VERSION ""

NS_ :

BS_:

BU_: IFV_VFP External_Tool IFV_Host MRR

BO_ 3221225472 VECTOR__INDEPENDENT_SIG_MSG: 0 Vector__XXX
 SG_ CAN_SERV_ALIGN_UPDATES_DONE : 0|8@0+ (1,0) [0|255] "" Vector__XXX
 SG_ CAN_SENSOR_VANGLE_OFFSET : 0|8@0+ (0.0625,-8) [-8|7.9375] "deg" Vector__XXX
 SG_ CAN_SENSOR_FOV_VER : 0|8@0+ (1,0) [0|255] "deg" Vector__XXX
 SG_ CAN_AUTO_ALIGN_VANGLE_QF : 0|1@0+ (1,0) [0|1] "" Vector__XXX
 SG_ CAN_AUTO_ALIGN_VANGLE_REF : 0|10@0+ (0.03125,-10) [-10|21.96875] "deg" Vector__XXX
 SG_ CAN_AUTO_ALIGN_VANGLE : 0|10@0+ (0.03125,-10) [-10|21.96875] "deg" Vector__XXX
 SG_ CAN_MMIC_Temp4 : 0|8@0+ (1,-50) [-50|205] "C" Vector__XXX
 SG_ CAN_MMIC_Temp3 : 0|8@0+ (1,-50) [-50|205] "C" Vector__XXX
 SG_ CAN_MMIC_Temp2 : 0|8@0+ (1,-50) [-50|205] "C" Vector__XXX
 SG_ CAN_Processor_Temp2 : 0|8@0+ (1,-50) [-50|205] "C" Vector__XXX
 SG_ CAN_CHECKSUM : 0|8@0+ (1,0) [0|255] "" Vector__XXX
 SG_ CAN_COUNTER : 0|4@0+ (1,0) [0|15] "" Vector__XXX
 SG_ CAN_VEHICLE_MODE : 0|4@0+ (1,0) [0|15] "" Vector__XXX
 SG_ CAN_USC_CAL_VER_MAJOR : 0|16@0+ (1,0) [0|65535] "" Vector__XXX
 SG_ CAN_USC_CAL_VER_MINOR : 0|16@0+ (1,0) [0|65535] "" Vector__XXX
 SG_ CAN_SMC_CAL_VER_MAJOR : 0|16@0+ (1,0) [0|65535] "" Vector__XXX
 SG_ CAN_HW_VERSION : 0|32@0+ (1,0) [0|4294967295] "" Vector__XXX
 SG_ CAN_FAC_TGT_MTG_SPACE_VER : 0|8@0+ (1,-128) [-128|127] "cm" Vector__XXX
 SG_ CAN_ANGLE_MISALIGNMENT_VER : 0|10@0+ (0.03125,-10) [-10|21.96875] "deg" Vector__XXX
 SG_ CAN_ANGLE_MOUNTING_VOFFSET : 0|8@0+ (0.0625,-8) [-8|7.9375] "deg" Vector__XXX
 SG_ CAN_LATCH_FAULTS : 0|64@0+ (1,0) [0|100] "" Vector__XXX
 SG_ CAN_ACTIVE_FAULTS : 0|64@0+ (1,0) [0|1.8446744074E+019] "" Vector__XXX
 SG_ CAN_HISTORY_FAULTS : 0|64@0+ (1,0) [0|1.8446744074E+019] "" Vector__XXX
 SG_ CAN_SERV_ALIGN_ENABLE : 0|1@0+ (1,0) [0|1] "" Vector__XXX
 SG_ CAN_LONG_MOUNTING_OFFSET : 0|8@0+ (0.015625,-2) [-2|1.984375] "" Vector__XXX
 SG_ CAN_BEAMWIDTH_VERT : 0|7@0+ (0.125,0) [0|15.875] "deg" Vector__XXX
 SG_ CAN_VEHICLE_SPEED_CALC_QF : 0|2@0+ (1,0) [0|3] "" Vector__XXX
 SG_ CAN_SMC_CAL_VER_MAJOR : 0|16@0+ (1,0) [0|65535] "" Vector__XXX
 SG_ v1_8_SupplyOutofRange_A_b3_4 : 0|1@0+ (1,0) [0|1] "" Vector__XXX
 SG_ v1_8_SupplyOutofRange_H_b3_4 : 0|1@0+ (1,0) [0|1] "" Vector__XXX
 SG_ Radar_Internal_Error_A_b7_7 : 0|1@0+ (1,0) [0|1] "" Vector__XXX
 SG_ DSP_to_Host_ChksumFault_A_b7_5 : 0|1@0+ (1,0) [0|1] "" Vector__XXX
 SG_ Host_to_DSP_ChksumFault_A_b7_4 : 0|1@0+ (1,0) [0|1] "" Vector__XXX
 SG_ ARM_to_DSP_ChksumFault_A_b7_3 : 0|1@0+ (1,0) [0|1] "" Vector__XXX
 SG_ DSP_to_ARM_ChksumFault_A_b7_2 : 0|1@0+ (1,0) [0|1] "" Vector__XXX
 SG_ Host_to_ARM_ChksumFault_A_b7_1 : 0|1@0+ (1,0) [0|1] "" Vector__XXX
 SG_ ARM_to_Host_ChksumFault_A_b7_0 : 0|1@0+ (1,0) [0|1] "" Vector__XXX
 SG_ LoopBwOutofRange_A_b6_7 : 0|1@0+ (1,0) [0|1] "" Vector__XXX
 SG_ DSPLoopOverrunFault_A_b6_6 : 0|1@0+ (1,0) [0|1] "" Vector__XXX
 SG_ TuningSensitivityFault_A_b6_4 : 0|1@0+ (1,0) [0|1] "" Vector__XXX
 SG_ SatTuningFreqFault_A_b6_3 : 0|1@0+ (1,0) [0|1] "" Vector__XXX
 SG_ LocalOscPwrFault_A_b6_2 : 0|1@0+ (1,0) [0|1] "" Vector__XXX
 SG_ TransmitterPwrFault_A_b6_1 : 0|1@0+ (1,0) [0|1] "" Vector__XXX
 SG_ XCVRDevSpiFault_A_b5_5 : 0|1@0+ (1,0) [0|1] "" Vector__XXX
 SG_ FreqSynthDevSpiFault_A_b5_4 : 0|1@0+ (1,0) [0|1] "" Vector__XXX
 SG_ AmpDevSpiFault_A_b5_3 : 0|1@0+ (1,0) [0|1] "" Vector__XXX
 SG_ Sidelobe_Blockage_A_b5_2 : 0|1@0+ (1,0) [0|1] "" Vector__XXX
 SG_ TD_Blockage_A_b5_1 : 0|1@0+ (1,0) [0|1] "" Vector__XXX
 SG_ CW_MNR_Blockage_A_b5_0 : 0|1@0+ (1,0) [0|1] "" Vector__XXX
 SG_ ECUTempHighFault_A_b4_7 : 0|1@0+ (1,0) [0|1] "" Vector__XXX
 SG_ TransmitterTempHigh_A_b4_6 : 0|1@0+ (1,0) [0|1] "" Vector__XXX
 SG_ AlignRoutineFailed_A_b4_5 : 0|1@0+ (1,0) [0|1] "" Vector__XXX
 SG_ UnreasonableRadarData_A_b4_4 : 0|1@0+ (1,0) [0|1] "" Vector__XXX
 SG_ MicroPTempHighFault_A_b4_3 : 0|1@0+ (1,0) [0|1] "" Vector__XXX
 SG_ VertAlignOutofRange_A_b4_2 : 0|1@0+ (1,0) [0|1] "" Vector__XXX
 SG_ HorzAlignOutofRange_A_b4_1 : 0|1@0+ (1,0) [0|1] "" Vector__XXX
 SG_ FactAlignMode_A_b4_0 : 0|1@0+ (1,0) [0|1] "" Vector__XXX
 SG_ BatteryLowFault_A_b3_7 : 0|1@0+ (1,0) [0|1] "" Vector__XXX
 SG_ BatteryHighFault_A_b3_6 : 0|1@0+ (1,0) [0|1] "" Vector__XXX
 SG_ v1_25_SupplyOutofRange_A_b3_5 : 0|1@0+ (1,0) [0|1] "" Vector__XXX
 SG_ ThermistorOutofRange_A_b3_3 : 0|1@0+ (1,0) [0|1] "" Vector__XXX
 SG_ v3_3_DacSpOutofRange_A_b3_2 : 0|1@0+ (1,0) [0|1] "" Vector__XXX
 SG_ v3_3_RawSpOutofRange_A_b3_1 : 0|1@0+ (1,0) [0|1] "" Vector__XXX
 SG_ v5_0_SupplyOutofRange_A_b3_0 : 0|1@0+ (1,0) [0|1] "" Vector__XXX
 SG_ TransmitterIDFault_A_b2_7 : 0|1@0+ (1,0) [0|1] "" Vector__XXX
 SG_ VFPPCANDataRangeChkFault_A_b2_3 : 0|1@0+ (1,0) [0|1] "" Vector__XXX
 SG_ VFPPCANMissingMsgFault_A_b2_2 : 0|1@0+ (1,0) [0|1] "" Vector__XXX
 SG_ HostPCANMissingMsgFault_A_b2_1 : 0|1@0+ (1,0) [0|1] "" Vector__XXX
 SG_ PCANBusOffFault_A_b2_0 : 0|1@0+ (1,0) [0|1] "" Vector__XXX
 SG_ InstructSetChkFault_A_b1_5 : 0|1@0+ (1,0) [0|1] "" Vector__XXX
 SG_ StackOvflowFault_A_b1_4 : 0|1@0+ (1,0) [0|1] "" Vector__XXX
 SG_ WatchdogFault_A_b1_3 : 0|1@0+ (1,0) [0|1] "" Vector__XXX
 SG_ PLLLockFault_A_b1_2 : 0|1@0+ (1,0) [0|1] "" Vector__XXX
 SG_ RAMMemTestFault_A_b1_0 : 0|1@0+ (1,0) [0|1] "" Vector__XXX
 SG_ USCValFault_A_b0_7 : 0|1@0+ (1,0) [0|1] "" Vector__XXX
 SG_ ClkMonFailFault_A_b0_6 : 0|1@0+ (1,0) [0|1] "" Vector__XXX
 SG_ PgmFlowFault_A_b0_5 : 0|1@0+ (1,0) [0|1] "" Vector__XXX
 SG_ SMCChksumFault_A_b0_4 : 0|1@0+ (1,0) [0|1] "" Vector__XXX
 SG_ KAMChksumFault_A_b0_2 : 0|1@0+ (1,0) [0|1] "" Vector__XXX
 SG_ ProgCalFlashChksumFault_A_b0_1 : 0|1@0+ (1,0) [0|1] "" Vector__XXX
 SG_ AppFlashChksumFault_A_b0_0 : 0|1@0+ (1,0) [0|1] "" Vector__XXX
 SG_ CB_140_IMUXAxisClbrtdNL_A_bB_7 : 0|1@0+ (1,0) [0|1] "" Vector__XXX
 SG_ CB_130_IMULonAccSecV_A_bB_6 : 0|1@0+ (1,0) [0|1] "" Vector__XXX
 SG_ CB_140_IMULatACCSecV_A_bB_5 : 0|1@0+ (1,0) [0|1] "" Vector__XXX
 SG_ CB_140_IMUDataMsk_A_bB_4 : 0|1@0+ (1,0) [0|1] "" Vector__XXX
 SG_ Host_CB_CAN_BusOff_A_bB_3 : 0|1@0+ (1,0) [0|1] "" Vector__XXX
 SG_ HighDeltaMisalign_A_bB_2 : 0|1@0+ (1,0) [0|1] "" Vector__XXX
 SG_ CB_170_ABS_Missing_A_bB_1 : 0|1@0+ (1,0) [0|1] "" Vector__XXX
 SG_ Unexpected_Reset_Fault_A_bB_0 : 0|1@0+ (1,0) [0|1] "" Vector__XXX
 SG_ CB_140_IMULatAccSecAval_A_bA_7 : 0|1@0+ (1,0) [0|1] "" Vector__XXX
 SG_ CB_130_IMUYawRtSecAval_A_bA_6 : 0|1@0+ (1,0) [0|1] "" Vector__XXX
 SG_ CB_130_IMULonAccSecAval_A_bA_5 : 0|1@0+ (1,0) [0|1] "" Vector__XXX
 SG_ CB_140_IMUChksumSecProt_A_bA_1 : 0|1@0+ (1,0) [0|1] "" Vector__XXX
 SG_ CB_130_IMUChksumPriProt_A_bA_0 : 0|1@0+ (1,0) [0|1] "" Vector__XXX
 SG_ VINNotProg_A_b9_7 : 0|1@0+ (1,0) [0|1] "" Vector__XXX
 SG_ VehConfigNotProg_A_b9_6 : 0|1@0+ (1,0) [0|1] "" Vector__XXX
 SG_ VIN_Mismatch_A_b9_5 : 0|1@0+ (1,0) [0|1] "" Vector__XXX
 SG_ CB_140_IMUYawRtSecV_A_b9_4 : 0|1@0+ (1,0) [0|1] "" Vector__XXX
 SG_ CB_140_IMULonAccPriV_A_b9_3 : 0|1@0+ (1,0) [0|1] "" Vector__XXX
 SG_ CB_130_IMULonAccPriAval_A_b9_2 : 0|1@0+ (1,0) [0|1] "" Vector__XXX
 SG_ CB_130_IMULatAccPrimV_A_b9_0 : 0|1@0+ (1,0) [0|1] "" Vector__XXX
 SG_ CB_130_IMUYawRtPriV_A_b9_1 : 0|1@0+ (1,0) [0|1] "" Vector__XXX
 SG_ Cam_202_SysYawRtV_A_b8_7 : 0|1@0+ (1,0) [0|1] "" Vector__XXX
 SG_ Cam_020_SysYawRtV_A_b8_6 : 0|1@0+ (1,0) [0|1] "" Vector__XXX
 SG_ Host_020_SysVehSpdV_A_b8_5 : 0|1@0+ (1,0) [0|1] "" Vector__XXX
 SG_ CB_140_IMURollCntSecARC_A_b8_4 : 0|1@0+ (1,0) [0|1] "" Vector__XXX
 SG_ CB_130_IMURollCntPriARC_A_b8_3 : 0|1@0+ (1,0) [0|1] "" Vector__XXX
 SG_ CB_140_IMUYawLonAccMiss_A_b8_2 : 0|1@0+ (1,0) [0|1] "" Vector__XXX
 SG_ CB_130_IMUYawLatAccMiss_A_b8_1 : 0|1@0+ (1,0) [0|1] "" Vector__XXX
 SG_ CB_140_IMUXAxisClbrtdNL_H_bB_7 : 0|1@0+ (1,0) [0|1] "" Vector__XXX
 SG_ CB_130_IMULonAccSecV_H_bB_6 : 0|1@0+ (1,0) [0|1] "" Vector__XXX
 SG_ CB_140_IMULatACCSecV_H_bB_5 : 0|1@0+ (1,0) [0|1] "" Vector__XXX
 SG_ CB_140_IMUDataMsk_H_bB_4 : 0|1@0+ (1,0) [0|1] "" Vector__XXX
 SG_ Host_CB_CAN_BusOff_H_bB_3 : 0|1@0+ (1,0) [0|1] "" Vector__XXX
 SG_ HighDeltaMisalign_H_bB_2 : 0|1@0+ (1,0) [0|1] "" Vector__XXX
 SG_ CB_170_ABS_Missing_H_bB_1 : 0|1@0+ (1,0) [0|1] "" Vector__XXX
 SG_ Unexpected_Reset_Fault_H_bB_0 : 0|1@0+ (1,0) [0|1] "" Vector__XXX
 SG_ CB_140_IMULatAccSecAval_H_bA_7 : 0|1@0+ (1,0) [0|1] "" Vector__XXX
 SG_ CB_130_IMUYawRtSecAval_H_bA_6 : 0|1@0+ (1,0) [0|1] "" Vector__XXX
 SG_ CB_130_IMULonAccSecAval_H_bA_5 : 0|1@0+ (1,0) [0|1] "" Vector__XXX
 SG_ CB_140_IMUChksumSecProt_H_bA_1 : 0|1@0+ (1,0) [0|1] "" Vector__XXX
 SG_ CB_130_IMUChksumPriProt_H_bA_0 : 0|1@0+ (1,0) [0|1] "" Vector__XXX
 SG_ VINNotProg_H_b9_7 : 0|1@0+ (1,0) [0|1] "" Vector__XXX
 SG_ VehConfigNotProg_H_b9_6 : 0|1@0+ (1,0) [0|1] "" Vector__XXX
 SG_ VIN_Mismatch_H_b9_5 : 0|1@0+ (1,0) [0|1] "" Vector__XXX
 SG_ CB_140_IMUYawRtSecV_H_b9_4 : 0|1@0+ (1,0) [0|1] "" Vector__XXX
 SG_ CB_140_IMULonAccPriV_H_b9_3 : 0|1@0+ (1,0) [0|1] "" Vector__XXX
 SG_ CB_130_IMULonAccPriAval_H_b9_2 : 0|1@0+ (1,0) [0|1] "" Vector__XXX
 SG_ CB_130_IMULatAccPrimV_H_b9_0 : 0|1@0+ (1,0) [0|1] "" Vector__XXX
 SG_ CB_130_IMUYawRtPriV_H_b9_1 : 0|1@0+ (1,0) [0|1] "" Vector__XXX
 SG_ Cam_202_SysYawRtV_H_b8_7 : 0|1@0+ (1,0) [0|1] "" Vector__XXX
 SG_ Cam_020_SysYawRtV_H_b8_6 : 0|1@0+ (1,0) [0|1] "" Vector__XXX
 SG_ Host_020_SysVehSpdV_H_b8_5 : 0|1@0+ (1,0) [0|1] "" Vector__XXX
 SG_ CB_140_IMURollCntSecARC_H_b8_4 : 0|1@0+ (1,0) [0|1] "" Vector__XXX
 SG_ CB_130_IMURollCntPriARC_H_b8_3 : 0|1@0+ (1,0) [0|1] "" Vector__XXX
 SG_ CB_140_IMUYawLonAccMiss_H_b8_2 : 0|1@0+ (1,0) [0|1] "" Vector__XXX
 SG_ CB_130_IMUYawLatAccMiss_H_b8_1 : 0|1@0+ (1,0) [0|1] "" Vector__XXX
 SG_ Radar_Internal_Error_H_b7_7 : 0|1@0+ (1,0) [0|1] "" Vector__XXX
 SG_ DSP_to_Host_ChksumFault_H_b7_5 : 0|1@0+ (1,0) [0|1] "" Vector__XXX
 SG_ Host_to_DSP_ChksumFault_H_b7_4 : 0|1@0+ (1,0) [0|1] "" Vector__XXX
 SG_ ARM_to_DSP_ChksumFault_H_b7_3 : 0|1@0+ (1,0) [0|1] "" Vector__XXX
 SG_ DSP_to_ARM_ChksumFault_H_b7_2 : 0|1@0+ (1,0) [0|1] "" Vector__XXX
 SG_ Host_to_ARM_ChksumFault_H_b7_1 : 0|1@0+ (1,0) [0|1] "" Vector__XXX
 SG_ ARM_to_Host_ChksumFault_H_b7_0 : 0|1@0+ (1,0) [0|1] "" Vector__XXX
 SG_ LoopBwOutofRange_H_b6_7 : 0|1@0+ (1,0) [0|1] "" Vector__XXX
 SG_ DSPLoopOverrunFault_H_b6_6 : 0|1@0+ (1,0) [0|1] "" Vector__XXX
 SG_ TuningSensitivityFault_H_b6_4 : 0|1@0+ (1,0) [0|1] "" Vector__XXX
 SG_ SatTuningFreqFault_H_b6_3 : 0|1@0+ (1,0) [0|1] "" Vector__XXX
 SG_ LocalOscPwrFault_H_b6_2 : 0|1@0+ (1,0) [0|1] "" Vector__XXX
 SG_ TransmitterPwrFault_H_b6_1 : 0|1@0+ (1,0) [0|1] "" Vector__XXX
 SG_ XCVRDevSpiFault_H_b5_5 : 0|1@0+ (1,0) [0|1] "" Vector__XXX
 SG_ FreqSynthDevSpiFault_H_b5_4 : 0|1@0+ (1,0) [0|1] "" Vector__XXX
 SG_ AmpDevSpiFault_H_b5_3 : 0|1@0+ (1,0) [0|1] "" Vector__XXX
 SG_ Sidelobe_Blockage_H_b5_2 : 0|1@0+ (1,0) [0|1] "" Vector__XXX
 SG_ TD_Blockage_H_b5_1 : 0|1@0+ (1,0) [0|1] "" Vector__XXX
 SG_ CW_MNR_Blockage_H_b5_0 : 0|1@0+ (1,0) [0|1] "" Vector__XXX
 SG_ ECUTempHighFault_H_b4_7 : 0|1@0+ (1,0) [0|1] "" Vector__XXX
 SG_ TransmitterTempHigh_H_b4_6 : 0|1@0+ (1,0) [0|1] "" Vector__XXX
 SG_ AlignRoutineFailed_H_b4_5 : 0|1@0+ (1,0) [0|1] "" Vector__XXX
 SG_ UnreasonableRadarData_H_b4_4 : 0|1@0+ (1,0) [0|1] "" Vector__XXX
 SG_ MicroPTempHighFault_H_b4_3 : 0|1@0+ (1,0) [0|1] "" Vector__XXX
 SG_ VertAlignOutofRange_H_b4_2 : 0|1@0+ (1,0) [0|1] "" Vector__XXX
 SG_ HorzAlignOutofRange_H_b4_1 : 0|1@0+ (1,0) [0|1] "" Vector__XXX
 SG_ FactAlignMode_H_b4_0 : 0|1@0+ (1,0) [0|1] "" Vector__XXX
 SG_ BatteryLowFault_H_b3_7 : 0|1@0+ (1,0) [0|1] "" Vector__XXX
 SG_ BatteryHighFault_H_b3_6 : 0|1@0+ (1,0) [0|1] "" Vector__XXX
 SG_ v1_25_SupplyOutofRange_H_b3_5 : 0|1@0+ (1,0) [0|1] "" Vector__XXX
 SG_ ThermistorOutofRange_H_b3_3 : 0|1@0+ (1,0) [0|1] "" Vector__XXX
 SG_ v3_3_DacSpOutofRange_H_b3_2 : 0|1@0+ (1,0) [0|1] "" Vector__XXX
 SG_ v3_3_RawSpOutofRange_H_b3_1 : 0|1@0+ (1,0) [0|1] "" Vector__XXX
 SG_ v5_0_SupplyOutofRange_H_b3_0 : 0|1@0+ (1,0) [0|1] "" Vector__XXX
 SG_ TransmitterIDFault_H_b2_7 : 0|1@0+ (1,0) [0|1] "" Vector__XXX
 SG_ VFPPCANDataRangeChkFault_H_b2_3 : 0|1@0+ (1,0) [0|1] "" Vector__XXX
 SG_ VFPPCANMissingMsgFault_H_b2_2 : 0|1@0+ (1,0) [0|1] "" Vector__XXX
 SG_ HostPCANMissingMsgFault_H_b2_1 : 0|1@0+ (1,0) [0|1] "" Vector__XXX
 SG_ PCANBusOffFault_H_b2_0 : 0|1@0+ (1,0) [0|1] "" Vector__XXX
 SG_ InstructSetChkFault_H_b1_5 : 0|1@0+ (1,0) [0|1] "" Vector__XXX
 SG_ StackOvflowFault_H_b1_4 : 0|1@0+ (1,0) [0|1] "" Vector__XXX
 SG_ WatchdogFault_H_b1_3 : 0|1@0+ (1,0) [0|1] "" Vector__XXX
 SG_ PLLLockFault_H_b1_2 : 0|1@0+ (1,0) [0|1] "" Vector__XXX
 SG_ RAMMemTestFault_H_b1_0 : 0|1@0+ (1,0) [0|1] "" Vector__XXX
 SG_ USCValFault_H_b0_7 : 0|1@0+ (1,0) [0|1] "" Vector__XXX
 SG_ ClkMonFailFault_H_b0_6 : 0|1@0+ (1,0) [0|1] "" Vector__XXX
 SG_ PgmFlowFault_H_b0_5 : 0|1@0+ (1,0) [0|1] "" Vector__XXX
 SG_ SMCChksumFault_H_b0_4 : 0|1@0+ (1,0) [0|1] "" Vector__XXX
 SG_ KAMChksumFault_H_b0_2 : 0|1@0+ (1,0) [0|1] "" Vector__XXX
 SG_ ProgCalFlashChksumFault_H_b0_1 : 0|1@0+ (1,0) [0|1] "" Vector__XXX
 SG_ AppFlashChksumFault_H_b0_0 : 0|1@0+ (1,0) [0|1] "" Vector__XXX
 SG_ FSRACCBrkngReqDenied : 0|1@0+ (1,0) [0|1] "" Vector__XXX
 SG_ BrkSysExtHldCpbltyFld : 0|1@0+ (1,0) [0|1] "" Vector__XXX
 SG_ BrkSysAutBrkTrgtDclV : 0|1@0+ (1,0) [0|1] "" Vector__XXX
 SG_ BrkSysAutBrkActDclV : 0|1@0+ (1,0) [0|1] "" Vector__XXX
 SG_ BrkSysPlsStat : 0|2@0+ (1,0) [0|3] "" Vector__XXX
 SG_ VehMvngStat : 0|1@0+ (1,0) [0|1] "" Vector__XXX
 SG_ BrkSysAutBrkStat : 0|2@0+ (1,0) [0|3] "" Vector__XXX
 SG_ AvgWhlBrkPrstEst : 0|17@0+ (0.1,0) [0|13107.1] "kPa" Vector__XXX
 SG_ BrkSysAutBrkActDcl : 0|12@0- (0.01,0) [-20.48|20.47] "m/s^2" Vector__XXX
 SG_ BrkSysAutBrkTrgtDcl : 0|12@0- (0.01,0) [-20.48|20.47] "m/s^2" Vector__XXX
 SG_ MRR_IMUChkSumSecFault : 0|1@0+ (1,0) [0|1] "" Vector__XXX
 SG_ MRR_IMUSecPlausFault : 0|1@0+ (1,0) [0|1] "" Vector__XXX
 SG_ MRR_IMUPriPlausFault : 0|1@0+ (1,0) [0|1] "" Vector__XXX
 SG_ MRR_IMUChkSumPriFault : 0|1@0+ (1,0) [0|1] "" Vector__XXX
 SG_ MRR_IMURollCntSecFault : 0|1@0+ (1,0) [0|1] "" Vector__XXX
 SG_ MRR_IMURollCntPriFault : 0|1@0+ (1,0) [0|1] "" Vector__XXX
 SG_ ACC_Fail_Radar : 0|1@0+ (1,0) [0|1] "" Vector__XXX
 SG_ MRR_PCANBusOffFault : 0|1@0+ (1,0) [0|1] "" Vector__XXX
 SG_ MRR_HOST_PCAN_Missing_MsgFault : 0|1@0+ (1,0) [0|1] "" Vector__XXX
 SG_ MRR_VFP_PCAN_Missing_MsgFault : 0|1@0+ (1,0) [0|1] "" Vector__XXX
 SG_ MRR_BatteryHighFault : 0|1@0+ (1,0) [0|1] "" Vector__XXX
 SG_ MRR_BatteryLowFault : 0|1@0+ (1,0) [0|1] "" Vector__XXX
 SG_ MRR_SysVehSpd_ValidityFault : 0|1@0+ (1,0) [0|1] "" Vector__XXX
 SG_ MRR_CameraMod_SysYawRt_ValidityF : 0|1@0+ (1,0) [0|1] "" Vector__XXX
 SG_ MRR_CameraMod_CompYawRt_Validity : 0|1@0+ (1,0) [0|1] "" Vector__XXX
 SG_ MRR_IMULonAccPriV_ValidityFault : 0|1@0+ (1,0) [0|1] "" Vector__XXX
 SG_ MRR_IMULonAccSecAvalFault : 0|1@0+ (1,0) [0|1] "" Vector__XXX
 SG_ MRR_IMUYawRtSecAvalFault : 0|1@0+ (1,0) [0|1] "" Vector__XXX
 SG_ MRR_IMULatAccSecAvalFault : 0|1@0+ (1,0) [0|1] "" Vector__XXX
 SG_ MRR_Automatic_Braking_Status_CB_ : 0|1@0+ (1,0) [0|1] "" Vector__XXX
 SG_ MRR_Host_CB_CAN_Bus_Off : 0|1@0+ (1,0) [0|1] "" Vector__XXX
 SG_ MRR_IMUDataMskFault : 0|1@0+ (1,0) [0|1] "" Vector__XXX
 SG_ MRR_IMULonAccSecVFault : 0|1@0+ (1,0) [0|1] "" Vector__XXX
 SG_ MRR_IMUXAxisClbrtd_Not_Learn : 0|1@0+ (1,0) [0|1] "" Vector__XXX
 SG_ CAN_VFP_TIMESTAMP : 0|64@0+ (1,0) [0|1.84467440737096E+019] "us" Vector__XXX
 SG_ MRR_xcp_daq_resp_byte7 : 0|8@0+ (1,0) [0|255] "" Vector__XXX
 SG_ MRR_xcp_daq_resp_byte6 : 0|8@0+ (1,0) [0|255] "" Vector__XXX
 SG_ MRR_xcp_daq_resp_byte5 : 0|8@0+ (1,0) [0|255] "" Vector__XXX
 SG_ MRR_xcp_daq_resp_byte4 : 0|8@0+ (1,0) [0|255] "" Vector__XXX
 SG_ MRR_xcp_daq_resp_byte3 : 0|8@0+ (1,0) [0|255] "" Vector__XXX
 SG_ MRR_xcp_daq_resp_byte2 : 0|8@0+ (1,0) [0|255] "" Vector__XXX
 SG_ MRR_xcp_daq_resp_byte1 : 0|8@0+ (1,0) [0|255] "" Vector__XXX
 SG_ MRR_xcp_daq_resp_byte0 : 0|8@0+ (1,0) [0|255] "" Vector__XXX
 SG_ MRR_xcp_dto_resp_byte7 : 0|8@0+ (1,0) [0|255] "" Vector__XXX
 SG_ MRR_xcp_dto_resp_byte6 : 0|8@0+ (1,0) [0|255] "" Vector__XXX
 SG_ MRR_xcp_dto_resp_byte5 : 0|8@0+ (1,0) [0|255] "" Vector__XXX
 SG_ MRR_xcp_dto_resp_byte4 : 0|8@0+ (1,0) [0|255] "" Vector__XXX
 SG_ MRR_xcp_dto_resp_byte3 : 0|8@0+ (1,0) [0|255] "" Vector__XXX
 SG_ MRR_xcp_dto_resp_byte2 : 0|8@0+ (1,0) [0|255] "" Vector__XXX
 SG_ MRR_xcp_dto_resp_byte1 : 0|8@0+ (1,0) [0|255] "" Vector__XXX
 SG_ MRR_xcp_dto_resp_byte0 : 0|8@0+ (1,0) [0|255] "" Vector__XXX
 SG_ MRR_xcp_dto_cmd_byte7 : 0|8@0+ (1,0) [0|255] "" Vector__XXX
 SG_ MRR_xcp_dto_cmd_byte6 : 0|8@0+ (1,0) [0|255] "" Vector__XXX
 SG_ MRR_xcp_dto_cmd_byte5 : 0|8@0+ (1,0) [0|255] "" Vector__XXX
 SG_ MRR_xcp_dto_cmd_byte4 : 0|8@0+ (1,0) [0|255] "" Vector__XXX
 SG_ MRR_xcp_dto_cmd_byte3 : 0|8@0+ (1,0) [0|255] "" Vector__XXX
 SG_ MRR_xcp_dto_cmd_byte2 : 0|8@0+ (1,0) [0|255] "" Vector__XXX
 SG_ MRR_xcp_dto_cmd_byte1 : 0|8@0+ (1,0) [0|255] "" Vector__XXX
 SG_ MRR_xcp_dto_cmd_byte0 : 0|8@0+ (1,0) [0|255] "" Vector__XXX
 SG_ MRR_xcp_cto_resp_byte7 : 0|8@0+ (1,0) [0|255] "" Vector__XXX
 SG_ MRR_xcp_cto_resp_byte6 : 0|8@0+ (1,0) [0|255] "" Vector__XXX
 SG_ MRR_xcp_cto_resp_byte5 : 0|8@0+ (1,0) [0|255] "" Vector__XXX
 SG_ MRR_xcp_cto_resp_byte4 : 0|8@0+ (1,0) [0|255] "" Vector__XXX
 SG_ MRR_xcp_cto_resp_byte3 : 0|8@0+ (1,0) [0|255] "" Vector__XXX
 SG_ MRR_xcp_cto_resp_byte2 : 0|8@0+ (1,0) [0|255] "" Vector__XXX
 SG_ MRR_xcp_cto_resp_byte1 : 0|8@0+ (1,0) [0|255] "" Vector__XXX
 SG_ MRR_xcp_cto_resp_byte0 : 0|8@0+ (1,0) [0|255] "" Vector__XXX
 SG_ MRR_xcp_cto_cmd_byte7 : 0|8@0+ (1,0) [0|255] "" Vector__XXX
 SG_ MRR_xcp_cto_cmd_byte6 : 0|8@0+ (1,0) [0|255] "" Vector__XXX
 SG_ MRR_xcp_cto_cmd_byte5 : 0|8@0+ (1,0) [0|255] "" Vector__XXX
 SG_ MRR_xcp_cto_cmd_byte4 : 0|8@0+ (1,0) [0|255] "" Vector__XXX
 SG_ MRR_xcp_cto_cmd_byte3 : 0|8@0+ (1,0) [0|255] "" Vector__XXX
 SG_ MRR_xcp_cto_cmd_byte2 : 0|8@0+ (1,0) [0|255] "" Vector__XXX
 SG_ MRR_xcp_cto_cmd_byte1 : 0|8@0+ (1,0) [0|255] "" Vector__XXX
 SG_ MRR_xcp_cto_cmd_byte0 : 0|8@0+ (1,0) [0|255] "" Vector__XXX
 SG_ TesterFunctionalReq : 0|64@0+ (1,0) [0|1.84467E+019] "" Vector__XXX
 SG_ TesterPhysicalResCCM : 0|64@0+ (1,0) [0|1.84467E+019] "" Vector__XXX
 SG_ TesterPhysicalReqCCM : 0|64@0+ (1,0) [0|1.84467E+019] "" Vector__XXX
 SG_ CAN_SPEED_FRONT_LEFT_WHEEL : 0|15@0+ (0.01,0) [0|327.67] "rad/s" Vector__XXX
 SG_ CAN_SPEED_FRONT_RIGHT_WHEEL : 0|15@0+ (0.01,0) [0|327.67] "rad/s" Vector__XXX
 SG_ CAN_SPEED_REAR_LEFT_WHEEL : 0|15@0+ (0.01,0) [0|327.67] "rad/s" Vector__XXX
 SG_ CAN_SPEED_REAR_RIGHT_WHEEL : 0|15@0+ (0.01,0) [0|327.67] "rad/s" Vector__XXX
 SG_ Yaw_Rate_Reference_Valid : 0|1@0+ (1,0) [0|1] "boolean" Vector__XXX
 SG_ Yaw_Rate_Reference : 0|12@0- (0.03663,0) [-75|75] "deg/s" Vector__XXX
 SG_ CAN_VEH_LONG_ACCEL_QF : 0|2@0+ (1,0) [0|3] "" Vector__XXX
 SG_ CAN_VEH_LONG_ACCEL : 0|13@0+ (0.01,-40) [-40|41.89] "m/s^2" Vector__XXX
 SG_ FSM_Yaw_Rate_Valid : 0|1@0+ (1,0) [0|1] "" Vector__XXX
 SG_ FSM_Yaw_Rate : 0|16@0- (0.0078125,0) [-75|75] "deg/s" Vector__XXX
 SG_ CAN_VEHICLE_INDEX_4FA : 0|14@0+ (1,0) [0|16383] "" Vector__XXX
 SG_ FSM_Vehicle_Velocity : 0|16@0- (0.0078125,0) [-256|255.9921875] "m/s" Vector__XXX
 SG_ CAN_STEERING_WHL_ANGLE_QF : 0|1@0+ (1,0) [0|1] "" Vector__XXX
 SG_ FSM_Vehicle_Velocity_Valid : 0|1@0+ (1,0) [0|1] "" Vector__XXX
 SG_ CAN_STEERING_WHL_ANGLE : 0|15@0+ (0.1,-1600) [-1600|1676.7] "deg" Vector__XXX
 SG_ CAN_FCW_SENSITIVITY_LEVEL : 0|2@0+ (1,0) [0|3] "" Vector__XXX
 SG_ CAN_VEHICLE_STATIONARY : 0|1@0+ (1,0) [0|1] "" Vector__XXX
 SG_ CAN_INTF_MINOR_VERSION : 0|3@0+ (1,0) [0|7] "" Vector__XXX
 SG_ CAN_INTF_MAJOR_VERSION : 0|5@0+ (1,0) [0|31] "" Vector__XXX
 SG_ CAN_BRAKE_PEDAL : 0|2@0+ (1,0) [0|2] "" Vector__XXX
 SG_ CAN_HIGH_WHEEL_SLIP : 0|1@0+ (1,0) [0|1] "" Vector__XXX
 SG_ CAN_TURN_SIGNAL_STATUS : 0|2@0+ (1,0) [0|3] "" Vector__XXX
 SG_ CAN_WASHER_FRONT_CMD : 0|1@0+ (1,0) [0|1] "" Vector__XXX
 SG_ CAN_WIPER_FRONT_CMD : 0|1@0+ (1,0) [0|1] "" Vector__XXX
 SG_ CAN_WIPER_SPEED_INFO : 0|3@0+ (1,0) [0|7] "" Vector__XXX
 SG_ CAN_REVERSE_GEAR : 0|1@0+ (1,0) [0|1] "" Vector__XXX
 SG_ CAN_BEAM_SHAPE_ACTUAL_RIGHT : 0|2@0+ (1,0) [0|3] "" Vector__XXX
 SG_ CAN_BEAM_SHAPE_ACTUAL_LEFT : 0|2@0+ (1,0) [0|3] "" Vector__XXX
 SG_ CAN_MAIN_BEAM_INDICATION : 0|1@0+ (1,0) [0|1] "" Vector__XXX
 SG_ CAN_VEHICLE_INDEX : 0|16@0+ (1,0) [0|65535] "" Vector__XXX
 SG_ CAN_SEQUENCE_NUMBER : 0|16@0+ (1,0) [0|65535] "" Vector__XXX
 SG_ CAN_SERIAL_NUMBER : 0|40@0+ (1,0) [0|1099511627800] "" Vector__XXX
 SG_ CAN_INST_MODE : 0|16@0+ (1,0) [0|65535] "" Vector__XXX
 SG_ CAN_SW_Version : 0|24@0+ (1,0) [0|16777215] "" Vector__XXX
 SG_ CAN_PBL_Version : 0|24@0+ (1,0) [0|16777215] "" Vector__XXX
 SG_ CAN_YAW_RATE_CALC_QF : 0|2@0+ (1,0) [0|3] "" Vector__XXX
 SG_ CAN_YAW_RATE_CALC : 0|13@0+ (0.03125,-100) [-100|100] "deg/s" Vector__XXX
 SG_ CAN_YAW_RATE_BIAS : 0|10@0+ (0.03125,-16) [-16|15.96875] "deg/s" Vector__XXX
 SG_ CAN_VEHICLE_SPEED_CALC : 0|14@0+ (0.01,0) [0|100] "m/s" Vector__XXX
 SG_ CAN_VEH_SPD_COMP_FACTOR : 0|16@0+ (3.0517578125E-006,0.9) [0.9|1.09999694824219] "" Vector__XXX
 SG_ CAN_LROS_CARCFGVEHTYPE_FORD : 0|8@0+ (1,0) [0|255] "" Vector__XXX
 SG_ CAN_LROS_CARCFGENGINE_FORD : 0|8@0+ (1,0) [0|255] "" Vector__XXX
 SG_ CAN_NUMBER_OF_TRACKS_STAT : 0|8@0+ (1,0) [0|255] "" Vector__XXX
 SG_ CAN_NUMBER_OF_TRACKS_MOV : 0|8@0+ (1,0) [0|255] "" Vector__XXX
 SG_ CAN_TD_SCAN_COUNTER : 0|4@0+ (1,0) [0|15] "" Vector__XXX
 SG_ CAN_FOUND_TARGET : 0|1@0+ (1,0) [0|1] "" Vector__XXX
 SG_ CAN_BLOCKAGE_TD : 0|1@0+ (1,0) [0|1] "" Vector__XXX
 SG_ VIN_part3 : 0|8@0+ (1,0) [0|255] "" Vector__XXX
 SG_ VIN_part2 : 0|64@0+ (1,0) [0|1.84467E+019] "" Vector__XXX
 SG_ VIN_part1 : 0|64@0+ (1,0) [0|1.84467E+019] "" Vector__XXX
 SG_ CAN_ODOMETER_FORD : 0|24@0+ (1,0) [0|16777214] "km" Vector__XXX
 SG_ CAN_POWER_SUPP_FORD : 0|3@0+ (1,0) [0|7] "" Vector__XXX
 SG_ CAN_POWER_MOTIVE_FORD : 0|2@0+ (1,0) [0|3] "" Vector__XXX
 SG_ CAN_CRUISE_STATUS_FORD : 0|3@0+ (1,0) [0|7] "" Vector__XXX
 SG_ CAN_VEH_BATT_VOLT : 0|8@0+ (0.0625,0) [0|15.875] "V" Vector__XXX
 SG_ CAN_GEAR_POSITION : 0|8@0+ (1,0) [0|15] "" Vector__XXX
 SG_ CAN_AMBIENT_TEMP : 0|10@0+ (0.25,-128) [-128|127.75] "C" Vector__XXX
 SG_ CAN_IGN_STATUS : 0|4@0+ (1,0) [0|15] "" Vector__XXX
 SG_ CAN_GLOBALREALTIME_FORD : 0|32@0+ (0.1,0) [0|429496729.5] "s" Vector__XXX
 SG_ CAN_VEH_SPEED_FORD : 0|16@0+ (0.01,0) [0|655.33] "kph" Vector__XXX
 SG_ CAN_VEH_YAW_FORD : 0|16@0+ (0.0002,-6.5) [-6.5|6.6066] "rad/s" Vector__XXX
 SG_ CAN_PCAN_MINOR_IFV_VFP : 0|4@0+ (1,0) [0|15] "" Vector__XXX
 SG_ CAN_PCAN_MAJOR_IFV_VFP : 0|4@0+ (1,0) [0|15] "" Vector__XXX
 SG_ CAN_PCAN_MINOR_IFV_HOST : 0|4@0+ (1,0) [0|15] "" Vector__XXX
 SG_ CAN_PCAN_MAJOR_IFV_HOST : 0|4@0+ (1,0) [0|15] "" Vector__XXX
 SG_ CAN_SENSOR_POLARITY : 0|1@0+ (1,0) [0|1] "" Vector__XXX
 SG_ CAN_SENSOR_LAT_OFFSET : 0|16@0+ (0.01,0) [0|655.35] "cm" Vector__XXX
 SG_ CAN_SENSOR_LONG_OFFSET : 0|16@0+ (0.01,0) [0|655.35] "cm" Vector__XXX
 SG_ CAN_SENSOR_HANGLE_OFFSET : 0|8@0+ (0.0625,-8) [-8|7.9375] "deg" Vector__XXX
 SG_ CAN_SENSOR_FOV_HOR : 0|8@0+ (1,0) [0|255] "deg" Vector__XXX
 SG_ CAN_DOPPLER_COVERAGE : 0|8@0+ (1,-128) [-128|127] "m/s" Vector__XXX
 SG_ CAN_RANGE_COVERAGE : 0|8@0+ (1,0) [0|255] "m" Vector__XXX
 SG_ CAN_AUTO_ALIGN_HANGLE_QF : 0|2@0+ (1,0) [0|3] "" Vector__XXX
 SG_ CAN_ALIGNMENT_STATUS : 0|4@0+ (1,0) [0|11] "" Vector__XXX
 SG_ CAN_ALIGNMENT_STATE : 0|3@0+ (1,0) [0|7] "" Vector__XXX
 SG_ CAN_AUTO_ALIGN_HANGLE_REF : 0|10@0+ (0.0003412178,-0.1745329) [-0.1745329|0.1745329094] "rad" Vector__XXX
 SG_ CAN_AUTO_ALIGN_HANGLE : 0|10@0+ (0.0003412178,-0.1745329) [-0.1745329|0.1745329094] "rad" Vector__XXX
 SG_ CAN_DET_TIME_SINCE_MEAS : 0|11@0+ (0.1,0) [0|204.7] "ms" Vector__XXX
 SG_ CAN_SENSOR_TIME_STAMP : 0|32@0+ (0.1,0) [0|429496729.5] "ms" Vector__XXX
 SG_ CAN_ALIGN_UPDATES_DONE : 0|16@0+ (1,0) [0|65535] "" Vector__XXX
 SG_ CAN_SCAN_INDEX : 0|16@0+ (1,0) [0|65535] "" Vector__XXX
 SG_ CAN_NUMBER_OF_DET : 0|8@0+ (1,0) [0|255] "" Vector__XXX
 SG_ CAN_LOOK_ID : 0|2@0+ (1,0) [0|3] "" Vector__XXX
 SG_ CAN_LOOK_INDEX : 0|16@0+ (1,0) [0|65535] "" Vector__XXX
 SG_ CAN_FAC_ALIGN_CMD_3 : 0|1@0+ (1,0) [0|1] "" Vector__XXX
 SG_ CAN_FAC_ALIGN_CMD_2 : 0|1@0+ (1,0) [0|1] "" Vector__XXX
 SG_ CAN_FAC_ALIGN_CMD_1 : 0|1@0+ (1,0) [0|1] "" Vector__XXX
 SG_ CAN_BATT_VOLTS : 0|8@0+ (0.08,0) [0|20.4] "V" Vector__XXX
 SG_ CAN_1_25_V : 0|8@0+ (0.08,0) [0|20.4] "V" Vector__XXX
 SG_ CAN_5_V : 0|8@0+ (0.08,0) [0|20.4] "V" Vector__XXX
 SG_ CAN_3_3_V_RAW : 0|8@0+ (0.08,0) [0|20.4] "V" Vector__XXX
 SG_ CAN_3_3_V_DAC : 0|8@0+ (0.08,0) [0|20.4] "V" Vector__XXX
 SG_ CAN_MMIC_Temp1 : 0|8@0+ (1,-50) [-50|205] "C" Vector__XXX
 SG_ CAN_Processor_Thermistor : 0|8@0+ (1,-50) [-50|205] "C" Vector__XXX
 SG_ CAN_Processor_Temp1 : 0|8@0+ (1,-50) [-50|205] "C" Vector__XXX
 SG_ CAN_VEHICLE_STAT : 0|1@0+ (1,0) [0|1] "" Vector__XXX
 SG_ CAN_DAY_NIGHT_STATUS : 0|1@0+ (1,0) [0|1] "" Vector__XXX
 SG_ CAN_WIPER_STATUS : 0|1@0+ (1,0) [0|1] "" Vector__XXX
 SG_ CAN_YAW_RATE_VALIDITY : 0|1@0+ (1,0) [0|1] "" Vector__XXX
 SG_ CAN_YAW_RATE : 0|12@0+ (0.0625,-128) [-128|127.9375] "deg/s" Vector__XXX
 SG_ CAN_VEHICLE_SPEED_VALIDITY : 0|1@0+ (1,0) [0|1] "" Vector__XXX
 SG_ CAN_VEHICLE_SPEED_DIRECTION : 0|1@0+ (1,0) [0|1] "" Vector__XXX
 SG_ CAN_VEHICLE_SPEED : 0|11@0+ (0.0625,0) [0|127.9375] "m/s" Vector__XXX
 SG_ CAN_SENSITIVITY_PROFILE_SELECT : 0|2@0+ (1,0) [0|3] "" Vector__XXX
 SG_ CAN_STOP_FREQUENCY_FRML : 0|10@0+ (5,76000) [76000|81115] "MHz" Vector__XXX
 SG_ CAN_STOP_FREQUENCY_FRLL : 0|10@0+ (5,76000) [76000|81115] "MHz" Vector__XXX
 SG_ CAN_PRP_FACTOR_FRML : 0|9@0+ (0.1,0) [0|51.1] "us" Vector__XXX
 SG_ CAN_PRP_FACTOR_FRLL : 0|9@0+ (0.1,0) [0|51.1] "us" Vector__XXX
 SG_ CAN_DESIRED_SWEEP_BW_FRML : 0|8@0+ (10,50) [50|2600] "MHz" Vector__XXX
 SG_ CAN_DESIRED_SWEEP_BW_FRLL : 0|8@0+ (10,50) [50|2600] "MHz" Vector__XXX
 SG_ CAN_LATERAL_MOUNTING_OFFSET : 0|8@0+ (0.015625,-2) [-2|1.984375] "" Vector__XXX
 SG_ CAN_FAC_PLATE_TILT_NUMBER : 0|4@0+ (1,0) [0|15] "" Vector__XXX
 SG_ CAN_FAC_PLATE_TILT_ANGLE : 0|6@0+ (0.25,-8) [-8|7.75] "deg" Vector__XXX
 SG_ CAN_FAC_PLATE_POSITIONS_TOTAL : 0|4@0+ (1,0) [0|15] "" Vector__XXX
 SG_ CAN_FAC_ALIGN_MAX_NT : 0|7@0+ (1,0) [0|127] "" Vector__XXX
 SG_ CAN_FAC_TGT_RANGE_R2M : 0|8@0+ (0.0625,0) [0|15.9375] "m" Vector__XXX
 SG_ CAN_FAC_TGT_RANGE_M2T : 0|8@0+ (0.0625,0) [0|15.9375] "m" Vector__XXX
 SG_ CAN_FAC_TGT_RANGE_1 : 0|8@0+ (0.0625,0) [0|15.9375] "m" Vector__XXX
 SG_ CAN_FAC_TGT_MTG_SPACE_HOR : 0|8@0+ (1,-128) [-128|127] "cm" Vector__XXX
 SG_ CAN_FAC_TGT_MTG_OFFSET : 0|8@0+ (1,-128) [-128|127] "cm" Vector__XXX
 SG_ CAN_FAC_ALIGN_SAMP_REQ : 0|7@0+ (1,0) [0|127] "" Vector__XXX
 SG_ CAN_SERV_ALIGN_UPDATES_NEED : 0|8@0+ (1,0) [0|255] "" Vector__XXX
 SG_ CAN_SERV_ALIGN_TYPE : 0|1@0+ (1,0) [0|1] "" Vector__XXX
 SG_ CAN_RADAR_HEIGHT : 0|7@0+ (1,0) [0|127] "cm" Vector__XXX
 SG_ CAN_RADAR_FOV_MR : 0|7@0+ (1,0) [0|127] "deg" Vector__XXX
 SG_ CAN_RADAR_FOV_LR : 0|5@0+ (1,0) [0|31] "deg" Vector__XXX
 SG_ CAN_ALIGN_ENABLE : 0|2@0+ (1,0) [0|3] "" Vector__XXX
 SG_ CAN_ANGLE_MOUNTING_HOFFSET : 0|8@0+ (0.0625,-8) [-8|7.9375] "deg" Vector__XXX
 SG_ CAN_AALIGN_AVG_CTR_TOTAL : 0|3@0+ (250,250) [250|2000] "" Vector__XXX
 SG_ CAN_MRR_UPSIDE_DOWN : 0|1@0+ (1,0) [0|1] "" Vector__XXX
 SG_ CAN_BLOCKAGE_FILTER_OUTPUT : 0|4@0+ (1,0) [0|15] "dB" Vector__XXX
 SG_ CAN_ANGLE_MISALIGNMENT_HOR : 0|10@0+ (0.03125,-10) [-10|21.96875] "deg" Vector__XXX
 SG_ CAN_USE_ANGLE_MISALIGNMENT : 0|1@0+ (1,0) [0|1] "" Vector__XXX
 SG_ CAN_BLOCKAGE_DISABLE : 0|1@0+ (1,0) [0|1] "" Vector__XXX
 SG_ CAN_SCAN_INDEX_ACK : 0|16@0+ (1,0) [0|65535] "" Vector__XXX
 SG_ CAN_STOP_FREQUENCY_NRML : 0|10@0+ (5,76000) [76000|81115] "MHz" Vector__XXX
 SG_ CAN_PRP_FACTOR_NRML : 0|9@0+ (0.1,0) [0|51.1] "us" Vector__XXX
 SG_ CAN_DESIRED_SWEEP_BW_NRML : 0|8@0+ (10,50) [50|2600] "MHz" Vector__XXX
 SG_ CAN_RADIATION_CTRL : 0|1@0+ (1,0) [0|1] "" Vector__XXX
 SG_ CAN_STOP_FREQUENCY_NRLL : 0|10@0+ (5,76000) [76000|81115] "MHz" Vector__XXX
 SG_ CAN_PRP_FACTOR_NRLL : 0|9@0+ (0.1,0) [0|51.1] "us" Vector__XXX
 SG_ CAN_DESIRED_SWEEP_BW_NRLL : 0|8@0+ (10,50) [50|2600] "MHz" Vector__XXX
 SG_ CAN_USC_SECTION_COMPATIBILITY : 0|16@0+ (1,0) [0|65535] "" Vector__XXX
 SG_ CAN_PCAN_MINOR_MRR : 0|4@0+ (1,0) [0|15] "" Vector__XXX
 SG_ CAN_PCAN_MAJOR_MRR : 0|4@0+ (1,0) [0|15] "" Vector__XXX
 SG_ CAN_BLOCKAGE_SIDELOBE_FILTER_VAL : 0|4@0+ (1,0) [0|15] "" Vector__XXX
 SG_ CAN_RADAR_ALIGN_INCOMPLETE : 0|1@0+ (1,0) [0|1] "" Vector__XXX
 SG_ CAN_BLOCKAGE_SIDELOBE : 0|1@0+ (1,0) [0|1] "" Vector__XXX
 SG_ CAN_BLOCKAGE_MNR : 0|1@0+ (1,0) [0|1] "" Vector__XXX
 SG_ CAN_RADAR_EXT_COND_NOK : 0|1@0+ (1,0) [0|1] "" Vector__XXX
 SG_ CAN_RADAR_ALIGN_OUT_RANGE : 0|1@0+ (1,0) [0|1] "" Vector__XXX
 SG_ CAN_RADAR_ALIGN_NOT_START : 0|1@0+ (1,0) [0|1] "" Vector__XXX
 SG_ CAN_RADAR_OVERHEAT_ERROR : 0|1@0+ (1,0) [0|1] "" Vector__XXX
 SG_ CAN_RADAR_NOT_OP : 0|1@0+ (1,0) [0|1] "" Vector__XXX
 SG_ CAN_XCVR_OPERATIONAL : 0|1@0+ (1,0) [0|1] "" Vector__XXX

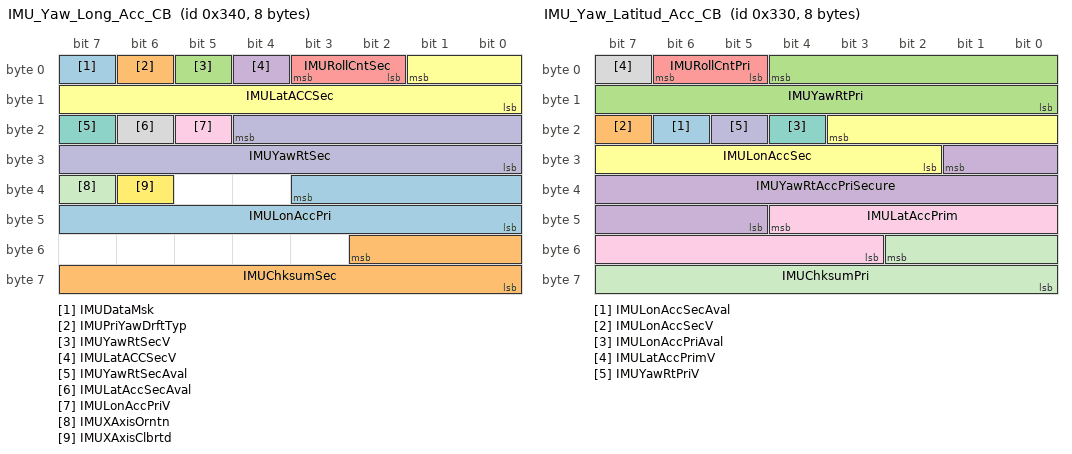
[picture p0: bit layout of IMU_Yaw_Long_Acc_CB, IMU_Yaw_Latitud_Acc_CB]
BO_ 832 IMU_Yaw_Long_Acc_CB: 8 MRR
 SG_ IMUDataMsk : 7|1@0+ (1,0) [0|1] ""  IFV_Host
 SG_ IMUPriYawDrftTyp : 6|1@0+ (1,0) [0|1] ""  IFV_Host
 SG_ IMUYawRtSecV : 5|1@0+ (1,0) [0|1] ""  IFV_Host
 SG_ IMULatACCSecV : 4|1@0+ (1,0) [0|1] ""  IFV_Host
 SG_ IMURollCntSec : 3|2@0+ (1,0) [0|3] ""  IFV_Host
 SG_ IMULatACCSec : 1|10@0- (0.0625,0) [-32|31.9375] "m/s^2"  IFV_Host
 SG_ IMUYawRtSecAval : 23|1@0+ (1,0) [0|1] ""  IFV_Host
 SG_ IMULatAccSecAval : 22|1@0+ (1,0) [0|1] ""  IFV_Host
 SG_ IMULonAccPriV : 21|1@0+ (1,0) [0|1] ""  IFV_Host
 SG_ IMUYawRtSec : 20|13@0- (0.024,0) [0|0] "deg/sec"  IFV_Host
 SG_ IMUXAxisOrntn : 39|1@0+ (1,0) [0|1] ""  IFV_Host
 SG_ IMUXAxisClbrtd : 38|1@0+ (1,0) [0|1] ""  IFV_Host
 SG_ IMULonAccPri : 35|12@0- (0.015625,0) [-32|31.984375] "m/s^2"  IFV_Host
 SG_ IMUChksumSec : 50|11@0+ (1,0) [0|2047] ""  IFV_Host

BO_ 816 IMU_Yaw_Latitud_Acc_CB: 8 MRR
 SG_ IMULonAccSecAval : 22|1@0+ (1,0) [0|1] ""  IFV_Host
 SG_ IMULonAccSecV : 23|1@0+ (1,0) [0|1] ""  IFV_Host
 SG_ IMUYawRtPri : 4|13@0- (0.024,0) [-98.304|98.28] "deg/sec"  IFV_Host
 SG_ IMUYawRtAccPriSecure : 25|13@0- (0.25,0) [-1024|1023.75] "deg/s^2"  IFV_Host
 SG_ IMURollCntPri : 6|2@0+ (1,0) [0|3] ""  IFV_Host
 SG_ IMULonAccSec : 19|10@0- (0.0625,0) [-32|31.9375] "m/s^2"  IFV_Host
 SG_ IMULonAccPriAval : 20|1@0+ (1,0) [0|1] ""  IFV_Host
 SG_ IMULatAccPrimV : 7|1@0+ (1,0) [0|1] ""  IFV_Host
 SG_ IMULatAccPrim : 44|10@0- (0.0625,0) [-32|31.9375] "m/s^2"  IFV_Host
 SG_ IMUYawRtPriV : 21|1@0+ (1,0) [0|1] ""  IFV_Host
 SG_ IMUChksumPri : 50|11@0+ (1,0) [0|2047] ""  IFV_Host

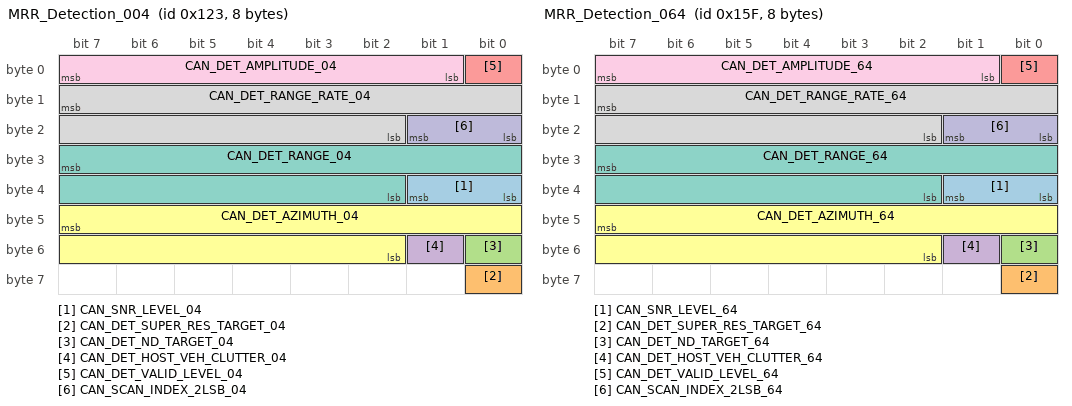
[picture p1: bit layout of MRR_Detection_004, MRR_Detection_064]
BO_ 291 MRR_Detection_004: 8 MRR
 SG_ CAN_SNR_LEVEL_04 : 33|2@0+ (1,0) [0|3] ""  IFV_VFP
 SG_ CAN_DET_SUPER_RES_TARGET_04 : 56|1@0+ (1,0) [0|1] ""  IFV_VFP
 SG_ CAN_DET_ND_TARGET_04 : 48|1@0+ (1,0) [0|1] ""  IFV_VFP
 SG_ CAN_DET_HOST_VEH_CLUTTER_04 : 49|1@0+ (1,0) [0|1] ""  IFV_VFP
 SG_ CAN_DET_VALID_LEVEL_04 : 0|1@0+ (1,0) [0|1] ""  IFV_VFP
 SG_ CAN_DET_AZIMUTH_04 : 47|14@0+ (0.0003834,-3.1416) [-3.1416|3.1396422] "rad"  IFV_VFP
 SG_ CAN_DET_RANGE_04 : 31|14@0+ (0.015625,0) [0|255.984375] "m"  IFV_VFP
 SG_ CAN_DET_RANGE_RATE_04 : 15|14@0+ (0.015625,-128) [-128|127.984375] "m/s"  IFV_VFP
 SG_ CAN_DET_AMPLITUDE_04 : 7|7@0+ (1,-64) [-64|63] "dBsm"  IFV_VFP
 SG_ CAN_SCAN_INDEX_2LSB_04 : 17|2@0+ (1,0) [0|3] ""  IFV_VFP

BO_ 351 MRR_Detection_064: 8 MRR
 SG_ CAN_SNR_LEVEL_64 : 33|2@0+ (1,0) [0|3] ""  IFV_VFP
 SG_ CAN_DET_SUPER_RES_TARGET_64 : 56|1@0+ (1,0) [0|1] ""  IFV_VFP
 SG_ CAN_DET_ND_TARGET_64 : 48|1@0+ (1,0) [0|1] ""  IFV_VFP
 SG_ CAN_DET_HOST_VEH_CLUTTER_64 : 49|1@0+ (1,0) [0|1] ""  IFV_VFP
 SG_ CAN_DET_VALID_LEVEL_64 : 0|1@0+ (1,0) [0|1] ""  IFV_VFP
 SG_ CAN_DET_AZIMUTH_64 : 47|14@0+ (0.0003834,-3.1416) [-3.1416|3.1396422] "rad"  IFV_VFP
 SG_ CAN_DET_RANGE_64 : 31|14@0+ (0.015625,0) [0|255.984375] "m"  IFV_VFP
 SG_ CAN_DET_RANGE_RATE_64 : 15|14@0+ (0.015625,-128) [-128|127.984375] "m/s"  IFV_VFP
 SG_ CAN_DET_AMPLITUDE_64 : 7|7@0+ (1,-64) [-64|63] "dBsm"  IFV_VFP
 SG_ CAN_SCAN_INDEX_2LSB_64 : 17|2@0+ (1,0) [0|3] ""  IFV_VFP

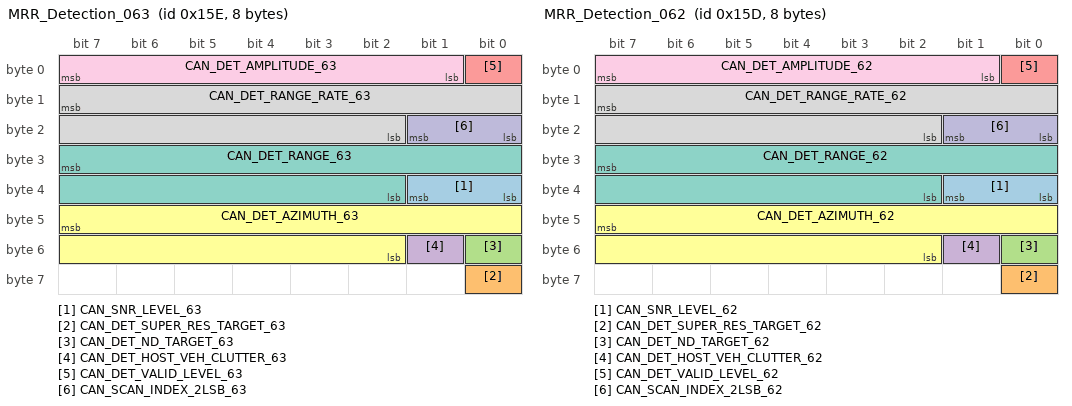
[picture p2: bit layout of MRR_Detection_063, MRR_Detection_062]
BO_ 350 MRR_Detection_063: 8 MRR
 SG_ CAN_SNR_LEVEL_63 : 33|2@0+ (1,0) [0|3] ""  IFV_VFP
 SG_ CAN_DET_SUPER_RES_TARGET_63 : 56|1@0+ (1,0) [0|1] ""  IFV_VFP
 SG_ CAN_DET_ND_TARGET_63 : 48|1@0+ (1,0) [0|1] ""  IFV_VFP
 SG_ CAN_DET_HOST_VEH_CLUTTER_63 : 49|1@0+ (1,0) [0|1] ""  IFV_VFP
 SG_ CAN_DET_VALID_LEVEL_63 : 0|1@0+ (1,0) [0|1] ""  IFV_VFP
 SG_ CAN_DET_AZIMUTH_63 : 47|14@0+ (0.0003834,-3.1416) [-3.1416|3.1396422] "rad"  IFV_VFP
 SG_ CAN_DET_RANGE_63 : 31|14@0+ (0.015625,0) [0|255.984375] "m"  IFV_VFP
 SG_ CAN_DET_RANGE_RATE_63 : 15|14@0+ (0.015625,-128) [-128|127.984375] "m/s"  IFV_VFP
 SG_ CAN_DET_AMPLITUDE_63 : 7|7@0+ (1,-64) [-64|63] "dBsm"  IFV_VFP
 SG_ CAN_SCAN_INDEX_2LSB_63 : 17|2@0+ (1,0) [0|3] ""  IFV_VFP

BO_ 349 MRR_Detection_062: 8 MRR
 SG_ CAN_SNR_LEVEL_62 : 33|2@0+ (1,0) [0|3] ""  IFV_VFP
 SG_ CAN_DET_SUPER_RES_TARGET_62 : 56|1@0+ (1,0) [0|1] ""  IFV_VFP
 SG_ CAN_DET_ND_TARGET_62 : 48|1@0+ (1,0) [0|1] ""  IFV_VFP
 SG_ CAN_DET_HOST_VEH_CLUTTER_62 : 49|1@0+ (1,0) [0|1] ""  IFV_VFP
 SG_ CAN_DET_VALID_LEVEL_62 : 0|1@0+ (1,0) [0|1] ""  IFV_VFP
 SG_ CAN_DET_AZIMUTH_62 : 47|14@0+ (0.0003834,-3.1416) [-3.1416|3.1396422] "rad"  IFV_VFP
 SG_ CAN_DET_RANGE_62 : 31|14@0+ (0.015625,0) [0|255.984375] "m"  IFV_VFP
 SG_ CAN_DET_RANGE_RATE_62 : 15|14@0+ (0.015625,-128) [-128|127.984375] "m/s"  IFV_VFP
 SG_ CAN_DET_AMPLITUDE_62 : 7|7@0+ (1,-64) [-64|63] "dBsm"  IFV_VFP
 SG_ CAN_SCAN_INDEX_2LSB_62 : 17|2@0+ (1,0) [0|3] ""  IFV_VFP

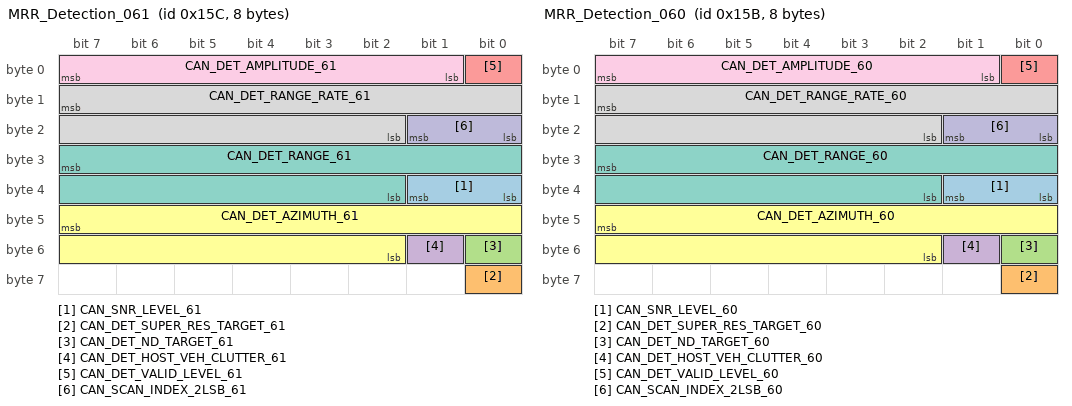
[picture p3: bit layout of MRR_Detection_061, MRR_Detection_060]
BO_ 348 MRR_Detection_061: 8 MRR
 SG_ CAN_SNR_LEVEL_61 : 33|2@0+ (1,0) [0|3] ""  IFV_VFP
 SG_ CAN_DET_SUPER_RES_TARGET_61 : 56|1@0+ (1,0) [0|1] ""  IFV_VFP
 SG_ CAN_DET_ND_TARGET_61 : 48|1@0+ (1,0) [0|1] ""  IFV_VFP
 SG_ CAN_DET_HOST_VEH_CLUTTER_61 : 49|1@0+ (1,0) [0|1] ""  IFV_VFP
 SG_ CAN_DET_VALID_LEVEL_61 : 0|1@0+ (1,0) [0|1] ""  IFV_VFP
 SG_ CAN_DET_AZIMUTH_61 : 47|14@0+ (0.0003834,-3.1416) [-3.1416|3.1396422] "rad"  IFV_VFP
 SG_ CAN_DET_RANGE_61 : 31|14@0+ (0.015625,0) [0|255.984375] "m"  IFV_VFP
 SG_ CAN_DET_RANGE_RATE_61 : 15|14@0+ (0.015625,-128) [-128|127.984375] "m/s"  IFV_VFP
 SG_ CAN_DET_AMPLITUDE_61 : 7|7@0+ (1,-64) [-64|63] "dBsm"  IFV_VFP
 SG_ CAN_SCAN_INDEX_2LSB_61 : 17|2@0+ (1,0) [0|3] ""  IFV_VFP

BO_ 347 MRR_Detection_060: 8 MRR
 SG_ CAN_SNR_LEVEL_60 : 33|2@0+ (1,0) [0|3] ""  IFV_VFP
 SG_ CAN_DET_SUPER_RES_TARGET_60 : 56|1@0+ (1,0) [0|1] ""  IFV_VFP
 SG_ CAN_DET_ND_TARGET_60 : 48|1@0+ (1,0) [0|1] ""  IFV_VFP
 SG_ CAN_DET_HOST_VEH_CLUTTER_60 : 49|1@0+ (1,0) [0|1] ""  IFV_VFP
 SG_ CAN_DET_VALID_LEVEL_60 : 0|1@0+ (1,0) [0|1] ""  IFV_VFP
 SG_ CAN_DET_AZIMUTH_60 : 47|14@0+ (0.0003834,-3.1416) [-3.1416|3.1396422] "rad"  IFV_VFP
 SG_ CAN_DET_RANGE_60 : 31|14@0+ (0.015625,0) [0|255.984375] "m"  IFV_VFP
 SG_ CAN_DET_RANGE_RATE_60 : 15|14@0+ (0.015625,-128) [-128|127.984375] "m/s"  IFV_VFP
 SG_ CAN_DET_AMPLITUDE_60 : 7|7@0+ (1,-64) [-64|63] "dBsm"  IFV_VFP
 SG_ CAN_SCAN_INDEX_2LSB_60 : 17|2@0+ (1,0) [0|3] ""  IFV_VFP

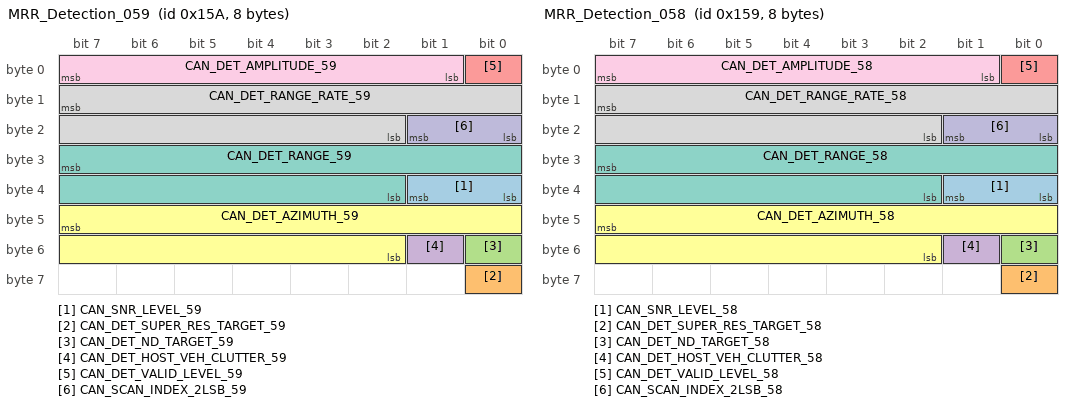
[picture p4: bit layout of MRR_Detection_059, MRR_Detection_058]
BO_ 346 MRR_Detection_059: 8 MRR
 SG_ CAN_SNR_LEVEL_59 : 33|2@0+ (1,0) [0|3] ""  IFV_VFP
 SG_ CAN_DET_SUPER_RES_TARGET_59 : 56|1@0+ (1,0) [0|1] ""  IFV_VFP
 SG_ CAN_DET_ND_TARGET_59 : 48|1@0+ (1,0) [0|1] ""  IFV_VFP
 SG_ CAN_DET_HOST_VEH_CLUTTER_59 : 49|1@0+ (1,0) [0|1] ""  IFV_VFP
 SG_ CAN_DET_VALID_LEVEL_59 : 0|1@0+ (1,0) [0|1] ""  IFV_VFP
 SG_ CAN_DET_AZIMUTH_59 : 47|14@0+ (0.0003834,-3.1416) [-3.1416|3.1396422] "rad"  IFV_VFP
 SG_ CAN_DET_RANGE_59 : 31|14@0+ (0.015625,0) [0|255.984375] "m"  IFV_VFP
 SG_ CAN_DET_RANGE_RATE_59 : 15|14@0+ (0.015625,-128) [-128|127.984375] "m/s"  IFV_VFP
 SG_ CAN_DET_AMPLITUDE_59 : 7|7@0+ (1,-64) [-64|63] "dBsm"  IFV_VFP
 SG_ CAN_SCAN_INDEX_2LSB_59 : 17|2@0+ (1,0) [0|3] ""  IFV_VFP

BO_ 345 MRR_Detection_058: 8 MRR
 SG_ CAN_SNR_LEVEL_58 : 33|2@0+ (1,0) [0|3] ""  IFV_VFP
 SG_ CAN_DET_SUPER_RES_TARGET_58 : 56|1@0+ (1,0) [0|1] ""  IFV_VFP
 SG_ CAN_DET_ND_TARGET_58 : 48|1@0+ (1,0) [0|1] ""  IFV_VFP
 SG_ CAN_DET_HOST_VEH_CLUTTER_58 : 49|1@0+ (1,0) [0|1] ""  IFV_VFP
 SG_ CAN_DET_VALID_LEVEL_58 : 0|1@0+ (1,0) [0|1] ""  IFV_VFP
 SG_ CAN_DET_AZIMUTH_58 : 47|14@0+ (0.0003834,-3.1416) [-3.1416|3.1396422] "rad"  IFV_VFP
 SG_ CAN_DET_RANGE_58 : 31|14@0+ (0.015625,0) [0|255.984375] "m"  IFV_VFP
 SG_ CAN_DET_RANGE_RATE_58 : 15|14@0+ (0.015625,-128) [-128|127.984375] "m/s"  IFV_VFP
 SG_ CAN_DET_AMPLITUDE_58 : 7|7@0+ (1,-64) [-64|63] "dBsm"  IFV_VFP
 SG_ CAN_SCAN_INDEX_2LSB_58 : 17|2@0+ (1,0) [0|3] ""  IFV_VFP

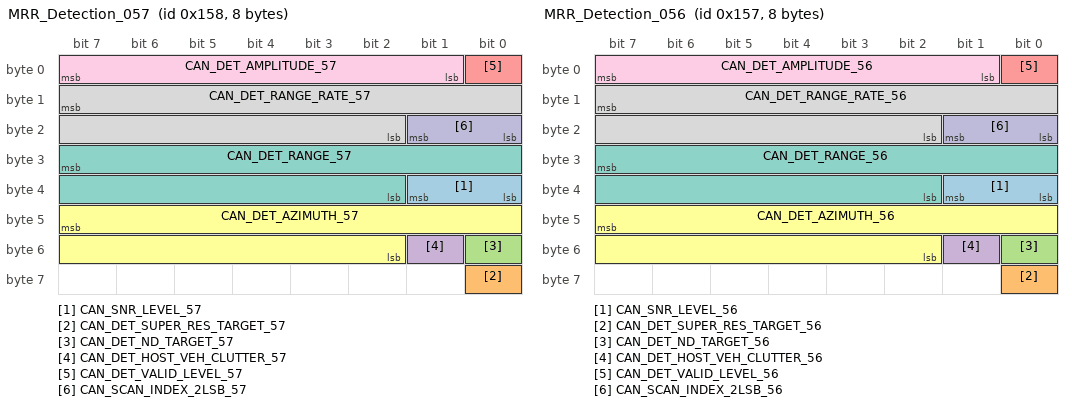
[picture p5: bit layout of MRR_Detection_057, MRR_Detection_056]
BO_ 344 MRR_Detection_057: 8 MRR
 SG_ CAN_SNR_LEVEL_57 : 33|2@0+ (1,0) [0|3] ""  IFV_VFP
 SG_ CAN_DET_SUPER_RES_TARGET_57 : 56|1@0+ (1,0) [0|1] ""  IFV_VFP
 SG_ CAN_DET_ND_TARGET_57 : 48|1@0+ (1,0) [0|1] ""  IFV_VFP
 SG_ CAN_DET_HOST_VEH_CLUTTER_57 : 49|1@0+ (1,0) [0|1] ""  IFV_VFP
 SG_ CAN_DET_VALID_LEVEL_57 : 0|1@0+ (1,0) [0|1] ""  IFV_VFP
 SG_ CAN_DET_AZIMUTH_57 : 47|14@0+ (0.0003834,-3.1416) [-3.1416|3.1396422] "rad"  IFV_VFP
 SG_ CAN_DET_RANGE_57 : 31|14@0+ (0.015625,0) [0|255.984375] "m"  IFV_VFP
 SG_ CAN_DET_RANGE_RATE_57 : 15|14@0+ (0.015625,-128) [-128|127.984375] "m/s"  IFV_VFP
 SG_ CAN_DET_AMPLITUDE_57 : 7|7@0+ (1,-64) [-64|63] "dBsm"  IFV_VFP
 SG_ CAN_SCAN_INDEX_2LSB_57 : 17|2@0+ (1,0) [0|3] ""  IFV_VFP

BO_ 343 MRR_Detection_056: 8 MRR
 SG_ CAN_SNR_LEVEL_56 : 33|2@0+ (1,0) [0|3] ""  IFV_VFP
 SG_ CAN_DET_SUPER_RES_TARGET_56 : 56|1@0+ (1,0) [0|1] ""  IFV_VFP
 SG_ CAN_DET_ND_TARGET_56 : 48|1@0+ (1,0) [0|1] ""  IFV_VFP
 SG_ CAN_DET_HOST_VEH_CLUTTER_56 : 49|1@0+ (1,0) [0|1] ""  IFV_VFP
 SG_ CAN_DET_VALID_LEVEL_56 : 0|1@0+ (1,0) [0|1] ""  IFV_VFP
 SG_ CAN_DET_AZIMUTH_56 : 47|14@0+ (0.0003834,-3.1416) [-3.1416|3.1396422] "rad"  IFV_VFP
 SG_ CAN_DET_RANGE_56 : 31|14@0+ (0.015625,0) [0|255.984375] "m"  IFV_VFP
 SG_ CAN_DET_RANGE_RATE_56 : 15|14@0+ (0.015625,-128) [-128|127.984375] "m/s"  IFV_VFP
 SG_ CAN_DET_AMPLITUDE_56 : 7|7@0+ (1,-64) [-64|63] "dBsm"  IFV_VFP
 SG_ CAN_SCAN_INDEX_2LSB_56 : 17|2@0+ (1,0) [0|3] ""  IFV_VFP

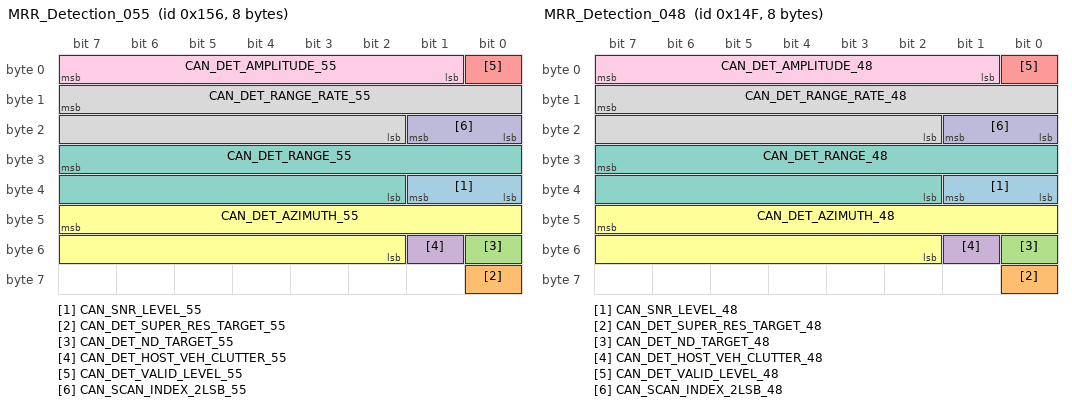
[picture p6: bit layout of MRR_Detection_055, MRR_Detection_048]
BO_ 342 MRR_Detection_055: 8 MRR
 SG_ CAN_SNR_LEVEL_55 : 33|2@0+ (1,0) [0|3] ""  IFV_VFP
 SG_ CAN_DET_SUPER_RES_TARGET_55 : 56|1@0+ (1,0) [0|1] ""  IFV_VFP
 SG_ CAN_DET_ND_TARGET_55 : 48|1@0+ (1,0) [0|1] ""  IFV_VFP
 SG_ CAN_DET_HOST_VEH_CLUTTER_55 : 49|1@0+ (1,0) [0|1] ""  IFV_VFP
 SG_ CAN_DET_VALID_LEVEL_55 : 0|1@0+ (1,0) [0|1] ""  IFV_VFP
 SG_ CAN_DET_AZIMUTH_55 : 47|14@0+ (0.0003834,-3.1416) [-3.1416|3.1396422] "rad"  IFV_VFP
 SG_ CAN_DET_RANGE_55 : 31|14@0+ (0.015625,0) [0|255.984375] "m"  IFV_VFP
 SG_ CAN_DET_RANGE_RATE_55 : 15|14@0+ (0.015625,-128) [-128|127.984375] "m/s"  IFV_VFP
 SG_ CAN_DET_AMPLITUDE_55 : 7|7@0+ (1,-64) [-64|63] "dBsm"  IFV_VFP
 SG_ CAN_SCAN_INDEX_2LSB_55 : 17|2@0+ (1,0) [0|3] ""  IFV_VFP

BO_ 335 MRR_Detection_048: 8 MRR
 SG_ CAN_SNR_LEVEL_48 : 33|2@0+ (1,0) [0|3] ""  IFV_VFP
 SG_ CAN_DET_SUPER_RES_TARGET_48 : 56|1@0+ (1,0) [0|1] ""  IFV_VFP
 SG_ CAN_DET_ND_TARGET_48 : 48|1@0+ (1,0) [0|1] ""  IFV_VFP
 SG_ CAN_DET_HOST_VEH_CLUTTER_48 : 49|1@0+ (1,0) [0|1] ""  IFV_VFP
 SG_ CAN_DET_VALID_LEVEL_48 : 0|1@0+ (1,0) [0|1] ""  IFV_VFP
 SG_ CAN_DET_AZIMUTH_48 : 47|14@0+ (0.0003834,-3.1416) [-3.1416|3.1396422] "rad"  IFV_VFP
 SG_ CAN_DET_RANGE_48 : 31|14@0+ (0.015625,0) [0|255.984375] "m"  IFV_VFP
 SG_ CAN_DET_RANGE_RATE_48 : 15|14@0+ (0.015625,-128) [-128|127.984375] "m/s"  IFV_VFP
 SG_ CAN_DET_AMPLITUDE_48 : 7|7@0+ (1,-64) [-64|63] "dBsm"  IFV_VFP
 SG_ CAN_SCAN_INDEX_2LSB_48 : 17|2@0+ (1,0) [0|3] ""  IFV_VFP

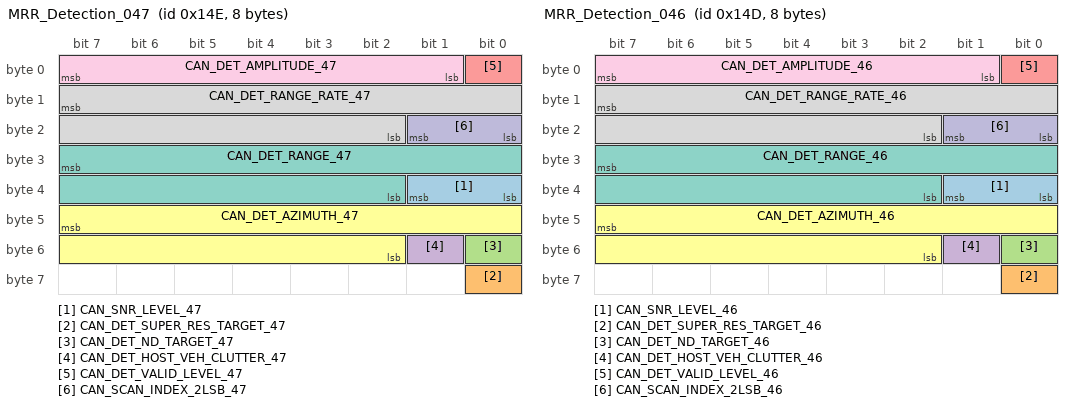
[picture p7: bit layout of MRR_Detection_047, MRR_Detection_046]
BO_ 334 MRR_Detection_047: 8 MRR
 SG_ CAN_SNR_LEVEL_47 : 33|2@0+ (1,0) [0|3] ""  IFV_VFP
 SG_ CAN_DET_SUPER_RES_TARGET_47 : 56|1@0+ (1,0) [0|1] ""  IFV_VFP
 SG_ CAN_DET_ND_TARGET_47 : 48|1@0+ (1,0) [0|1] ""  IFV_VFP
 SG_ CAN_DET_HOST_VEH_CLUTTER_47 : 49|1@0+ (1,0) [0|1] ""  IFV_VFP
 SG_ CAN_DET_VALID_LEVEL_47 : 0|1@0+ (1,0) [0|1] ""  IFV_VFP
 SG_ CAN_DET_AZIMUTH_47 : 47|14@0+ (0.0003834,-3.1416) [-3.1416|3.1396422] "rad"  IFV_VFP
 SG_ CAN_DET_RANGE_47 : 31|14@0+ (0.015625,0) [0|255.984375] "m"  IFV_VFP
 SG_ CAN_DET_RANGE_RATE_47 : 15|14@0+ (0.015625,-128) [-128|127.984375] "m/s"  IFV_VFP
 SG_ CAN_DET_AMPLITUDE_47 : 7|7@0+ (1,-64) [-64|63] "dBsm"  IFV_VFP
 SG_ CAN_SCAN_INDEX_2LSB_47 : 17|2@0+ (1,0) [0|3] ""  IFV_VFP

BO_ 333 MRR_Detection_046: 8 MRR
 SG_ CAN_SNR_LEVEL_46 : 33|2@0+ (1,0) [0|3] ""  IFV_VFP
 SG_ CAN_DET_SUPER_RES_TARGET_46 : 56|1@0+ (1,0) [0|1] ""  IFV_VFP
 SG_ CAN_DET_ND_TARGET_46 : 48|1@0+ (1,0) [0|1] ""  IFV_VFP
 SG_ CAN_DET_HOST_VEH_CLUTTER_46 : 49|1@0+ (1,0) [0|1] ""  IFV_VFP
 SG_ CAN_DET_VALID_LEVEL_46 : 0|1@0+ (1,0) [0|1] ""  IFV_VFP
 SG_ CAN_DET_AZIMUTH_46 : 47|14@0+ (0.0003834,-3.1416) [-3.1416|3.1396422] "rad"  IFV_VFP
 SG_ CAN_DET_RANGE_46 : 31|14@0+ (0.015625,0) [0|255.984375] "m"  IFV_VFP
 SG_ CAN_DET_RANGE_RATE_46 : 15|14@0+ (0.015625,-128) [-128|127.984375] "m/s"  IFV_VFP
 SG_ CAN_DET_AMPLITUDE_46 : 7|7@0+ (1,-64) [-64|63] "dBsm"  IFV_VFP
 SG_ CAN_SCAN_INDEX_2LSB_46 : 17|2@0+ (1,0) [0|3] ""  IFV_VFP

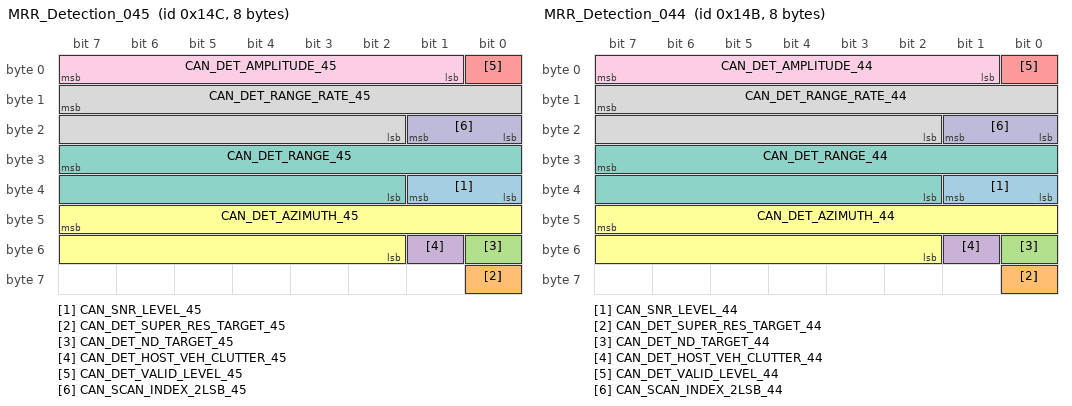
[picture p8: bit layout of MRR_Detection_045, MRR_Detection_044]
BO_ 332 MRR_Detection_045: 8 MRR
 SG_ CAN_SNR_LEVEL_45 : 33|2@0+ (1,0) [0|3] ""  IFV_VFP
 SG_ CAN_DET_SUPER_RES_TARGET_45 : 56|1@0+ (1,0) [0|1] ""  IFV_VFP
 SG_ CAN_DET_ND_TARGET_45 : 48|1@0+ (1,0) [0|1] ""  IFV_VFP
 SG_ CAN_DET_HOST_VEH_CLUTTER_45 : 49|1@0+ (1,0) [0|1] ""  IFV_VFP
 SG_ CAN_DET_VALID_LEVEL_45 : 0|1@0+ (1,0) [0|1] ""  IFV_VFP
 SG_ CAN_DET_AZIMUTH_45 : 47|14@0+ (0.0003834,-3.1416) [-3.1416|3.1396422] "rad"  IFV_VFP
 SG_ CAN_DET_RANGE_45 : 31|14@0+ (0.015625,0) [0|255.984375] "m"  IFV_VFP
 SG_ CAN_DET_RANGE_RATE_45 : 15|14@0+ (0.015625,-128) [-128|127.984375] "m/s"  IFV_VFP
 SG_ CAN_DET_AMPLITUDE_45 : 7|7@0+ (1,-64) [-64|63] "dBsm"  IFV_VFP
 SG_ CAN_SCAN_INDEX_2LSB_45 : 17|2@0+ (1,0) [0|3] ""  IFV_VFP

BO_ 331 MRR_Detection_044: 8 MRR
 SG_ CAN_SNR_LEVEL_44 : 33|2@0+ (1,0) [0|3] ""  IFV_VFP
 SG_ CAN_DET_SUPER_RES_TARGET_44 : 56|1@0+ (1,0) [0|1] ""  IFV_VFP
 SG_ CAN_DET_ND_TARGET_44 : 48|1@0+ (1,0) [0|1] ""  IFV_VFP
 SG_ CAN_DET_HOST_VEH_CLUTTER_44 : 49|1@0+ (1,0) [0|1] ""  IFV_VFP
 SG_ CAN_DET_VALID_LEVEL_44 : 0|1@0+ (1,0) [0|1] ""  IFV_VFP
 SG_ CAN_DET_AZIMUTH_44 : 47|14@0+ (0.0003834,-3.1416) [-3.1416|3.1396422] "rad"  IFV_VFP
 SG_ CAN_DET_RANGE_44 : 31|14@0+ (0.015625,0) [0|255.984375] "m"  IFV_VFP
 SG_ CAN_DET_RANGE_RATE_44 : 15|14@0+ (0.015625,-128) [-128|127.984375] "m/s"  IFV_VFP
 SG_ CAN_DET_AMPLITUDE_44 : 7|7@0+ (1,-64) [-64|63] "dBsm"  IFV_VFP
 SG_ CAN_SCAN_INDEX_2LSB_44 : 17|2@0+ (1,0) [0|3] ""  IFV_VFP

CM_ BO_ 3221225472 "This is a message for not used signals, created by Vector CANdb++ DBC OLE DB Provider.";
BA_DEF_  "Manufacturer" STRING ;
BA_DEF_ SG_  "CrossOver_InfoCAN" ENUM  "No","Yes";
BA_DEF_ SG_  "CrossOver_LIN" ENUM  "No","Yes";
BA_DEF_ SG_  "UsedOnPgmDBC" ENUM  "No","Yes";
BA_DEF_ SG_  "GenSigTimeoutTime_RCM" INT 0 100000;
BA_DEF_ SG_  "GenSigTimeoutTime_OCS" INT 0 100000;
BA_DEF_ SG_  "GenSigTimeoutTime_ABS_ESC" INT 0 100000;
BA_DEF_ SG_  "GenSigTimeoutTime_CCM" INT 0 100000;
BA_DEF_ SG_  "GenSigTimeoutTime_IPMA" INT 0 100000;
BA_DEF_ SG_  "GenSigTimeoutTime_SCCM" INT 0 100000;
BA_DEF_ SG_  "GenSigTimeoutTime_PSCM" INT 0 100000;
BA_DEF_ BO_  "EventRateOfChange" INT 10 10000;
BA_DEF_ SG_  "GenSigVtName" STRING ;
BA_DEF_ SG_  "GenSigVtEn" STRING ;
BA_DEF_  "GenNetworkMuxEn" STRING ;
BA_DEF_  "GenNetworkBaudrate" STRING ;
BA_DEF_  "GenNetworkName" STRING ;
BA_DEF_ SG_  "GenSigCmt" STRING ;
BA_DEF_  "GenRevisionDate" STRING ;
BA_DEF_  "GenRevision" STRING ;
BA_DEF_  "GenDescription" STRING ;
BA_DEF_  "GenCompany" STRING ;
BA_DEF_  "GenAuthor" STRING ;
BA_DEF_ BU_  "NmStationAddress" HEX 0 0;
BA_DEF_ SG_  "GenSigSendType" ENUM  "Cyclic","OnWrite","vector_leerstring","OnChange","vector_leerstring","IfActive","vector_leerstring","NoSigSendType";
BA_DEF_ SG_  "GenSigStartValue" INT 0 1000000000;
BA_DEF_ BO_  "GenMsgILSupport" ENUM  "No","Yes";
BA_DEF_ BO_  "GenMsgSendType" ENUM  "FixedPeriodic","Event","EnabledPeriodic","NotUsed","NotUsed","EventPeriodic","NotUsed","NotUsed","NoMsgSendType";
BA_DEF_ BO_  "GenMsgCycleTime" INT 0 100000;
BA_DEF_ BO_  "GenMsgDelayTime" INT 0 1000;
BA_DEF_ BO_  "GenMsgNrOfRepetition" INT 0 100;
BA_DEF_ BO_  "NetworkInitialization" ENUM  "No","Yes";
BA_DEF_ BU_  "ILUsed" ENUM  "No","Yes";
BA_DEF_ BU_  "PowerType" ENUM  "Switched","Latched","Sleep","vector_leerstring","vector_leerstring";
BA_DEF_ BU_  "NodeStartUpTime" INT 0 10000;
BA_DEF_ BU_  "NodeWakeUpTime" INT 0 10000;
BA_DEF_  "DBName" STRING ;
BA_DEF_  "BusType" STRING ;
BA_DEF_ SG_  "SystemSignalLongSymbol" STRING ;
BA_DEF_DEF_  "Manufacturer" "SGM";
BA_DEF_DEF_  "CrossOver_InfoCAN" "No";
BA_DEF_DEF_  "CrossOver_LIN" "No";
BA_DEF_DEF_  "UsedOnPgmDBC" "Yes";
BA_DEF_DEF_  "GenSigTimeoutTime_RCM" 0;
BA_DEF_DEF_  "GenSigTimeoutTime_OCS" 0;
BA_DEF_DEF_  "GenSigTimeoutTime_ABS_ESC" 0;
BA_DEF_DEF_  "GenSigTimeoutTime_CCM" 0;
BA_DEF_DEF_  "GenSigTimeoutTime_IPMA" 0;
BA_DEF_DEF_  "GenSigTimeoutTime_SCCM" 0;
BA_DEF_DEF_  "GenSigTimeoutTime_PSCM" 0;
BA_DEF_DEF_  "EventRateOfChange" 10000;
BA_DEF_DEF_  "GenSigVtName" "";
BA_DEF_DEF_  "GenSigVtEn" "";
BA_DEF_DEF_  "GenNetworkMuxEn" "FALSE";
BA_DEF_DEF_  "GenNetworkBaudrate" "500 kbps";
BA_DEF_DEF_  "GenNetworkName" "PCAN";
BA_DEF_DEF_  "GenSigCmt" "";
BA_DEF_DEF_  "GenRevisionDate" "Dec 19, 2014";
BA_DEF_DEF_  "GenRevision" "v02.00";
BA_DEF_DEF_  "GenDescription" "CAN bus that communicates the radar and the camera modules";
BA_DEF_DEF_  "GenCompany" "Delphi";
BA_DEF_DEF_  "GenAuthor" "Ana M. Uribe";
BA_DEF_DEF_  "NmStationAddress" 0;
BA_DEF_DEF_  "GenSigSendType" "NoSigSendType";
BA_DEF_DEF_  "GenSigStartValue" 0;
BA_DEF_DEF_  "GenMsgILSupport" "Yes";
BA_DEF_DEF_  "GenMsgSendType" "NoMsgSendType";
BA_DEF_DEF_  "GenMsgCycleTime" 0;
BA_DEF_DEF_  "GenMsgDelayTime" 0;
BA_DEF_DEF_  "GenMsgNrOfRepetition" 0;
BA_DEF_DEF_  "NetworkInitialization" "No";
BA_DEF_DEF_  "ILUsed" "Yes";
BA_DEF_DEF_  "PowerType" "Switched";
BA_DEF_DEF_  "NodeStartUpTime" 250;
BA_DEF_DEF_  "NodeWakeUpTime" 10;
BA_DEF_DEF_  "DBName" "";
BA_DEF_DEF_  "BusType" "CAN";
BA_DEF_DEF_  "SystemSignalLongSymbol" "";
BA_ "GenAuthor" "W.Sean";
BA_ "GenRevision" "v06.05";
BA_ "GenRevisionDate" "Jan 25, 2016";
BA_ "GenNetworkBaudrate" "500000";
BA_ "DBName" "PCAN";
BA_ "NmStationAddress" BU_ External_Tool 1;
BA_ "NmStationAddress" BU_ IFV_Host 188;
BA_ "NmStationAddress" BU_ MRR 33;
BA_ "GenMsgCycleTime" BO_ 832 25;
BA_ "GenMsgSendType" BO_ 832 0;
BA_ "GenMsgCycleTime" BO_ 816 25;
BA_ "GenMsgSendType" BO_ 816 0;
BA_ "GenMsgSendType" BO_ 291 1;
BA_ "GenMsgSendType" BO_ 351 1;
BA_ "GenMsgSendType" BO_ 350 1;
BA_ "GenMsgSendType" BO_ 349 1;
BA_ "GenMsgSendType" BO_ 348 1;
BA_ "GenMsgSendType" BO_ 347 1;
BA_ "GenMsgSendType" BO_ 346 1;
BA_ "GenMsgSendType" BO_ 345 1;
BA_ "GenMsgSendType" BO_ 344 1;
BA_ "GenMsgSendType" BO_ 343 1;
BA_ "GenMsgSendType" BO_ 342 1;
BA_ "GenMsgSendType" BO_ 335 1;
BA_ "GenMsgSendType" BO_ 334 1;
BA_ "GenMsgSendType" BO_ 333 1;
BA_ "GenMsgSendType" BO_ 332 1;
BA_ "GenMsgSendType" BO_ 331 1;
BA_ "GenSigSendType" SG_ 3221225472 CAN_SERV_ALIGN_UPDATES_DONE 1;
BA_ "GenSigCmt" SG_ 3221225472 CAN_SERV_ALIGN_UPDATES_DONE "Number of service alignment updates done";
BA_ "GenSigStartValue" SG_ 3221225472 CAN_SENSOR_VANGLE_OFFSET 128;
BA_ "GenSigCmt" SG_ 3221225472 CAN_SENSOR_VANGLE_OFFSET "Sensor angle vertical offset verification signal of CAN_ANGLE_MOUNTING_VOFFSET";
BA_ "GenSigCmt" SG_ 3221225472 CAN_SENSOR_FOV_VER "Sensor vertical field of view";
BA_ "GenSigCmt" SG_ 3221225472 CAN_AUTO_ALIGN_VANGLE_QF "Auto alignment angle validity";
BA_ "GenSigVtName" SG_ 3221225472 CAN_AUTO_ALIGN_VANGLE_QF "VtSig_CAN_AUTO_ALIGN_VANGLE_QF";
BA_ "GenSigVtEn" SG_ 3221225472 CAN_AUTO_ALIGN_VANGLE_QF "TRUE";
BA_ "GenSigCmt" SG_ 3221225472 CAN_AUTO_ALIGN_VANGLE_REF "Reference auto-alignment vertical angle";
BA_ "GenSigStartValue" SG_ 3221225472 CAN_AUTO_ALIGN_VANGLE_REF 320;
BA_ "GenSigCmt" SG_ 3221225472 CAN_AUTO_ALIGN_VANGLE "Auto-alignment vertical angle";
BA_ "GenSigStartValue" SG_ 3221225472 CAN_AUTO_ALIGN_VANGLE 320;
BA_ "GenSigStartValue" SG_ 3221225472 CAN_MMIC_Temp4 50;
BA_ "GenSigCmt" SG_ 3221225472 CAN_MMIC_Temp4 "Internal MMIC Temperature #3";
BA_ "GenSigStartValue" SG_ 3221225472 CAN_MMIC_Temp3 50;
BA_ "GenSigCmt" SG_ 3221225472 CAN_MMIC_Temp3 "Internal MMIC Temperature #2";
BA_ "GenSigStartValue" SG_ 3221225472 CAN_MMIC_Temp2 50;
BA_ "GenSigCmt" SG_ 3221225472 CAN_MMIC_Temp2 "Internal MMIC Temperature #1";
BA_ "GenSigStartValue" SG_ 3221225472 CAN_Processor_Temp2 50;
BA_ "GenSigCmt" SG_ 3221225472 CAN_Processor_Temp2 "Internal Micro Temperature 2";
BA_ "GenSigCmt" SG_ 3221225472 CAN_CHECKSUM "Checksum to verify against corruption of data";
BA_ "GenSigCmt" SG_ 3221225472 CAN_COUNTER "Counter for an Autosar system that increases every time a message is receive";
BA_ "GenSigVtName" SG_ 3221225472 CAN_VEHICLE_MODE "VtSig_CAN_VEHICLE_MODE";
BA_ "GenSigVtEn" SG_ 3221225472 CAN_VEHICLE_MODE "TRUE";
BA_ "GenSigCmt" SG_ 3221225472 CAN_VEHICLE_MODE "Signal to set the power mode of the vehicle (radar and camera)";
BA_ "GenSigCmt" SG_ 3221225472 CAN_USC_CAL_VER_MAJOR "USC Calibration major version";
BA_ "GenSigCmt" SG_ 3221225472 CAN_USC_CAL_VER_MINOR "USC Calibration minor version";
BA_ "GenSigCmt" SG_ 3221225472 CAN_SMC_CAL_VER_MAJOR "SMC Calibration major version";
BA_ "GenSigCmt" SG_ 3221225472 CAN_HW_VERSION "Hardware release version";
BA_ "GenSigStartValue" SG_ 3221225472 CAN_FAC_TGT_MTG_SPACE_VER 128;
BA_ "GenSigSendType" SG_ 3221225472 CAN_FAC_TGT_MTG_SPACE_VER 1;
BA_ "GenSigCmt" SG_ 3221225472 CAN_FAC_TGT_MTG_SPACE_VER "Vertical distance above and below of radar bore sight that two corner reflectors are placed for multiple corner reflector factory alignment process";
BA_ "GenSigStartValue" SG_ 3221225472 CAN_ANGLE_MISALIGNMENT_VER 320;
BA_ "GenSigCmt" SG_ 3221225472 CAN_ANGLE_MISALIGNMENT_VER "Vertical angle of misalignment";
BA_ "GenSigStartValue" SG_ 3221225472 CAN_ANGLE_MOUNTING_VOFFSET 128;
BA_ "GenSigCmt" SG_ 3221225472 CAN_ANGLE_MOUNTING_VOFFSET "Intentional vertical angle misalignment";
BA_ "GenSigCmt" SG_ 3221225472 CAN_LATCH_FAULTS "Active Latch Faults";
BA_ "GenSigCmt" SG_ 3221225472 CAN_ACTIVE_FAULTS "Active faults";
BA_ "GenSigCmt" SG_ 3221225472 CAN_HISTORY_FAULTS "History Faults";
BA_ "GenSigVtName" SG_ 3221225472 CAN_SERV_ALIGN_ENABLE "VtSig_CAN_SERV_ALIGN_ENABLE";
BA_ "GenSigVtEn" SG_ 3221225472 CAN_SERV_ALIGN_ENABLE "TRUE";
BA_ "GenSigCmt" SG_ 3221225472 CAN_SERV_ALIGN_ENABLE "Service align enable";
BA_ "GenSigStartValue" SG_ 3221225472 CAN_LONG_MOUNTING_OFFSET 128;
BA_ "GenSigSendType" SG_ 3221225472 CAN_LONG_MOUNTING_OFFSET 1;
BA_ "GenSigCmt" SG_ 3221225472 CAN_LONG_MOUNTING_OFFSET "Longitudinal mounting offset";
BA_ "GenSigSendType" SG_ 3221225472 CAN_BEAMWIDTH_VERT 1;
BA_ "GenSigCmt" SG_ 3221225472 CAN_BEAMWIDTH_VERT "Vertical beam width accounting for secondary surface effects";
BA_ "GenSigCmt" SG_ 3221225472 CAN_VEHICLE_SPEED_CALC_QF "Quality factor of the CAN_VEHICLE_SPEED_CALC";
BA_ "GenSigVtName" SG_ 3221225472 CAN_VEHICLE_SPEED_CALC_QF "VtSig_CAN_VEHICLE_SPEED_CALC_QF";
BA_ "GenSigVtEn" SG_ 3221225472 CAN_VEHICLE_SPEED_CALC_QF "TRUE";
BA_ "SystemSignalLongSymbol" SG_ 3221225472 MRR_CameraMod_SysYawRt_ValidityF "MRR_CameraMod_SysYawRt_ValidityFault";
BA_ "SystemSignalLongSymbol" SG_ 3221225472 MRR_CameraMod_CompYawRt_Validity "MRR_CameraMod_CompYawRt_ValidityFault";
BA_ "SystemSignalLongSymbol" SG_ 3221225472 MRR_Automatic_Braking_Status_CB_ "MRR_Automatic_Braking_Status_CB_MissingFault";
BA_ "GenSigCmt" SG_ 3221225472 CAN_VFP_TIMESTAMP "Timestamp from the VFP";
BA_ "GenSigCmt" SG_ 3221225472 MRR_xcp_daq_resp_byte7 "XCP DAQ response byte 7";
BA_ "GenSigSendType" SG_ 3221225472 MRR_xcp_daq_resp_byte7 1;
BA_ "GenSigCmt" SG_ 3221225472 MRR_xcp_daq_resp_byte6 "XCP DAQ response byte 6";
BA_ "GenSigSendType" SG_ 3221225472 MRR_xcp_daq_resp_byte6 1;
BA_ "GenSigCmt" SG_ 3221225472 MRR_xcp_daq_resp_byte5 "XCP DAQ response byte 5";
BA_ "GenSigSendType" SG_ 3221225472 MRR_xcp_daq_resp_byte5 1;
BA_ "GenSigCmt" SG_ 3221225472 MRR_xcp_daq_resp_byte4 "XCP DAQ response byte 4";
BA_ "GenSigSendType" SG_ 3221225472 MRR_xcp_daq_resp_byte4 1;
BA_ "GenSigCmt" SG_ 3221225472 MRR_xcp_daq_resp_byte3 "XCP DAQ response byte 3";
BA_ "GenSigSendType" SG_ 3221225472 MRR_xcp_daq_resp_byte3 1;
BA_ "GenSigCmt" SG_ 3221225472 MRR_xcp_daq_resp_byte2 "XCP DAQ response byte 2";
BA_ "GenSigSendType" SG_ 3221225472 MRR_xcp_daq_resp_byte2 1;
BA_ "GenSigCmt" SG_ 3221225472 MRR_xcp_daq_resp_byte1 "XCP DAQ response byte 1";
BA_ "GenSigSendType" SG_ 3221225472 MRR_xcp_daq_resp_byte1 1;
BA_ "GenSigCmt" SG_ 3221225472 MRR_xcp_daq_resp_byte0 "XCP DAQ response byte 0";
BA_ "GenSigSendType" SG_ 3221225472 MRR_xcp_daq_resp_byte0 1;
BA_ "GenSigCmt" SG_ 3221225472 MRR_xcp_dto_resp_byte7 "XCP DTO response byte 7";
BA_ "GenSigSendType" SG_ 3221225472 MRR_xcp_dto_resp_byte7 1;
BA_ "GenSigCmt" SG_ 3221225472 MRR_xcp_dto_resp_byte6 "XCP DTO response byte 6";
BA_ "GenSigSendType" SG_ 3221225472 MRR_xcp_dto_resp_byte6 1;
BA_ "GenSigCmt" SG_ 3221225472 MRR_xcp_dto_resp_byte5 "XCP DTO response byte 5";
BA_ "GenSigSendType" SG_ 3221225472 MRR_xcp_dto_resp_byte5 1;
BA_ "GenSigCmt" SG_ 3221225472 MRR_xcp_dto_resp_byte4 "XCP DTO response byte 4";
BA_ "GenSigSendType" SG_ 3221225472 MRR_xcp_dto_resp_byte4 1;
BA_ "GenSigCmt" SG_ 3221225472 MRR_xcp_dto_resp_byte3 "XCP DTO response byte 3";
BA_ "GenSigSendType" SG_ 3221225472 MRR_xcp_dto_resp_byte3 1;
BA_ "GenSigCmt" SG_ 3221225472 MRR_xcp_dto_resp_byte2 "XCP DTO response byte 2";
BA_ "GenSigSendType" SG_ 3221225472 MRR_xcp_dto_resp_byte2 1;
BA_ "GenSigCmt" SG_ 3221225472 MRR_xcp_dto_resp_byte1 "XCP DTO response byte 1";
BA_ "GenSigSendType" SG_ 3221225472 MRR_xcp_dto_resp_byte1 1;
BA_ "GenSigCmt" SG_ 3221225472 MRR_xcp_dto_resp_byte0 "XCP DTO response byte 0";
BA_ "GenSigSendType" SG_ 3221225472 MRR_xcp_dto_resp_byte0 1;
BA_ "GenSigCmt" SG_ 3221225472 MRR_xcp_dto_cmd_byte7 "XCP DTO request byte 7";
BA_ "GenSigSendType" SG_ 3221225472 MRR_xcp_dto_cmd_byte7 1;
BA_ "GenSigCmt" SG_ 3221225472 MRR_xcp_dto_cmd_byte6 "XCP DTO request byte 6";
BA_ "GenSigSendType" SG_ 3221225472 MRR_xcp_dto_cmd_byte6 1;
BA_ "GenSigCmt" SG_ 3221225472 MRR_xcp_dto_cmd_byte5 "XCP DTO request byte 5";
BA_ "GenSigSendType" SG_ 3221225472 MRR_xcp_dto_cmd_byte5 1;
BA_ "GenSigCmt" SG_ 3221225472 MRR_xcp_dto_cmd_byte4 "XCP DTO request byte 4";
BA_ "GenSigSendType" SG_ 3221225472 MRR_xcp_dto_cmd_byte4 1;
BA_ "GenSigCmt" SG_ 3221225472 MRR_xcp_dto_cmd_byte3 "XCP DTO request byte 3";
BA_ "GenSigSendType" SG_ 3221225472 MRR_xcp_dto_cmd_byte3 1;
BA_ "GenSigCmt" SG_ 3221225472 MRR_xcp_dto_cmd_byte2 "XCP DTO request byte 2";
BA_ "GenSigSendType" SG_ 3221225472 MRR_xcp_dto_cmd_byte2 1;
BA_ "GenSigCmt" SG_ 3221225472 MRR_xcp_dto_cmd_byte1 "XCP DTO request byte 1";
BA_ "GenSigSendType" SG_ 3221225472 MRR_xcp_dto_cmd_byte1 1;
BA_ "GenSigCmt" SG_ 3221225472 MRR_xcp_dto_cmd_byte0 "XCP DTO request byte 0";
BA_ "GenSigSendType" SG_ 3221225472 MRR_xcp_dto_cmd_byte0 1;
BA_ "GenSigCmt" SG_ 3221225472 MRR_xcp_cto_resp_byte7 "XCP CTO response byte 7";
BA_ "GenSigSendType" SG_ 3221225472 MRR_xcp_cto_resp_byte7 1;
BA_ "GenSigCmt" SG_ 3221225472 MRR_xcp_cto_resp_byte6 "XCP CTO response byte 6";
BA_ "GenSigSendType" SG_ 3221225472 MRR_xcp_cto_resp_byte6 1;
BA_ "GenSigCmt" SG_ 3221225472 MRR_xcp_cto_resp_byte5 "XCP CTO response byte 5";
BA_ "GenSigSendType" SG_ 3221225472 MRR_xcp_cto_resp_byte5 1;
BA_ "GenSigCmt" SG_ 3221225472 MRR_xcp_cto_resp_byte4 "XCP CTO response byte 4";
BA_ "GenSigSendType" SG_ 3221225472 MRR_xcp_cto_resp_byte4 1;
BA_ "GenSigCmt" SG_ 3221225472 MRR_xcp_cto_resp_byte3 "XCP CTO response byte 3";
BA_ "GenSigSendType" SG_ 3221225472 MRR_xcp_cto_resp_byte3 1;
BA_ "GenSigCmt" SG_ 3221225472 MRR_xcp_cto_resp_byte2 "XCP CTO response byte 2";
BA_ "GenSigSendType" SG_ 3221225472 MRR_xcp_cto_resp_byte2 1;
BA_ "GenSigCmt" SG_ 3221225472 MRR_xcp_cto_resp_byte1 "XCP CTO response byte 1";
BA_ "GenSigSendType" SG_ 3221225472 MRR_xcp_cto_resp_byte1 1;
BA_ "GenSigCmt" SG_ 3221225472 MRR_xcp_cto_resp_byte0 "XCP CTO response byte 0";
BA_ "GenSigSendType" SG_ 3221225472 MRR_xcp_cto_resp_byte0 1;
BA_ "GenSigCmt" SG_ 3221225472 MRR_xcp_cto_cmd_byte7 "XCP CTO request byte 7";
BA_ "GenSigSendType" SG_ 3221225472 MRR_xcp_cto_cmd_byte7 1;
BA_ "GenSigCmt" SG_ 3221225472 MRR_xcp_cto_cmd_byte6 "XCP CTO request byte 6";
BA_ "GenSigSendType" SG_ 3221225472 MRR_xcp_cto_cmd_byte6 1;
BA_ "GenSigCmt" SG_ 3221225472 MRR_xcp_cto_cmd_byte5 "XCP CTO request byte 5";
BA_ "GenSigSendType" SG_ 3221225472 MRR_xcp_cto_cmd_byte5 1;
BA_ "GenSigCmt" SG_ 3221225472 MRR_xcp_cto_cmd_byte4 "XCP CTO request byte 4";
BA_ "GenSigSendType" SG_ 3221225472 MRR_xcp_cto_cmd_byte4 1;
BA_ "GenSigCmt" SG_ 3221225472 MRR_xcp_cto_cmd_byte3 "XCP CTO request byte 3";
BA_ "GenSigSendType" SG_ 3221225472 MRR_xcp_cto_cmd_byte3 1;
BA_ "GenSigCmt" SG_ 3221225472 MRR_xcp_cto_cmd_byte2 "XCP CTO request byte 2";
BA_ "GenSigSendType" SG_ 3221225472 MRR_xcp_cto_cmd_byte2 1;
BA_ "GenSigCmt" SG_ 3221225472 MRR_xcp_cto_cmd_byte1 "XCP CTO request byte 1";
BA_ "GenSigSendType" SG_ 3221225472 MRR_xcp_cto_cmd_byte1 1;
BA_ "GenSigCmt" SG_ 3221225472 MRR_xcp_cto_cmd_byte0 "XCP CTO request byte 0";
BA_ "GenSigSendType" SG_ 3221225472 MRR_xcp_cto_cmd_byte0 1;
BA_ "GenSigSendType" SG_ 3221225472 TesterFunctionalReq 3;
BA_ "GenSigCmt" SG_ 3221225472 TesterFunctionalReq "Functional request";
BA_ "GenSigSendType" SG_ 3221225472 TesterPhysicalResCCM 3;
BA_ "GenSigCmt" SG_ 3221225472 TesterPhysicalResCCM "Physical response";
BA_ "GenSigSendType" SG_ 3221225472 TesterPhysicalReqCCM 3;
BA_ "GenSigCmt" SG_ 3221225472 TesterPhysicalReqCCM "Physical request";
BA_ "GenSigVtEn" SG_ 3221225472 CAN_SPEED_FRONT_LEFT_WHEEL "TRUE";
BA_ "GenSigVtName" SG_ 3221225472 CAN_SPEED_FRONT_LEFT_WHEEL "VtSig_CAN_SPEED_FRONT_LEFT_WHEEL";
BA_ "GenSigCmt" SG_ 3221225472 CAN_SPEED_FRONT_LEFT_WHEEL "Speed front left wheel";
BA_ "GenSigVtEn" SG_ 3221225472 CAN_SPEED_FRONT_RIGHT_WHEEL "TRUE";
BA_ "GenSigVtName" SG_ 3221225472 CAN_SPEED_FRONT_RIGHT_WHEEL "VtSig_CAN_SPEED_FRONT_RIGHT_WHEEL";
BA_ "GenSigCmt" SG_ 3221225472 CAN_SPEED_FRONT_RIGHT_WHEEL "Speed front right wheel";
BA_ "GenSigVtEn" SG_ 3221225472 CAN_SPEED_REAR_LEFT_WHEEL "TRUE";
BA_ "GenSigVtName" SG_ 3221225472 CAN_SPEED_REAR_LEFT_WHEEL "VtSig_CAN_SPEED_REAR_LEFT_WHEEL";
BA_ "GenSigCmt" SG_ 3221225472 CAN_SPEED_REAR_LEFT_WHEEL "Speed rear left wheel";
BA_ "GenSigVtEn" SG_ 3221225472 CAN_SPEED_REAR_RIGHT_WHEEL "TRUE";
BA_ "GenSigVtName" SG_ 3221225472 CAN_SPEED_REAR_RIGHT_WHEEL "VtSig_CAN_SPEED_REAR_RIGHT_WHEEL";
BA_ "GenSigCmt" SG_ 3221225472 CAN_SPEED_REAR_RIGHT_WHEEL "Speed rear right wheel";
BA_ "GenSigVtEn" SG_ 3221225472 Yaw_Rate_Reference_Valid "TRUE";
BA_ "GenSigVtName" SG_ 3221225472 Yaw_Rate_Reference_Valid "VtSig_Yaw_Rate_Reference_Valid";
BA_ "GenSigCmt" SG_ 3221225472 Yaw_Rate_Reference_Valid "yaw rate reference validity";
BA_ "GenSigCmt" SG_ 3221225472 Yaw_Rate_Reference "Yaw rate reference";
BA_ "GenSigVtEn" SG_ 3221225472 CAN_VEH_LONG_ACCEL_QF "TRUE";
BA_ "GenSigVtName" SG_ 3221225472 CAN_VEH_LONG_ACCEL_QF "VtSig_CAN_VEH_LONG_ACCEL_QF";
BA_ "GenSigCmt" SG_ 3221225472 CAN_VEH_LONG_ACCEL_QF "Vehicle longitudinal acceleration quality factor";
BA_ "GenSigStartValue" SG_ 3221225472 CAN_VEH_LONG_ACCEL 4000;
BA_ "GenSigCmt" SG_ 3221225472 CAN_VEH_LONG_ACCEL "Vehicle longitudinal acceleration";
BA_ "GenSigVtName" SG_ 3221225472 FSM_Yaw_Rate_Valid "FSM_Yaw_Rate_Valid";
BA_ "GenSigVtEn" SG_ 3221225472 FSM_Yaw_Rate_Valid "TRUE";
BA_ "GenSigCmt" SG_ 3221225472 FSM_Yaw_Rate_Valid "Yaw rate QF";
BA_ "GenSigCmt" SG_ 3221225472 FSM_Yaw_Rate "Yaw rate";
BA_ "GenSigCmt" SG_ 3221225472 CAN_VEHICLE_INDEX_4FA "Vehicle index";
BA_ "GenSigCmt" SG_ 3221225472 FSM_Vehicle_Velocity "Vehicle velocity";
BA_ "GenSigVtEn" SG_ 3221225472 CAN_STEERING_WHL_ANGLE_QF "TRUE";
BA_ "GenSigVtName" SG_ 3221225472 CAN_STEERING_WHL_ANGLE_QF "VtSig_CAN_STEERING_WHL_ANGLE_QF";
BA_ "GenSigCmt" SG_ 3221225472 CAN_STEERING_WHL_ANGLE_QF "Steering wheel angle quality factor";
BA_ "GenSigVtEn" SG_ 3221225472 FSM_Vehicle_Velocity_Valid "TRUE";
BA_ "GenSigVtName" SG_ 3221225472 FSM_Vehicle_Velocity_Valid "VtSig_FSM_Vehicle_Velocity_Valid";
BA_ "GenSigCmt" SG_ 3221225472 FSM_Vehicle_Velocity_Valid "Vehicle velocity validity";
BA_ "GenSigStartValue" SG_ 3221225472 CAN_STEERING_WHL_ANGLE 16000;
BA_ "GenSigCmt" SG_ 3221225472 CAN_STEERING_WHL_ANGLE "Steering wheel angle";
BA_ "GenSigVtEn" SG_ 3221225472 CAN_FCW_SENSITIVITY_LEVEL "TRUE";
BA_ "GenSigVtName" SG_ 3221225472 CAN_FCW_SENSITIVITY_LEVEL "VtSig_CAN_FCW_SENSITIVITY_LEVEL";
BA_ "GenSigCmt" SG_ 3221225472 CAN_FCW_SENSITIVITY_LEVEL "FCW sensitivity level";
BA_ "GenSigVtEn" SG_ 3221225472 CAN_VEHICLE_STATIONARY "TRUE";
BA_ "GenSigVtName" SG_ 3221225472 CAN_VEHICLE_STATIONARY "VtSig_CAN_VEHICLE_STATIONARY";
BA_ "GenSigCmt" SG_ 3221225472 CAN_VEHICLE_STATIONARY "Vehicle Stationary Status";
BA_ "GenSigCmt" SG_ 3221225472 CAN_INTF_MINOR_VERSION "CAN minor version";
BA_ "GenSigCmt" SG_ 3221225472 CAN_INTF_MAJOR_VERSION "CAN major version";
BA_ "GenSigVtEn" SG_ 3221225472 CAN_BRAKE_PEDAL "TRUE";
BA_ "GenSigVtName" SG_ 3221225472 CAN_BRAKE_PEDAL "VtSig_CAN_BRAKE_PEDAL";
BA_ "GenSigCmt" SG_ 3221225472 CAN_BRAKE_PEDAL "Brake pedal";
BA_ "GenSigCmt" SG_ 3221225472 CAN_HIGH_WHEEL_SLIP "High wheel slip";
BA_ "GenSigVtEn" SG_ 3221225472 CAN_TURN_SIGNAL_STATUS "TRUE";
BA_ "GenSigVtName" SG_ 3221225472 CAN_TURN_SIGNAL_STATUS "VtSig_CAN_TURN_SIGNALS_STATUS";
BA_ "GenSigCmt" SG_ 3221225472 CAN_TURN_SIGNAL_STATUS "Turn signal status";
BA_ "GenSigVtEn" SG_ 3221225472 CAN_WASHER_FRONT_CMD "TRUE";
BA_ "GenSigVtName" SG_ 3221225472 CAN_WASHER_FRONT_CMD "VtSig_CAN_WASHER_FRONT_CMD";
BA_ "GenSigCmt" SG_ 3221225472 CAN_WASHER_FRONT_CMD "Washer front command";
BA_ "GenSigVtEn" SG_ 3221225472 CAN_WIPER_FRONT_CMD "TRUE";
BA_ "GenSigVtName" SG_ 3221225472 CAN_WIPER_FRONT_CMD "VtSig_CAN_WIPER_FRONT_CMD";
BA_ "GenSigCmt" SG_ 3221225472 CAN_WIPER_FRONT_CMD "Wiper from command";
BA_ "GenSigVtEn" SG_ 3221225472 CAN_WIPER_SPEED_INFO "TRUE";
BA_ "GenSigVtName" SG_ 3221225472 CAN_WIPER_SPEED_INFO "VtSig_CAN_WIPER_SPEED_INFO";
BA_ "GenSigCmt" SG_ 3221225472 CAN_WIPER_SPEED_INFO "Wiper speed information";
BA_ "GenSigCmt" SG_ 3221225472 CAN_REVERSE_GEAR "Reverse gear";
BA_ "GenSigVtEn" SG_ 3221225472 CAN_BEAM_SHAPE_ACTUAL_RIGHT "TRUE";
BA_ "GenSigVtName" SG_ 3221225472 CAN_BEAM_SHAPE_ACTUAL_RIGHT "VtSig_CAN_BEAM_SHAPE_ACTUAL_RIGHT";
BA_ "GenSigCmt" SG_ 3221225472 CAN_BEAM_SHAPE_ACTUAL_RIGHT "Beam shape right";
BA_ "GenSigVtEn" SG_ 3221225472 CAN_BEAM_SHAPE_ACTUAL_LEFT "TRUE";
BA_ "GenSigVtName" SG_ 3221225472 CAN_BEAM_SHAPE_ACTUAL_LEFT "VtSig_CAN_BEAM_SHAPE_ACTUAL_LEFT";
BA_ "GenSigCmt" SG_ 3221225472 CAN_BEAM_SHAPE_ACTUAL_LEFT "Beam shape left";
BA_ "GenSigVtEn" SG_ 3221225472 CAN_MAIN_BEAM_INDICATION "TRUE";
BA_ "GenSigVtName" SG_ 3221225472 CAN_MAIN_BEAM_INDICATION "VtSig_CAN_MAIN_BEAM_INDICATOR";
BA_ "GenSigCmt" SG_ 3221225472 CAN_MAIN_BEAM_INDICATION "Main beam indication";
BA_ "GenSigCmt" SG_ 3221225472 CAN_VEHICLE_INDEX "Vehicle index";
BA_ "GenSigCmt" SG_ 3221225472 CAN_SEQUENCE_NUMBER "Sequence number";
BA_ "GenSigCmt" SG_ 3221225472 CAN_SERIAL_NUMBER "Serial number in BCD format ";
BA_ "GenSigSendType" SG_ 3221225472 CAN_INST_MODE 1;
BA_ "GenSigVtEn" SG_ 3221225472 CAN_INST_MODE "TRUE";
BA_ "GenSigVtName" SG_ 3221225472 CAN_INST_MODE "VtSig_CAN_INST_MODE";
BA_ "GenSigCmt" SG_ 3221225472 CAN_INST_MODE "Instrumentation mode";
BA_ "GenSigCmt" SG_ 3221225472 CAN_SW_Version "Host (Racerunner) version (all Cores)";
BA_ "GenSigSendType" SG_ 3221225472 CAN_SW_Version 1;
BA_ "GenSigCmt" SG_ 3221225472 CAN_PBL_Version "Primary Bootloader version";
BA_ "GenSigSendType" SG_ 3221225472 CAN_PBL_Version 1;
BA_ "GenSigCmt" SG_ 3221225472 CAN_YAW_RATE_CALC_QF "Quality factor of the CAN_YAW_RATE_CALC signal";
BA_ "GenSigVtName" SG_ 3221225472 CAN_YAW_RATE_CALC_QF "VtSig_CAN_YAW_RATE_CALC_QF";
BA_ "GenSigVtEn" SG_ 3221225472 CAN_YAW_RATE_CALC_QF "TRUE";
BA_ "GenSigStartValue" SG_ 3221225472 CAN_YAW_RATE_CALC 3200;
BA_ "GenSigCmt" SG_ 3221225472 CAN_YAW_RATE_CALC "Contains the bias-compensated yaw rate";
BA_ "GenSigStartValue" SG_ 3221225472 CAN_YAW_RATE_BIAS 512;
BA_ "GenSigCmt" SG_ 3221225472 CAN_YAW_RATE_BIAS "Yaw rate bias";
BA_ "GenSigCmt" SG_ 3221225472 CAN_VEHICLE_SPEED_CALC "Contains the compensated vehicle speed used within the MRR";
BA_ "GenSigCmt" SG_ 3221225472 CAN_VEH_SPD_COMP_FACTOR "Compensated vehicle speed factor";
BA_ "GenSigStartValue" SG_ 3221225472 CAN_VEH_SPD_COMP_FACTOR 32768;
BA_ "GenSigVtEn" SG_ 3221225472 CAN_LROS_CARCFGVEHTYPE_FORD "TRUE";
BA_ "GenSigVtName" SG_ 3221225472 CAN_LROS_CARCFGVEHTYPE_FORD "VtSig_CAN_LROS_CARCFGVEHTYPE_FORD";
BA_ "GenSigCmt" SG_ 3221225472 CAN_LROS_CARCFGVEHTYPE_FORD "Vehicle type";
BA_ "GenSigVtEn" SG_ 3221225472 CAN_LROS_CARCFGENGINE_FORD "TRUE";
BA_ "GenSigVtName" SG_ 3221225472 CAN_LROS_CARCFGENGINE_FORD "VtSig_CAN_LROS_CARCFGENGINE_FORD";
BA_ "GenSigCmt" SG_ 3221225472 CAN_LROS_CARCFGENGINE_FORD "Engine type";
BA_ "GenSigCmt" SG_ 3221225472 CAN_NUMBER_OF_TRACKS_STAT "Number of tracks sent stationary";
BA_ "GenSigCmt" SG_ 3221225472 CAN_NUMBER_OF_TRACKS_MOV "Number of tracks sent moving";
BA_ "GenSigCmt" SG_ 3221225472 CAN_TD_SCAN_COUNTER "Track drop scan counter";
BA_ "GenSigVtEn" SG_ 3221225472 CAN_FOUND_TARGET "TRUE";
BA_ "GenSigVtName" SG_ 3221225472 CAN_FOUND_TARGET "VtSig_CAN_FOUND_TARGET";
BA_ "GenSigCmt" SG_ 3221225472 CAN_FOUND_TARGET "Found target flag";
BA_ "GenSigVtEn" SG_ 3221225472 CAN_BLOCKAGE_TD "TRUE";
BA_ "GenSigVtName" SG_ 3221225472 CAN_BLOCKAGE_TD "VtSig_CAN_BLOCKAGE_TD";
BA_ "GenSigCmt" SG_ 3221225472 CAN_BLOCKAGE_TD "TD blockage flag";
BA_ "GenSigCmt" SG_ 3221225472 VIN_part3 "Vehicle Identification Number Part 3";
BA_ "GenSigCmt" SG_ 3221225472 VIN_part2 "Vehicle Identification Number Part 2";
BA_ "CrossOver_InfoCAN" SG_ 3221225472 VIN_part1 1;
BA_ "GenSigCmt" SG_ 3221225472 VIN_part1 "Vehicle Identification Number Part 1";
BA_ "GenSigCmt" SG_ 3221225472 CAN_ODOMETER_FORD "Odometer";
BA_ "GenSigVtName" SG_ 3221225472 CAN_ODOMETER_FORD "VtSig_CAN_ODOMETER_FORD";
BA_ "GenSigVtEn" SG_ 3221225472 CAN_ODOMETER_FORD "TRUE";
BA_ "CrossOver_InfoCAN" SG_ 3221225472 CAN_ODOMETER_FORD 1;
BA_ "GenSigCmt" SG_ 3221225472 CAN_POWER_SUPP_FORD "Power Supply";
BA_ "GenSigVtEn" SG_ 3221225472 CAN_POWER_SUPP_FORD "TRUE";
BA_ "GenSigVtName" SG_ 3221225472 CAN_POWER_SUPP_FORD "VtSig_CAN_POWER_SUPP_FORD";
BA_ "CrossOver_InfoCAN" SG_ 3221225472 CAN_POWER_SUPP_FORD 1;
BA_ "GenSigTimeoutTime_OCS" SG_ 3221225472 CAN_POWER_SUPP_FORD 300;
BA_ "GenSigTimeoutTime_ABS_ESC" SG_ 3221225472 CAN_POWER_SUPP_FORD 300;
BA_ "GenSigTimeoutTime_CCM" SG_ 3221225472 CAN_POWER_SUPP_FORD 300;
BA_ "GenSigTimeoutTime_IPMA" SG_ 3221225472 CAN_POWER_SUPP_FORD 300;
BA_ "GenSigTimeoutTime_SCCM" SG_ 3221225472 CAN_POWER_SUPP_FORD 300;
BA_ "GenSigTimeoutTime_PSCM" SG_ 3221225472 CAN_POWER_SUPP_FORD 300;
BA_ "GenSigCmt" SG_ 3221225472 CAN_POWER_MOTIVE_FORD "Power Motive";
BA_ "GenSigVtName" SG_ 3221225472 CAN_POWER_MOTIVE_FORD "VtSig_CAN_POWER_MOTIVE_FORD";
BA_ "GenSigVtEn" SG_ 3221225472 CAN_POWER_MOTIVE_FORD "TRUE";
BA_ "CrossOver_InfoCAN" SG_ 3221225472 CAN_POWER_MOTIVE_FORD 1;
BA_ "GenSigTimeoutTime_OCS" SG_ 3221225472 CAN_POWER_MOTIVE_FORD 300;
BA_ "GenSigTimeoutTime_ABS_ESC" SG_ 3221225472 CAN_POWER_MOTIVE_FORD 300;
BA_ "GenSigTimeoutTime_CCM" SG_ 3221225472 CAN_POWER_MOTIVE_FORD 300;
BA_ "GenSigTimeoutTime_IPMA" SG_ 3221225472 CAN_POWER_MOTIVE_FORD 300;
BA_ "GenSigTimeoutTime_PSCM" SG_ 3221225472 CAN_POWER_MOTIVE_FORD 300;
BA_ "GenSigCmt" SG_ 3221225472 CAN_CRUISE_STATUS_FORD "Cruise Status";
BA_ "GenSigVtName" SG_ 3221225472 CAN_CRUISE_STATUS_FORD "VtSig_CAN_CRUISE_STATUS_FORD";
BA_ "GenSigVtEn" SG_ 3221225472 CAN_CRUISE_STATUS_FORD "TRUE";
BA_ "CrossOver_InfoCAN" SG_ 3221225472 CAN_CRUISE_STATUS_FORD 1;
BA_ "GenSigTimeoutTime_RCM" SG_ 3221225472 CAN_CRUISE_STATUS_FORD 300;
BA_ "GenSigTimeoutTime_ABS_ESC" SG_ 3221225472 CAN_CRUISE_STATUS_FORD 300;
BA_ "GenSigTimeoutTime_CCM" SG_ 3221225472 CAN_CRUISE_STATUS_FORD 300;
BA_ "GenSigCmt" SG_ 3221225472 CAN_VEH_BATT_VOLT "Battery Voltage";
BA_ "GenSigVtName" SG_ 3221225472 CAN_VEH_BATT_VOLT "VtSig_CAN_VEH_BATT_VOLT";
BA_ "GenSigVtEn" SG_ 3221225472 CAN_VEH_BATT_VOLT "TRUE";
BA_ "GenSigTimeoutTime_ABS_ESC" SG_ 3221225472 CAN_VEH_BATT_VOLT 300;
BA_ "GenSigCmt" SG_ 3221225472 CAN_GEAR_POSITION "Gear Position";
BA_ "GenSigVtName" SG_ 3221225472 CAN_GEAR_POSITION "VtSig_CAN_GEAR_POSITION";
BA_ "GenSigVtEn" SG_ 3221225472 CAN_GEAR_POSITION "TRUE";
BA_ "GenSigCmt" SG_ 3221225472 CAN_AMBIENT_TEMP "Ambient Temperature";
BA_ "CrossOver_InfoCAN" SG_ 3221225472 CAN_AMBIENT_TEMP 1;
BA_ "GenSigStartValue" SG_ 3221225472 CAN_AMBIENT_TEMP 512;
BA_ "GenSigCmt" SG_ 3221225472 CAN_IGN_STATUS "Ignition Status";
BA_ "GenSigVtName" SG_ 3221225472 CAN_IGN_STATUS "VtSig_CAN_IGN_STATUS";
BA_ "GenSigVtEn" SG_ 3221225472 CAN_IGN_STATUS "TRUE";
BA_ "CrossOver_InfoCAN" SG_ 3221225472 CAN_IGN_STATUS 1;
BA_ "CrossOver_LIN" SG_ 3221225472 CAN_IGN_STATUS 1;
BA_ "GenSigCmt" SG_ 3221225472 CAN_GLOBALREALTIME_FORD "Global Real Time";
BA_ "GenSigStartValue" SG_ 3221225472 CAN_GLOBALREALTIME_FORD 1;
BA_ "GenSigCmt" SG_ 3221225472 CAN_VEH_SPEED_FORD "Vehicle Speed";
BA_ "GenSigVtName" SG_ 3221225472 CAN_VEH_SPEED_FORD "VtSig_CAN_VEH_SPEED_FORD";
BA_ "GenSigVtEn" SG_ 3221225472 CAN_VEH_SPEED_FORD "TRUE";
BA_ "GenSigCmt" SG_ 3221225472 CAN_VEH_YAW_FORD "Vehicle Yaw";
BA_ "GenSigVtName" SG_ 3221225472 CAN_VEH_YAW_FORD "VtSig_CAN_VEH_YAW_FORD";
BA_ "GenSigVtEn" SG_ 3221225472 CAN_VEH_YAW_FORD "TRUE";
BA_ "GenSigStartValue" SG_ 3221225472 CAN_VEH_YAW_FORD 32500;
BA_ "GenSigCmt" SG_ 3221225472 CAN_PCAN_MINOR_IFV_VFP "PCAN protocol minor version used by the IFV";
BA_ "GenSigCmt" SG_ 3221225472 CAN_PCAN_MAJOR_IFV_VFP "PCAN protocol major version used by the IFV";
BA_ "GenSigCmt" SG_ 3221225472 CAN_PCAN_MINOR_IFV_HOST "PCAN protocol minor version used by the IFV";
BA_ "GenSigCmt" SG_ 3221225472 CAN_PCAN_MAJOR_IFV_HOST "PCAN protocol major version used by the IFV";
BA_ "GenSigCmt" SG_ 3221225472 CAN_SENSOR_POLARITY "Sensor polarity verification signal of CAN_MRR_MRR _UPSIDE_DOWN";
BA_ "GenSigSendType" SG_ 3221225472 CAN_SENSOR_POLARITY 1;
BA_ "GenSigCmt" SG_ 3221225472 CAN_SENSOR_LAT_OFFSET "Sensor latitudinal offset verification signal of CAN_LATERAL_MOUNTING_OFFSET";
BA_ "GenSigSendType" SG_ 3221225472 CAN_SENSOR_LAT_OFFSET 1;
BA_ "GenSigCmt" SG_ 3221225472 CAN_SENSOR_LONG_OFFSET "Sensor longitudinal offset verification signal of CAN_LONG_MOUNTING_OFFSET";
BA_ "GenSigSendType" SG_ 3221225472 CAN_SENSOR_LONG_OFFSET 1;
BA_ "GenSigStartValue" SG_ 3221225472 CAN_SENSOR_HANGLE_OFFSET 128;
BA_ "GenSigCmt" SG_ 3221225472 CAN_SENSOR_HANGLE_OFFSET "Sensor angle horizontal offset verification signal of CAN_ANGLE_MOUNTING_HOFFSET";
BA_ "GenSigSendType" SG_ 3221225472 CAN_SENSOR_HANGLE_OFFSET 1;
BA_ "GenSigCmt" SG_ 3221225472 CAN_SENSOR_FOV_HOR "Sensor azimuth field of view";
BA_ "GenSigSendType" SG_ 3221225472 CAN_SENSOR_FOV_HOR 1;
BA_ "GenSigStartValue" SG_ 3221225472 CAN_DOPPLER_COVERAGE 128;
BA_ "GenSigCmt" SG_ 3221225472 CAN_DOPPLER_COVERAGE "Doppler coverage area";
BA_ "GenSigSendType" SG_ 3221225472 CAN_DOPPLER_COVERAGE 1;
BA_ "GenSigCmt" SG_ 3221225472 CAN_RANGE_COVERAGE "Range coverage distance";
BA_ "GenSigSendType" SG_ 3221225472 CAN_RANGE_COVERAGE 1;
BA_ "GenSigCmt" SG_ 3221225472 CAN_AUTO_ALIGN_HANGLE_QF "Auto alignment angle validity";
BA_ "GenSigSendType" SG_ 3221225472 CAN_AUTO_ALIGN_HANGLE_QF 1;
BA_ "GenSigVtName" SG_ 3221225472 CAN_AUTO_ALIGN_HANGLE_QF "VtSig_CAN_AUTO_ALIGN_HANGLE_QF";
BA_ "GenSigVtEn" SG_ 3221225472 CAN_AUTO_ALIGN_HANGLE_QF "TRUE";
BA_ "GenSigCmt" SG_ 3221225472 CAN_ALIGNMENT_STATUS "Alignment Status reported based on the mode the system is set";
BA_ "GenSigSendType" SG_ 3221225472 CAN_ALIGNMENT_STATUS 1;
BA_ "GenSigVtName" SG_ 3221225472 CAN_ALIGNMENT_STATUS "VtSig_CAN_ALIGNMENT_STATUS";
BA_ "GenSigVtEn" SG_ 3221225472 CAN_ALIGNMENT_STATUS "TRUE";
BA_ "GenSigCmt" SG_ 3221225472 CAN_ALIGNMENT_STATE "Alignment state";
BA_ "GenSigSendType" SG_ 3221225472 CAN_ALIGNMENT_STATE 1;
BA_ "GenSigVtName" SG_ 3221225472 CAN_ALIGNMENT_STATE "VtSig_CAN_ALIGNMENT_STATE";
BA_ "GenSigVtEn" SG_ 3221225472 CAN_ALIGNMENT_STATE "TRUE";
BA_ "GenSigCmt" SG_ 3221225472 CAN_AUTO_ALIGN_HANGLE_REF "Reference auto-alignment horizontal angle";
BA_ "GenSigStartValue" SG_ 3221225472 CAN_AUTO_ALIGN_HANGLE_REF 511;
BA_ "GenSigSendType" SG_ 3221225472 CAN_AUTO_ALIGN_HANGLE_REF 1;
BA_ "GenSigCmt" SG_ 3221225472 CAN_AUTO_ALIGN_HANGLE "Auto-alignment horizontal angle";
BA_ "GenSigSendType" SG_ 3221225472 CAN_AUTO_ALIGN_HANGLE 1;
BA_ "GenSigStartValue" SG_ 3221225472 CAN_AUTO_ALIGN_HANGLE 511;
BA_ "GenSigSendType" SG_ 3221225472 CAN_DET_TIME_SINCE_MEAS 1;
BA_ "GenSigCmt" SG_ 3221225472 CAN_DET_TIME_SINCE_MEAS "Relative time from when the radar measurement was taken until the detection data is sent on CAN";
BA_ "GenSigCmt" SG_ 3221225472 CAN_SENSOR_TIME_STAMP "MRR sensor absolute time when the radar measurement was taken";
BA_ "GenSigSendType" SG_ 3221225472 CAN_SENSOR_TIME_STAMP 1;
BA_ "GenSigCmt" SG_ 3221225472 CAN_SCAN_INDEX "Scan index";
BA_ "GenSigSendType" SG_ 3221225472 CAN_SCAN_INDEX 1;
BA_ "GenSigCmt" SG_ 3221225472 CAN_NUMBER_OF_DET "Number of detections sent";
BA_ "GenSigSendType" SG_ 3221225472 CAN_NUMBER_OF_DET 1;
BA_ "GenSigCmt" SG_ 3221225472 CAN_LOOK_ID "Indicates the look type values 1 to 4 base on medium/long look and near/far look";
BA_ "GenSigSendType" SG_ 3221225472 CAN_LOOK_ID 1;
BA_ "GenSigCmt" SG_ 3221225472 CAN_LOOK_INDEX "Scan index for MRR";
BA_ "GenSigSendType" SG_ 3221225472 CAN_LOOK_INDEX 1;
BA_ "GenSigCmt" SG_ 3221225472 CAN_FAC_ALIGN_CMD_3 "Factory alignment command 3";
BA_ "GenSigSendType" SG_ 3221225472 CAN_FAC_ALIGN_CMD_3 1;
BA_ "GenSigVtName" SG_ 3221225472 CAN_FAC_ALIGN_CMD_3 "VtSig_CAN_FAC_ALIGN_CMD_3";
BA_ "GenSigVtEn" SG_ 3221225472 CAN_FAC_ALIGN_CMD_3 "TRUE";
BA_ "GenSigCmt" SG_ 3221225472 CAN_FAC_ALIGN_CMD_2 "Factory alignment command 2";
BA_ "GenSigSendType" SG_ 3221225472 CAN_FAC_ALIGN_CMD_2 1;
BA_ "GenSigVtName" SG_ 3221225472 CAN_FAC_ALIGN_CMD_2 "VtSig_CAN_FAC_ALIGN_CMD_2";
BA_ "GenSigVtEn" SG_ 3221225472 CAN_FAC_ALIGN_CMD_2 "TRUE";
BA_ "GenSigCmt" SG_ 3221225472 CAN_FAC_ALIGN_CMD_1 "Factory alignment command 1";
BA_ "GenSigSendType" SG_ 3221225472 CAN_FAC_ALIGN_CMD_1 1;
BA_ "GenSigVtName" SG_ 3221225472 CAN_FAC_ALIGN_CMD_1 "VtSig_CAN_FAC_ALIGN_CMD_1";
BA_ "GenSigVtEn" SG_ 3221225472 CAN_FAC_ALIGN_CMD_1 "TRUE";
BA_ "GenSigCmt" SG_ 3221225472 CAN_BATT_VOLTS "Battery Voltage";
BA_ "GenSigCmt" SG_ 3221225472 CAN_1_25_V "1.25V Supply Voltage";
BA_ "GenSigCmt" SG_ 3221225472 CAN_5_V "5V Supply Voltage";
BA_ "GenSigCmt" SG_ 3221225472 CAN_3_3_V_RAW "3.3V RAW Supply Voltage";
BA_ "GenSigCmt" SG_ 3221225472 CAN_3_3_V_DAC "3.3V DAC Supply Voltage";
BA_ "GenSigStartValue" SG_ 3221225472 CAN_MMIC_Temp1 50;
BA_ "GenSigCmt" SG_ 3221225472 CAN_MMIC_Temp1 "Product specific Temp Sensor";
BA_ "GenSigSendType" SG_ 3221225472 CAN_MMIC_Temp1 1;
BA_ "GenSigStartValue" SG_ 3221225472 CAN_Processor_Thermistor 50;
BA_ "GenSigCmt" SG_ 3221225472 CAN_Processor_Thermistor "On Board Thermistor Temperature";
BA_ "GenSigSendType" SG_ 3221225472 CAN_Processor_Thermistor 1;
BA_ "GenSigStartValue" SG_ 3221225472 CAN_Processor_Temp1 50;
BA_ "GenSigCmt" SG_ 3221225472 CAN_Processor_Temp1 "Internal Micro Temperature 1";
BA_ "GenSigSendType" SG_ 3221225472 CAN_Processor_Temp1 1;
BA_ "GenSigVtEn" SG_ 3221225472 CAN_VEHICLE_STAT "TRUE";
BA_ "GenSigVtName" SG_ 3221225472 CAN_VEHICLE_STAT "VtSig_CAN_VEHICLE_STAT";
BA_ "GenSigCmt" SG_ 3221225472 CAN_VEHICLE_STAT "Vehicle Stationary Status";
BA_ "GenSigVtName" SG_ 3221225472 CAN_DAY_NIGHT_STATUS "VtSig_CAN_DAY_NIGHT_STATUS";
BA_ "GenSigVtEn" SG_ 3221225472 CAN_DAY_NIGHT_STATUS "TRUE";
BA_ "GenSigCmt" SG_ 3221225472 CAN_DAY_NIGHT_STATUS "Day/night status";
BA_ "GenSigVtName" SG_ 3221225472 CAN_WIPER_STATUS "VtSig_CAN_WIPER_STATUS";
BA_ "GenSigVtEn" SG_ 3221225472 CAN_WIPER_STATUS "TRUE";
BA_ "GenSigCmt" SG_ 3221225472 CAN_WIPER_STATUS "Windshield wiper status";
BA_ "GenSigVtName" SG_ 3221225472 CAN_YAW_RATE_VALIDITY "VtSig_CAN_YAW_RATE_VALIDITY";
BA_ "GenSigVtEn" SG_ 3221225472 CAN_YAW_RATE_VALIDITY "TRUE";
BA_ "GenSigCmt" SG_ 3221225472 CAN_YAW_RATE_VALIDITY "Vehicle yaw rate validity";
BA_ "GenSigStartValue" SG_ 3221225472 CAN_YAW_RATE 2048;
BA_ "GenSigCmt" SG_ 3221225472 CAN_YAW_RATE "Vehicle yaw rate";
BA_ "GenSigVtName" SG_ 3221225472 CAN_VEHICLE_SPEED_VALIDITY "VtSig_CAN_SPEED_VALIDITY";
BA_ "GenSigVtEn" SG_ 3221225472 CAN_VEHICLE_SPEED_VALIDITY "TRUE";
BA_ "GenSigCmt" SG_ 3221225472 CAN_VEHICLE_SPEED_VALIDITY "Host vehicle speed validity";
BA_ "GenSigVtName" SG_ 3221225472 CAN_VEHICLE_SPEED_DIRECTION "VtSig_CAN_VEHICLE_SPEED_DIRECTION";
BA_ "GenSigVtEn" SG_ 3221225472 CAN_VEHICLE_SPEED_DIRECTION "TRUE";
BA_ "GenSigCmt" SG_ 3221225472 CAN_VEHICLE_SPEED_DIRECTION "Host vehicle direction";
BA_ "GenSigCmt" SG_ 3221225472 CAN_VEHICLE_SPEED "Host vehicle speed";
BA_ "GenSigVtEn" SG_ 3221225472 CAN_SENSITIVITY_PROFILE_SELECT "TRUE";
BA_ "GenSigVtName" SG_ 3221225472 CAN_SENSITIVITY_PROFILE_SELECT "VtSig_CAN_SENSITIVITY_PROFILE_SELECT";
BA_ "GenSigSendType" SG_ 3221225472 CAN_SENSITIVITY_PROFILE_SELECT 1;
BA_ "GenSigCmt" SG_ 3221225472 CAN_SENSITIVITY_PROFILE_SELECT "Sensitivity profile";
BA_ "GenSigCmt" SG_ 3221225472 CAN_STOP_FREQUENCY_FRML "Stop frequency far range medium look";
BA_ "GenSigSendType" SG_ 3221225472 CAN_STOP_FREQUENCY_FRML 1;
BA_ "GenSigCmt" SG_ 3221225472 CAN_STOP_FREQUENCY_FRLL "Stop frequency far range long look";
BA_ "GenSigSendType" SG_ 3221225472 CAN_STOP_FREQUENCY_FRLL 1;
BA_ "GenSigCmt" SG_ 3221225472 CAN_PRP_FACTOR_FRML "Pulse repetition period far range medium look";
BA_ "GenSigSendType" SG_ 3221225472 CAN_PRP_FACTOR_FRML 1;
BA_ "GenSigCmt" SG_ 3221225472 CAN_PRP_FACTOR_FRLL "Pulse repetition period far range long look";
BA_ "GenSigSendType" SG_ 3221225472 CAN_PRP_FACTOR_FRLL 1;
BA_ "GenSigCmt" SG_ 3221225472 CAN_DESIRED_SWEEP_BW_FRML "Desired BW sweep far range medium look";
BA_ "GenSigSendType" SG_ 3221225472 CAN_DESIRED_SWEEP_BW_FRML 1;
BA_ "GenSigCmt" SG_ 3221225472 CAN_DESIRED_SWEEP_BW_FRLL "Desired BW sweep far range long look";
BA_ "GenSigSendType" SG_ 3221225472 CAN_DESIRED_SWEEP_BW_FRLL 1;
BA_ "GenSigStartValue" SG_ 3221225472 CAN_LATERAL_MOUNTING_OFFSET 128;
BA_ "GenSigSendType" SG_ 3221225472 CAN_LATERAL_MOUNTING_OFFSET 1;
BA_ "GenSigCmt" SG_ 3221225472 CAN_LATERAL_MOUNTING_OFFSET "Lateral mounting offset";
BA_ "GenSigSendType" SG_ 3221225472 CAN_FAC_PLATE_TILT_NUMBER 1;
BA_ "GenSigCmt" SG_ 3221225472 CAN_FAC_PLATE_TILT_NUMBER "Current flat-plate tilt position";
BA_ "GenSigStartValue" SG_ 3221225472 CAN_FAC_PLATE_TILT_ANGLE 32;
BA_ "GenSigSendType" SG_ 3221225472 CAN_FAC_PLATE_TILT_ANGLE 1;
BA_ "GenSigCmt" SG_ 3221225472 CAN_FAC_PLATE_TILT_ANGLE "Current flat-plate tilt angle";
BA_ "GenSigSendType" SG_ 3221225472 CAN_FAC_PLATE_POSITIONS_TOTAL 1;
BA_ "GenSigCmt" SG_ 3221225472 CAN_FAC_PLATE_POSITIONS_TOTAL "Total number of flat-plate tilt positions";
BA_ "GenSigSendType" SG_ 3221225472 CAN_FAC_ALIGN_MAX_NT 1;
BA_ "GenSigCmt" SG_ 3221225472 CAN_FAC_ALIGN_MAX_NT "Number of missed targets in factory alignment process before failing";
BA_ "GenSigSendType" SG_ 3221225472 CAN_FAC_TGT_RANGE_R2M 1;
BA_ "GenSigCmt" SG_ 3221225472 CAN_FAC_TGT_RANGE_R2M "Range from radar to mirror used in two-target factory alignment routine";
BA_ "GenSigSendType" SG_ 3221225472 CAN_FAC_TGT_RANGE_M2T 1;
BA_ "GenSigCmt" SG_ 3221225472 CAN_FAC_TGT_RANGE_M2T "Range from mirror to target used in two-target factory alignment routine";
BA_ "GenSigSendType" SG_ 3221225472 CAN_FAC_TGT_RANGE_1 1;
BA_ "GenSigCmt" SG_ 3221225472 CAN_FAC_TGT_RANGE_1 "Range of target used in factory alignment routine";
BA_ "GenSigSendType" SG_ 3221225472 CAN_FAC_TGT_MTG_SPACE_HOR 1;
BA_ "GenSigStartValue" SG_ 3221225472 CAN_FAC_TGT_MTG_SPACE_HOR 128;
BA_ "GenSigCmt" SG_ 3221225472 CAN_FAC_TGT_MTG_SPACE_HOR "Lateral distance left and right of CAN_FAC_TGT_MTG_OFFSET that two corner reflectors are placed for multiple corner reflector factory alignment process";
BA_ "GenSigSendType" SG_ 3221225472 CAN_FAC_TGT_MTG_OFFSET 1;
BA_ "GenSigStartValue" SG_ 3221225472 CAN_FAC_TGT_MTG_OFFSET 128;
BA_ "GenSigCmt" SG_ 3221225472 CAN_FAC_TGT_MTG_OFFSET "Lateral distance from vehicle centerline that target is located";
BA_ "GenSigSendType" SG_ 3221225472 CAN_FAC_ALIGN_SAMP_REQ 1;
BA_ "GenSigCmt" SG_ 3221225472 CAN_FAC_ALIGN_SAMP_REQ "Number of samples needed to evaluate factory alignment";
BA_ "GenSigCmt" SG_ 3221225472 CAN_SERV_ALIGN_UPDATES_NEED "Number of service alignment updates needed";
BA_ "GenSigVtName" SG_ 3221225472 CAN_SERV_ALIGN_TYPE "VtSig_CAN_SERV_ALIGN_TYPE";
BA_ "GenSigVtEn" SG_ 3221225472 CAN_SERV_ALIGN_TYPE "TRUE";
BA_ "GenSigCmt" SG_ 3221225472 CAN_SERV_ALIGN_TYPE "Service alignment type";
BA_ "GenSigCmt" SG_ 3221225472 CAN_RADAR_HEIGHT "Radar height from ground to center of radar elevation field of view";
BA_ "GenSigCmt" SG_ 3221225472 CAN_RADAR_FOV_MR "Total field of view of the mid range mode";
BA_ "GenSigCmt" SG_ 3221225472 CAN_RADAR_FOV_LR "Total field of view of the long range mode";
BA_ "GenSigVtEn" SG_ 3221225472 CAN_ALIGN_ENABLE "TRUE";
BA_ "GenSigVtName" SG_ 3221225472 CAN_ALIGN_ENABLE "VtSig_CAN_AUTO_ALIGN_DISABLE";
BA_ "GenSigCmt" SG_ 3221225472 CAN_ALIGN_ENABLE "Auto alignment disable";
BA_ "GenSigStartValue" SG_ 3221225472 CAN_ANGLE_MOUNTING_HOFFSET 128;
BA_ "GenSigCmt" SG_ 3221225472 CAN_ANGLE_MOUNTING_HOFFSET "Intentional horizontal angle misalignment";
BA_ "GenSigCmt" SG_ 3221225472 CAN_AALIGN_AVG_CTR_TOTAL "Auto-align average counter";
BA_ "GenSigVtName" SG_ 3221225472 CAN_MRR_UPSIDE_DOWN "VtSig_CAN_MRR_UPSIDE_DOWN";
BA_ "GenSigVtEn" SG_ 3221225472 CAN_MRR_UPSIDE_DOWN "TRUE";
BA_ "GenSigCmt" SG_ 3221225472 CAN_MRR_UPSIDE_DOWN "Signal indicating the commanded radar polarity";
BA_ "GenSigCmt" SG_ 3221225472 CAN_BLOCKAGE_FILTER_OUTPUT "Side lobe blockage filter";
BA_ "GenSigStartValue" SG_ 3221225472 CAN_ANGLE_MISALIGNMENT_HOR 320;
BA_ "GenSigCmt" SG_ 3221225472 CAN_ANGLE_MISALIGNMENT_HOR "Horizontal angle of misalignment";
BA_ "GenSigVtName" SG_ 3221225472 CAN_USE_ANGLE_MISALIGNMENT "VtSig_CAN_USE_ANGLE_MISALIGNMENT";
BA_ "GenSigVtEn" SG_ 3221225472 CAN_USE_ANGLE_MISALIGNMENT "TRUE";
BA_ "GenSigCmt" SG_ 3221225472 CAN_USE_ANGLE_MISALIGNMENT "Use of alignment angle offset";
BA_ "GenSigVtName" SG_ 3221225472 CAN_BLOCKAGE_DISABLE "VtSig_CAN_BLOCKAGE_DISABLE";
BA_ "GenSigVtEn" SG_ 3221225472 CAN_BLOCKAGE_DISABLE "TRUE";
BA_ "GenSigCmt" SG_ 3221225472 CAN_BLOCKAGE_DISABLE "Blockage disable";
BA_ "GenSigCmt" SG_ 3221225472 CAN_SCAN_INDEX_ACK "Scan index acknowledgement of CAN_LOOK_INDEX";
BA_ "GenSigCmt" SG_ 3221225472 CAN_STOP_FREQUENCY_NRML "Stop frequency near range long look";
BA_ "GenSigSendType" SG_ 3221225472 CAN_STOP_FREQUENCY_NRML 1;
BA_ "GenSigCmt" SG_ 3221225472 CAN_PRP_FACTOR_NRML "Pulse repetition period near range medium look";
BA_ "GenSigSendType" SG_ 3221225472 CAN_PRP_FACTOR_NRML 1;
BA_ "GenSigCmt" SG_ 3221225472 CAN_DESIRED_SWEEP_BW_NRML "Desired BW sweep near range medium look";
BA_ "GenSigSendType" SG_ 3221225472 CAN_DESIRED_SWEEP_BW_NRML 1;
BA_ "GenSigCmt" SG_ 3221225472 CAN_RADIATION_CTRL "Radiation control to turn on/off the radar in case of a fault";
BA_ "GenSigSendType" SG_ 3221225472 CAN_RADIATION_CTRL 1;
BA_ "GenSigVtName" SG_ 3221225472 CAN_RADIATION_CTRL "VtSig_CAN_RADIATION_CTRL";
BA_ "GenSigVtEn" SG_ 3221225472 CAN_RADIATION_CTRL "TRUE";
BA_ "GenSigCmt" SG_ 3221225472 CAN_STOP_FREQUENCY_NRLL "Stop frequency near range medium look";
BA_ "GenSigSendType" SG_ 3221225472 CAN_STOP_FREQUENCY_NRLL 1;
BA_ "GenSigCmt" SG_ 3221225472 CAN_PRP_FACTOR_NRLL "Pulse repetition period near range long look";
BA_ "GenSigSendType" SG_ 3221225472 CAN_PRP_FACTOR_NRLL 1;
BA_ "GenSigCmt" SG_ 3221225472 CAN_DESIRED_SWEEP_BW_NRLL "Desired BW sweep near range long look";
BA_ "GenSigSendType" SG_ 3221225472 CAN_DESIRED_SWEEP_BW_NRLL 1;
BA_ "GenSigSendType" SG_ 3221225472 CAN_PCAN_MINOR_MRR 1;
BA_ "GenSigCmt" SG_ 3221225472 CAN_PCAN_MINOR_MRR "PCAN protocol minor version used by the MRR";
BA_ "GenSigSendType" SG_ 3221225472 CAN_PCAN_MAJOR_MRR 1;
BA_ "GenSigCmt" SG_ 3221225472 CAN_PCAN_MAJOR_MRR "PCAN protocol major version used by the MRR";
BA_ "GenSigVtName" SG_ 3221225472 CAN_RADAR_ALIGN_INCOMPLETE "VtSig_CAN_ALIGN_INCOMPLETE";
BA_ "GenSigVtEn" SG_ 3221225472 CAN_RADAR_ALIGN_INCOMPLETE "TRUE";
BA_ "GenSigCmt" SG_ 3221225472 CAN_RADAR_ALIGN_INCOMPLETE "Indication that the alignment routine has not been completed";
BA_ "GenSigVtName" SG_ 3221225472 CAN_BLOCKAGE_SIDELOBE "VtSig_CAN_BLOCKAGE_SIDELOBE";
BA_ "GenSigVtEn" SG_ 3221225472 CAN_BLOCKAGE_SIDELOBE "TRUE";
BA_ "GenSigCmt" SG_ 3221225472 CAN_BLOCKAGE_SIDELOBE "Blockage error indication";
BA_ "GenSigVtName" SG_ 3221225472 CAN_BLOCKAGE_MNR "VtSig_CAN_BLOCKAGE_MNR";
BA_ "GenSigVtEn" SG_ 3221225472 CAN_BLOCKAGE_MNR "TRUE";
BA_ "GenSigCmt" SG_ 3221225472 CAN_BLOCKAGE_MNR "Blockage error indication";
BA_ "GenSigVtName" SG_ 3221225472 CAN_RADAR_EXT_COND_NOK "VtSig_CAN_RADAR_EXT_COND_NOK";
BA_ "GenSigVtEn" SG_ 3221225472 CAN_RADAR_EXT_COND_NOK "TRUE";
BA_ "GenSigCmt" SG_ 3221225472 CAN_RADAR_EXT_COND_NOK "Set to TRUE when the MRR is not working properly because of too high temperature or insufficient power in the MRR";
BA_ "GenSigVtName" SG_ 3221225472 CAN_RADAR_ALIGN_OUT_RANGE "VtSig_CAN_RADAR_ALIGN_OUT_RANGE";
BA_ "GenSigVtEn" SG_ 3221225472 CAN_RADAR_ALIGN_OUT_RANGE "TRUE";
BA_ "GenSigCmt" SG_ 3221225472 CAN_RADAR_ALIGN_OUT_RANGE "Set to TRUE when the radar sensor cannot be aligned without mechanical adjustment of the sensor";
BA_ "GenSigVtName" SG_ 3221225472 CAN_RADAR_ALIGN_NOT_START "VtSig_CAN_RADAR_ALIGN_NOT_START";
BA_ "GenSigVtEn" SG_ 3221225472 CAN_RADAR_ALIGN_NOT_START "TRUE";
BA_ "GenSigCmt" SG_ 3221225472 CAN_RADAR_ALIGN_NOT_START "Set to TRUE as long as the radar sensor alignment has not started";
BA_ "GenSigVtName" SG_ 3221225472 CAN_RADAR_OVERHEAT_ERROR "VtSig_CAN_RADAR_OVERHEAT_ERROR";
BA_ "GenSigVtEn" SG_ 3221225472 CAN_RADAR_OVERHEAT_ERROR "TRUE";
BA_ "GenSigCmt" SG_ 3221225472 CAN_RADAR_OVERHEAT_ERROR "Indication that the sensor has detected internal temperature conditions outside of operational limits";
BA_ "GenSigVtName" SG_ 3221225472 CAN_RADAR_NOT_OP "VtSig_CAN_RADAR_NOT_OP";
BA_ "GenSigVtEn" SG_ 3221225472 CAN_RADAR_NOT_OP "TRUE";
BA_ "GenSigCmt" SG_ 3221225472 CAN_RADAR_NOT_OP "Set to TRUE when the radar system is not operational";
BA_ "GenSigVtName" SG_ 3221225472 CAN_XCVR_OPERATIONAL "VtSig_CAN_XCVR_OPERATIONAL";
BA_ "GenSigVtEn" SG_ 3221225472 CAN_XCVR_OPERATIONAL "TRUE";
BA_ "GenSigCmt" SG_ 3221225472 CAN_XCVR_OPERATIONAL "Indication that the transceiver is operational";
BA_ "GenSigCmt" SG_ 291 CAN_SNR_LEVEL_04 "Signal to noise level 04";
BA_ "GenSigSendType" SG_ 291 CAN_SNR_LEVEL_04 1;
BA_ "GenSigVtName" SG_ 291 CAN_SNR_LEVEL_04 "VtSig_CAN_SNR_LEVEL_04";
BA_ "GenSigVtEn" SG_ 291 CAN_SNR_LEVEL_04 "TRUE";
BA_ "GenSigCmt" SG_ 291 CAN_DET_SUPER_RES_TARGET_04 "Super resolution target 04";
BA_ "GenSigSendType" SG_ 291 CAN_DET_SUPER_RES_TARGET_04 1;
BA_ "GenSigCmt" SG_ 291 CAN_DET_ND_TARGET_04 "Near discrimination target 04";
BA_ "GenSigSendType" SG_ 291 CAN_DET_ND_TARGET_04 1;
BA_ "GenSigCmt" SG_ 291 CAN_DET_HOST_VEH_CLUTTER_04 "Host vehicle clutter 04";
BA_ "GenSigSendType" SG_ 291 CAN_DET_HOST_VEH_CLUTTER_04 1;
BA_ "GenSigCmt" SG_ 291 CAN_DET_VALID_LEVEL_04 "Detected object valid level 04";
BA_ "GenSigSendType" SG_ 291 CAN_DET_VALID_LEVEL_04 1;
BA_ "GenSigCmt" SG_ 291 CAN_DET_AZIMUTH_04 "Detected object azimuth position 04";
BA_ "GenSigSendType" SG_ 291 CAN_DET_AZIMUTH_04 1;
BA_ "GenSigStartValue" SG_ 291 CAN_DET_AZIMUTH_04 8194;
BA_ "GenSigCmt" SG_ 291 CAN_DET_RANGE_04 "Detected object range 04";
BA_ "GenSigSendType" SG_ 291 CAN_DET_RANGE_04 1;
BA_ "GenSigCmt" SG_ 291 CAN_DET_RANGE_RATE_04 "Detected object range rate 04";
BA_ "GenSigSendType" SG_ 291 CAN_DET_RANGE_RATE_04 1;
BA_ "GenSigStartValue" SG_ 291 CAN_DET_RANGE_RATE_04 8192;
BA_ "GenSigCmt" SG_ 291 CAN_DET_AMPLITUDE_04 "Detected object amplitude 04";
BA_ "GenSigSendType" SG_ 291 CAN_DET_AMPLITUDE_04 1;
BA_ "GenSigCmt" SG_ 291 CAN_SCAN_INDEX_2LSB_04 "The two LSB of scan index 04";
BA_ "GenSigSendType" SG_ 291 CAN_SCAN_INDEX_2LSB_04 1;
BA_ "GenSigCmt" SG_ 351 CAN_SNR_LEVEL_64 "Signal to noise level 64";
BA_ "GenSigSendType" SG_ 351 CAN_SNR_LEVEL_64 1;
BA_ "GenSigVtName" SG_ 351 CAN_SNR_LEVEL_64 "VtSig_CAN_SNR_LEVEL_64";
BA_ "GenSigVtEn" SG_ 351 CAN_SNR_LEVEL_64 "TRUE";
BA_ "GenSigCmt" SG_ 351 CAN_DET_SUPER_RES_TARGET_64 "Super resolution target 64";
BA_ "GenSigSendType" SG_ 351 CAN_DET_SUPER_RES_TARGET_64 1;
BA_ "GenSigCmt" SG_ 351 CAN_DET_ND_TARGET_64 "Near discrimination target 64";
BA_ "GenSigSendType" SG_ 351 CAN_DET_ND_TARGET_64 1;
BA_ "GenSigCmt" SG_ 351 CAN_DET_HOST_VEH_CLUTTER_64 "Host vehicle clutter 64";
BA_ "GenSigSendType" SG_ 351 CAN_DET_HOST_VEH_CLUTTER_64 1;
BA_ "GenSigCmt" SG_ 351 CAN_DET_VALID_LEVEL_64 "Detected object valid level 64";
BA_ "GenSigSendType" SG_ 351 CAN_DET_VALID_LEVEL_64 1;
BA_ "GenSigCmt" SG_ 351 CAN_DET_AZIMUTH_64 "Detected object azimuth position 64";
BA_ "GenSigSendType" SG_ 351 CAN_DET_AZIMUTH_64 1;
BA_ "GenSigStartValue" SG_ 351 CAN_DET_AZIMUTH_64 8194;
BA_ "GenSigCmt" SG_ 351 CAN_DET_RANGE_64 "Detected object range 64";
BA_ "GenSigSendType" SG_ 351 CAN_DET_RANGE_64 1;
BA_ "GenSigCmt" SG_ 351 CAN_DET_RANGE_RATE_64 "Detected object range rate 64";
BA_ "GenSigSendType" SG_ 351 CAN_DET_RANGE_RATE_64 1;
BA_ "GenSigStartValue" SG_ 351 CAN_DET_RANGE_RATE_64 8192;
BA_ "GenSigCmt" SG_ 351 CAN_DET_AMPLITUDE_64 "Detected object amplitude 64";
BA_ "GenSigSendType" SG_ 351 CAN_DET_AMPLITUDE_64 1;
BA_ "GenSigCmt" SG_ 351 CAN_SCAN_INDEX_2LSB_64 "The two LSB of scan index 64";
BA_ "GenSigSendType" SG_ 351 CAN_SCAN_INDEX_2LSB_64 1;
BA_ "GenSigCmt" SG_ 350 CAN_SNR_LEVEL_63 "Signal to noise level 63";
BA_ "GenSigSendType" SG_ 350 CAN_SNR_LEVEL_63 1;
BA_ "GenSigVtName" SG_ 350 CAN_SNR_LEVEL_63 "VtSig_CAN_SNR_LEVEL_63";
BA_ "GenSigVtEn" SG_ 350 CAN_SNR_LEVEL_63 "TRUE";
BA_ "GenSigCmt" SG_ 350 CAN_DET_SUPER_RES_TARGET_63 "Super resolution target 63";
BA_ "GenSigSendType" SG_ 350 CAN_DET_SUPER_RES_TARGET_63 1;
BA_ "GenSigCmt" SG_ 350 CAN_DET_ND_TARGET_63 "Near discrimination target 63";
BA_ "GenSigSendType" SG_ 350 CAN_DET_ND_TARGET_63 1;
BA_ "GenSigCmt" SG_ 350 CAN_DET_HOST_VEH_CLUTTER_63 "Host vehicle clutter 63";
BA_ "GenSigSendType" SG_ 350 CAN_DET_HOST_VEH_CLUTTER_63 1;
BA_ "GenSigCmt" SG_ 350 CAN_DET_VALID_LEVEL_63 "Detected object valid level 63";
BA_ "GenSigSendType" SG_ 350 CAN_DET_VALID_LEVEL_63 1;
BA_ "GenSigCmt" SG_ 350 CAN_DET_AZIMUTH_63 "Detected object azimuth position 63";
BA_ "GenSigSendType" SG_ 350 CAN_DET_AZIMUTH_63 1;
BA_ "GenSigStartValue" SG_ 350 CAN_DET_AZIMUTH_63 8194;
BA_ "GenSigCmt" SG_ 350 CAN_DET_RANGE_63 "Detected object range 63";
BA_ "GenSigSendType" SG_ 350 CAN_DET_RANGE_63 1;
BA_ "GenSigCmt" SG_ 350 CAN_DET_RANGE_RATE_63 "Detected object range rate 63";
BA_ "GenSigSendType" SG_ 350 CAN_DET_RANGE_RATE_63 1;
BA_ "GenSigStartValue" SG_ 350 CAN_DET_RANGE_RATE_63 8192;
BA_ "GenSigCmt" SG_ 350 CAN_DET_AMPLITUDE_63 "Detected object amplitude 63";
BA_ "GenSigSendType" SG_ 350 CAN_DET_AMPLITUDE_63 1;
BA_ "GenSigCmt" SG_ 350 CAN_SCAN_INDEX_2LSB_63 "The two LSB of scan index 63";
BA_ "GenSigSendType" SG_ 350 CAN_SCAN_INDEX_2LSB_63 1;
BA_ "GenSigCmt" SG_ 349 CAN_SNR_LEVEL_62 "Signal to noise level 62";
BA_ "GenSigSendType" SG_ 349 CAN_SNR_LEVEL_62 1;
BA_ "GenSigVtName" SG_ 349 CAN_SNR_LEVEL_62 "VtSig_CAN_SNR_LEVEL_62";
BA_ "GenSigVtEn" SG_ 349 CAN_SNR_LEVEL_62 "TRUE";
BA_ "GenSigCmt" SG_ 349 CAN_DET_SUPER_RES_TARGET_62 "Super resolution target 62";
BA_ "GenSigSendType" SG_ 349 CAN_DET_SUPER_RES_TARGET_62 1;
BA_ "GenSigCmt" SG_ 349 CAN_DET_ND_TARGET_62 "Near discrimination target 62";
BA_ "GenSigSendType" SG_ 349 CAN_DET_ND_TARGET_62 1;
BA_ "GenSigCmt" SG_ 349 CAN_DET_HOST_VEH_CLUTTER_62 "Host vehicle clutter 62";
BA_ "GenSigSendType" SG_ 349 CAN_DET_HOST_VEH_CLUTTER_62 1;
BA_ "GenSigCmt" SG_ 349 CAN_DET_VALID_LEVEL_62 "Detected object valid level 62";
BA_ "GenSigSendType" SG_ 349 CAN_DET_VALID_LEVEL_62 1;
BA_ "GenSigCmt" SG_ 349 CAN_DET_AZIMUTH_62 "Detected object azimuth position 62";
BA_ "GenSigSendType" SG_ 349 CAN_DET_AZIMUTH_62 1;
BA_ "GenSigStartValue" SG_ 349 CAN_DET_AZIMUTH_62 8194;
BA_ "GenSigCmt" SG_ 349 CAN_DET_RANGE_62 "Detected object range 62";
BA_ "GenSigSendType" SG_ 349 CAN_DET_RANGE_62 1;
BA_ "GenSigCmt" SG_ 349 CAN_DET_RANGE_RATE_62 "Detected object range rate 62";
BA_ "GenSigSendType" SG_ 349 CAN_DET_RANGE_RATE_62 1;
BA_ "GenSigStartValue" SG_ 349 CAN_DET_RANGE_RATE_62 8192;
BA_ "GenSigCmt" SG_ 349 CAN_DET_AMPLITUDE_62 "Detected object amplitude 62";
BA_ "GenSigSendType" SG_ 349 CAN_DET_AMPLITUDE_62 1;
BA_ "GenSigCmt" SG_ 349 CAN_SCAN_INDEX_2LSB_62 "The two LSB of scan index 62";
BA_ "GenSigSendType" SG_ 349 CAN_SCAN_INDEX_2LSB_62 1;
BA_ "GenSigCmt" SG_ 348 CAN_SNR_LEVEL_61 "Signal to noise level 61";
BA_ "GenSigSendType" SG_ 348 CAN_SNR_LEVEL_61 1;
BA_ "GenSigVtName" SG_ 348 CAN_SNR_LEVEL_61 "VtSig_CAN_SNR_LEVEL_61";
BA_ "GenSigVtEn" SG_ 348 CAN_SNR_LEVEL_61 "TRUE";
BA_ "GenSigCmt" SG_ 348 CAN_DET_SUPER_RES_TARGET_61 "Super resolution target 61";
BA_ "GenSigSendType" SG_ 348 CAN_DET_SUPER_RES_TARGET_61 1;
BA_ "GenSigCmt" SG_ 348 CAN_DET_ND_TARGET_61 "Near discrimination target 61";
BA_ "GenSigSendType" SG_ 348 CAN_DET_ND_TARGET_61 1;
BA_ "GenSigCmt" SG_ 348 CAN_DET_HOST_VEH_CLUTTER_61 "Host vehicle clutter 61";
BA_ "GenSigSendType" SG_ 348 CAN_DET_HOST_VEH_CLUTTER_61 1;
BA_ "GenSigCmt" SG_ 348 CAN_DET_VALID_LEVEL_61 "Detected object valid level 61";
BA_ "GenSigSendType" SG_ 348 CAN_DET_VALID_LEVEL_61 1;
BA_ "GenSigCmt" SG_ 348 CAN_DET_AZIMUTH_61 "Detected object azimuth position 61";
BA_ "GenSigSendType" SG_ 348 CAN_DET_AZIMUTH_61 1;
BA_ "GenSigStartValue" SG_ 348 CAN_DET_AZIMUTH_61 8194;
BA_ "GenSigCmt" SG_ 348 CAN_DET_RANGE_61 "Detected object range 61";
BA_ "GenSigSendType" SG_ 348 CAN_DET_RANGE_61 1;
BA_ "GenSigCmt" SG_ 348 CAN_DET_RANGE_RATE_61 "Detected object range rate 61";
BA_ "GenSigSendType" SG_ 348 CAN_DET_RANGE_RATE_61 1;
BA_ "GenSigStartValue" SG_ 348 CAN_DET_RANGE_RATE_61 8192;
BA_ "GenSigCmt" SG_ 348 CAN_DET_AMPLITUDE_61 "Detected object amplitude 61";
BA_ "GenSigSendType" SG_ 348 CAN_DET_AMPLITUDE_61 1;
BA_ "GenSigCmt" SG_ 348 CAN_SCAN_INDEX_2LSB_61 "The two LSB of scan index 61";
BA_ "GenSigSendType" SG_ 348 CAN_SCAN_INDEX_2LSB_61 1;
BA_ "GenSigCmt" SG_ 347 CAN_SNR_LEVEL_60 "Signal to noise level 60";
BA_ "GenSigSendType" SG_ 347 CAN_SNR_LEVEL_60 1;
BA_ "GenSigVtName" SG_ 347 CAN_SNR_LEVEL_60 "VtSig_CAN_SNR_LEVEL_60";
BA_ "GenSigVtEn" SG_ 347 CAN_SNR_LEVEL_60 "TRUE";
BA_ "GenSigCmt" SG_ 347 CAN_DET_SUPER_RES_TARGET_60 "Super resolution target 60";
BA_ "GenSigSendType" SG_ 347 CAN_DET_SUPER_RES_TARGET_60 1;
BA_ "GenSigCmt" SG_ 347 CAN_DET_ND_TARGET_60 "Near discrimination target 60";
BA_ "GenSigSendType" SG_ 347 CAN_DET_ND_TARGET_60 1;
BA_ "GenSigCmt" SG_ 347 CAN_DET_HOST_VEH_CLUTTER_60 "Host vehicle clutter 60";
BA_ "GenSigSendType" SG_ 347 CAN_DET_HOST_VEH_CLUTTER_60 1;
BA_ "GenSigCmt" SG_ 347 CAN_DET_VALID_LEVEL_60 "Detected object valid level 60";
BA_ "GenSigSendType" SG_ 347 CAN_DET_VALID_LEVEL_60 1;
BA_ "GenSigCmt" SG_ 347 CAN_DET_AZIMUTH_60 "Detected object azimuth position 60";
BA_ "GenSigSendType" SG_ 347 CAN_DET_AZIMUTH_60 1;
BA_ "GenSigStartValue" SG_ 347 CAN_DET_AZIMUTH_60 8194;
BA_ "GenSigCmt" SG_ 347 CAN_DET_RANGE_60 "Detected object range 60";
BA_ "GenSigSendType" SG_ 347 CAN_DET_RANGE_60 1;
BA_ "GenSigCmt" SG_ 347 CAN_DET_RANGE_RATE_60 "Detected object range rate 60";
BA_ "GenSigSendType" SG_ 347 CAN_DET_RANGE_RATE_60 1;
BA_ "GenSigStartValue" SG_ 347 CAN_DET_RANGE_RATE_60 8192;
BA_ "GenSigCmt" SG_ 347 CAN_DET_AMPLITUDE_60 "Detected object amplitude 60";
BA_ "GenSigSendType" SG_ 347 CAN_DET_AMPLITUDE_60 1;
BA_ "GenSigCmt" SG_ 347 CAN_SCAN_INDEX_2LSB_60 "The two LSB of scan index 60";
BA_ "GenSigSendType" SG_ 347 CAN_SCAN_INDEX_2LSB_60 1;
BA_ "GenSigCmt" SG_ 346 CAN_SNR_LEVEL_59 "Signal to noise level 59";
BA_ "GenSigSendType" SG_ 346 CAN_SNR_LEVEL_59 1;
BA_ "GenSigVtName" SG_ 346 CAN_SNR_LEVEL_59 "VtSig_CAN_SNR_LEVEL_59";
BA_ "GenSigVtEn" SG_ 346 CAN_SNR_LEVEL_59 "TRUE";
BA_ "GenSigCmt" SG_ 346 CAN_DET_SUPER_RES_TARGET_59 "Super resolution target 59";
BA_ "GenSigSendType" SG_ 346 CAN_DET_SUPER_RES_TARGET_59 1;
BA_ "GenSigCmt" SG_ 346 CAN_DET_ND_TARGET_59 "Near discrimination target 59";
BA_ "GenSigSendType" SG_ 346 CAN_DET_ND_TARGET_59 1;
BA_ "GenSigCmt" SG_ 346 CAN_DET_HOST_VEH_CLUTTER_59 "Host vehicle clutter 59";
BA_ "GenSigSendType" SG_ 346 CAN_DET_HOST_VEH_CLUTTER_59 1;
BA_ "GenSigCmt" SG_ 346 CAN_DET_VALID_LEVEL_59 "Detected object valid level 59";
BA_ "GenSigSendType" SG_ 346 CAN_DET_VALID_LEVEL_59 1;
BA_ "GenSigCmt" SG_ 346 CAN_DET_AZIMUTH_59 "Detected object azimuth position 59";
BA_ "GenSigSendType" SG_ 346 CAN_DET_AZIMUTH_59 1;
BA_ "GenSigStartValue" SG_ 346 CAN_DET_AZIMUTH_59 8194;
BA_ "GenSigCmt" SG_ 346 CAN_DET_RANGE_59 "Detected object range 59";
BA_ "GenSigSendType" SG_ 346 CAN_DET_RANGE_59 1;
BA_ "GenSigCmt" SG_ 346 CAN_DET_RANGE_RATE_59 "Detected object range rate 59";
BA_ "GenSigSendType" SG_ 346 CAN_DET_RANGE_RATE_59 1;
BA_ "GenSigStartValue" SG_ 346 CAN_DET_RANGE_RATE_59 8192;
BA_ "GenSigCmt" SG_ 346 CAN_DET_AMPLITUDE_59 "Detected object amplitude 59";
BA_ "GenSigSendType" SG_ 346 CAN_DET_AMPLITUDE_59 1;
BA_ "GenSigCmt" SG_ 346 CAN_SCAN_INDEX_2LSB_59 "The two LSB of scan index 59";
BA_ "GenSigSendType" SG_ 346 CAN_SCAN_INDEX_2LSB_59 1;
BA_ "GenSigCmt" SG_ 345 CAN_SNR_LEVEL_58 "Signal to noise level 58";
BA_ "GenSigSendType" SG_ 345 CAN_SNR_LEVEL_58 1;
BA_ "GenSigVtName" SG_ 345 CAN_SNR_LEVEL_58 "VtSig_CAN_SNR_LEVEL_58";
BA_ "GenSigVtEn" SG_ 345 CAN_SNR_LEVEL_58 "TRUE";
BA_ "GenSigCmt" SG_ 345 CAN_DET_SUPER_RES_TARGET_58 "Super resolution target 58";
BA_ "GenSigSendType" SG_ 345 CAN_DET_SUPER_RES_TARGET_58 1;
BA_ "GenSigCmt" SG_ 345 CAN_DET_ND_TARGET_58 "Near discrimination target 58";
BA_ "GenSigSendType" SG_ 345 CAN_DET_ND_TARGET_58 1;
BA_ "GenSigCmt" SG_ 345 CAN_DET_HOST_VEH_CLUTTER_58 "Host vehicle clutter 58";
BA_ "GenSigSendType" SG_ 345 CAN_DET_HOST_VEH_CLUTTER_58 1;
BA_ "GenSigCmt" SG_ 345 CAN_DET_VALID_LEVEL_58 "Detected object valid level 58";
BA_ "GenSigSendType" SG_ 345 CAN_DET_VALID_LEVEL_58 1;
BA_ "GenSigCmt" SG_ 345 CAN_DET_AZIMUTH_58 "Detected object azimuth position 58";
BA_ "GenSigSendType" SG_ 345 CAN_DET_AZIMUTH_58 1;
BA_ "GenSigStartValue" SG_ 345 CAN_DET_AZIMUTH_58 8194;
BA_ "GenSigCmt" SG_ 345 CAN_DET_RANGE_58 "Detected object range 58";
BA_ "GenSigSendType" SG_ 345 CAN_DET_RANGE_58 1;
BA_ "GenSigCmt" SG_ 345 CAN_DET_RANGE_RATE_58 "Detected object range rate 58";
BA_ "GenSigSendType" SG_ 345 CAN_DET_RANGE_RATE_58 1;
BA_ "GenSigStartValue" SG_ 345 CAN_DET_RANGE_RATE_58 8192;
BA_ "GenSigCmt" SG_ 345 CAN_DET_AMPLITUDE_58 "Detected object amplitude 58";
BA_ "GenSigSendType" SG_ 345 CAN_DET_AMPLITUDE_58 1;
BA_ "GenSigCmt" SG_ 345 CAN_SCAN_INDEX_2LSB_58 "The two LSB of scan index 58";
BA_ "GenSigSendType" SG_ 345 CAN_SCAN_INDEX_2LSB_58 1;
BA_ "GenSigCmt" SG_ 344 CAN_SNR_LEVEL_57 "Signal to noise level 57";
BA_ "GenSigSendType" SG_ 344 CAN_SNR_LEVEL_57 1;
BA_ "GenSigVtName" SG_ 344 CAN_SNR_LEVEL_57 "VtSig_CAN_SNR_LEVEL_57";
BA_ "GenSigVtEn" SG_ 344 CAN_SNR_LEVEL_57 "TRUE";
BA_ "GenSigCmt" SG_ 344 CAN_DET_SUPER_RES_TARGET_57 "Super resolution target 57";
BA_ "GenSigSendType" SG_ 344 CAN_DET_SUPER_RES_TARGET_57 1;
BA_ "GenSigCmt" SG_ 344 CAN_DET_ND_TARGET_57 "Near discrimination target 57";
BA_ "GenSigSendType" SG_ 344 CAN_DET_ND_TARGET_57 1;
BA_ "GenSigCmt" SG_ 344 CAN_DET_HOST_VEH_CLUTTER_57 "Host vehicle clutter 57";
BA_ "GenSigSendType" SG_ 344 CAN_DET_HOST_VEH_CLUTTER_57 1;
BA_ "GenSigCmt" SG_ 344 CAN_DET_VALID_LEVEL_57 "Detected object valid level 57";
BA_ "GenSigSendType" SG_ 344 CAN_DET_VALID_LEVEL_57 1;
BA_ "GenSigCmt" SG_ 344 CAN_DET_AZIMUTH_57 "Detected object azimuth position 57";
BA_ "GenSigSendType" SG_ 344 CAN_DET_AZIMUTH_57 1;
BA_ "GenSigStartValue" SG_ 344 CAN_DET_AZIMUTH_57 8194;
BA_ "GenSigCmt" SG_ 344 CAN_DET_RANGE_57 "Detected object range 57";
BA_ "GenSigSendType" SG_ 344 CAN_DET_RANGE_57 1;
BA_ "GenSigCmt" SG_ 344 CAN_DET_RANGE_RATE_57 "Detected object range rate 57";
BA_ "GenSigSendType" SG_ 344 CAN_DET_RANGE_RATE_57 1;
BA_ "GenSigStartValue" SG_ 344 CAN_DET_RANGE_RATE_57 8192;
BA_ "GenSigCmt" SG_ 344 CAN_DET_AMPLITUDE_57 "Detected object amplitude 57";
BA_ "GenSigSendType" SG_ 344 CAN_DET_AMPLITUDE_57 1;
BA_ "GenSigCmt" SG_ 344 CAN_SCAN_INDEX_2LSB_57 "The two LSB of scan index 57";
BA_ "GenSigSendType" SG_ 344 CAN_SCAN_INDEX_2LSB_57 1;
BA_ "GenSigCmt" SG_ 343 CAN_SNR_LEVEL_56 "Signal to noise level 56";
BA_ "GenSigSendType" SG_ 343 CAN_SNR_LEVEL_56 1;
BA_ "GenSigVtName" SG_ 343 CAN_SNR_LEVEL_56 "VtSig_CAN_SNR_LEVEL_56";
BA_ "GenSigVtEn" SG_ 343 CAN_SNR_LEVEL_56 "TRUE";
BA_ "GenSigCmt" SG_ 343 CAN_DET_SUPER_RES_TARGET_56 "Super resolution target 56";
BA_ "GenSigSendType" SG_ 343 CAN_DET_SUPER_RES_TARGET_56 1;
BA_ "GenSigCmt" SG_ 343 CAN_DET_ND_TARGET_56 "Near discrimination target 56";
BA_ "GenSigSendType" SG_ 343 CAN_DET_ND_TARGET_56 1;
BA_ "GenSigCmt" SG_ 343 CAN_DET_HOST_VEH_CLUTTER_56 "Host vehicle clutter 56";
BA_ "GenSigSendType" SG_ 343 CAN_DET_HOST_VEH_CLUTTER_56 1;
BA_ "GenSigCmt" SG_ 343 CAN_DET_VALID_LEVEL_56 "Detected object valid level 56";
BA_ "GenSigSendType" SG_ 343 CAN_DET_VALID_LEVEL_56 1;
BA_ "GenSigCmt" SG_ 343 CAN_DET_AZIMUTH_56 "Detected object azimuth position 56";
BA_ "GenSigSendType" SG_ 343 CAN_DET_AZIMUTH_56 1;
BA_ "GenSigStartValue" SG_ 343 CAN_DET_AZIMUTH_56 8194;
BA_ "GenSigCmt" SG_ 343 CAN_DET_RANGE_56 "Detected object range 56";
BA_ "GenSigSendType" SG_ 343 CAN_DET_RANGE_56 1;
BA_ "GenSigCmt" SG_ 343 CAN_DET_RANGE_RATE_56 "Detected object range rate 56";
BA_ "GenSigSendType" SG_ 343 CAN_DET_RANGE_RATE_56 1;
BA_ "GenSigStartValue" SG_ 343 CAN_DET_RANGE_RATE_56 8192;
BA_ "GenSigCmt" SG_ 343 CAN_DET_AMPLITUDE_56 "Detected object amplitude 56";
BA_ "GenSigSendType" SG_ 343 CAN_DET_AMPLITUDE_56 1;
BA_ "GenSigCmt" SG_ 343 CAN_SCAN_INDEX_2LSB_56 "The two LSB of scan index 56";
BA_ "GenSigSendType" SG_ 343 CAN_SCAN_INDEX_2LSB_56 1;
BA_ "GenSigCmt" SG_ 342 CAN_SNR_LEVEL_55 "Signal to noise level 55";
BA_ "GenSigSendType" SG_ 342 CAN_SNR_LEVEL_55 1;
BA_ "GenSigVtName" SG_ 342 CAN_SNR_LEVEL_55 "VtSig_CAN_SNR_LEVEL_55";
BA_ "GenSigVtEn" SG_ 342 CAN_SNR_LEVEL_55 "TRUE";
BA_ "GenSigCmt" SG_ 342 CAN_DET_SUPER_RES_TARGET_55 "Super resolution target 55";
BA_ "GenSigSendType" SG_ 342 CAN_DET_SUPER_RES_TARGET_55 1;
BA_ "GenSigCmt" SG_ 342 CAN_DET_ND_TARGET_55 "Near discrimination target 55";
BA_ "GenSigSendType" SG_ 342 CAN_DET_ND_TARGET_55 1;
BA_ "GenSigCmt" SG_ 342 CAN_DET_HOST_VEH_CLUTTER_55 "Host vehicle clutter 55";
BA_ "GenSigSendType" SG_ 342 CAN_DET_HOST_VEH_CLUTTER_55 1;
BA_ "GenSigCmt" SG_ 342 CAN_DET_VALID_LEVEL_55 "Detected object valid level 55";
BA_ "GenSigSendType" SG_ 342 CAN_DET_VALID_LEVEL_55 1;
BA_ "GenSigCmt" SG_ 342 CAN_DET_AZIMUTH_55 "Detected object azimuth position 55";
BA_ "GenSigSendType" SG_ 342 CAN_DET_AZIMUTH_55 1;
BA_ "GenSigStartValue" SG_ 342 CAN_DET_AZIMUTH_55 8194;
BA_ "GenSigCmt" SG_ 342 CAN_DET_RANGE_55 "Detected object range 55";
BA_ "GenSigSendType" SG_ 342 CAN_DET_RANGE_55 1;
BA_ "GenSigCmt" SG_ 342 CAN_DET_RANGE_RATE_55 "Detected object range rate 55";
BA_ "GenSigSendType" SG_ 342 CAN_DET_RANGE_RATE_55 1;
BA_ "GenSigStartValue" SG_ 342 CAN_DET_RANGE_RATE_55 8192;
BA_ "GenSigCmt" SG_ 342 CAN_DET_AMPLITUDE_55 "Detected object amplitude 55";
BA_ "GenSigSendType" SG_ 342 CAN_DET_AMPLITUDE_55 1;
BA_ "GenSigCmt" SG_ 342 CAN_SCAN_INDEX_2LSB_55 "The two LSB of scan index 55";
BA_ "GenSigSendType" SG_ 342 CAN_SCAN_INDEX_2LSB_55 1;
BA_ "GenSigCmt" SG_ 335 CAN_SNR_LEVEL_48 "Signal to noise level 48";
BA_ "GenSigSendType" SG_ 335 CAN_SNR_LEVEL_48 1;
BA_ "GenSigVtName" SG_ 335 CAN_SNR_LEVEL_48 "VtSig_CAN_SNR_LEVEL_48";
BA_ "GenSigVtEn" SG_ 335 CAN_SNR_LEVEL_48 "TRUE";
BA_ "GenSigCmt" SG_ 335 CAN_DET_SUPER_RES_TARGET_48 "Super resolution target 48";
BA_ "GenSigSendType" SG_ 335 CAN_DET_SUPER_RES_TARGET_48 1;
BA_ "GenSigCmt" SG_ 335 CAN_DET_ND_TARGET_48 "Near discrimination target 48";
BA_ "GenSigSendType" SG_ 335 CAN_DET_ND_TARGET_48 1;
BA_ "GenSigCmt" SG_ 335 CAN_DET_HOST_VEH_CLUTTER_48 "Host vehicle clutter 48";
BA_ "GenSigSendType" SG_ 335 CAN_DET_HOST_VEH_CLUTTER_48 1;
BA_ "GenSigCmt" SG_ 335 CAN_DET_VALID_LEVEL_48 "Detected object valid level 48";
BA_ "GenSigSendType" SG_ 335 CAN_DET_VALID_LEVEL_48 1;
BA_ "GenSigCmt" SG_ 335 CAN_DET_AZIMUTH_48 "Detected object azimuth position 48";
BA_ "GenSigSendType" SG_ 335 CAN_DET_AZIMUTH_48 1;
BA_ "GenSigStartValue" SG_ 335 CAN_DET_AZIMUTH_48 8194;
BA_ "GenSigCmt" SG_ 335 CAN_DET_RANGE_48 "Detected object range 48";
BA_ "GenSigSendType" SG_ 335 CAN_DET_RANGE_48 1;
BA_ "GenSigCmt" SG_ 335 CAN_DET_RANGE_RATE_48 "Detected object range rate 48";
BA_ "GenSigSendType" SG_ 335 CAN_DET_RANGE_RATE_48 1;
BA_ "GenSigStartValue" SG_ 335 CAN_DET_RANGE_RATE_48 8192;
BA_ "GenSigCmt" SG_ 335 CAN_DET_AMPLITUDE_48 "Detected object amplitude 48";
BA_ "GenSigSendType" SG_ 335 CAN_DET_AMPLITUDE_48 1;
BA_ "GenSigCmt" SG_ 335 CAN_SCAN_INDEX_2LSB_48 "The two LSB of scan index 48";
BA_ "GenSigSendType" SG_ 335 CAN_SCAN_INDEX_2LSB_48 1;
BA_ "GenSigCmt" SG_ 334 CAN_SNR_LEVEL_47 "Signal to noise level 47";
BA_ "GenSigSendType" SG_ 334 CAN_SNR_LEVEL_47 1;
BA_ "GenSigVtName" SG_ 334 CAN_SNR_LEVEL_47 "VtSig_CAN_SNR_LEVEL_47";
BA_ "GenSigVtEn" SG_ 334 CAN_SNR_LEVEL_47 "TRUE";
BA_ "GenSigCmt" SG_ 334 CAN_DET_SUPER_RES_TARGET_47 "Super resolution target 47";
BA_ "GenSigSendType" SG_ 334 CAN_DET_SUPER_RES_TARGET_47 1;
BA_ "GenSigCmt" SG_ 334 CAN_DET_ND_TARGET_47 "Near discrimination target 47";
BA_ "GenSigSendType" SG_ 334 CAN_DET_ND_TARGET_47 1;
BA_ "GenSigCmt" SG_ 334 CAN_DET_HOST_VEH_CLUTTER_47 "Host vehicle clutter 47";
BA_ "GenSigSendType" SG_ 334 CAN_DET_HOST_VEH_CLUTTER_47 1;
BA_ "GenSigCmt" SG_ 334 CAN_DET_VALID_LEVEL_47 "Detected object valid level 47";
BA_ "GenSigSendType" SG_ 334 CAN_DET_VALID_LEVEL_47 1;
BA_ "GenSigCmt" SG_ 334 CAN_DET_AZIMUTH_47 "Detected object azimuth position 47";
BA_ "GenSigSendType" SG_ 334 CAN_DET_AZIMUTH_47 1;
BA_ "GenSigStartValue" SG_ 334 CAN_DET_AZIMUTH_47 8194;
BA_ "GenSigCmt" SG_ 334 CAN_DET_RANGE_47 "Detected object range 47";
BA_ "GenSigSendType" SG_ 334 CAN_DET_RANGE_47 1;
BA_ "GenSigCmt" SG_ 334 CAN_DET_RANGE_RATE_47 "Detected object range rate 47";
BA_ "GenSigSendType" SG_ 334 CAN_DET_RANGE_RATE_47 1;
BA_ "GenSigStartValue" SG_ 334 CAN_DET_RANGE_RATE_47 8192;
BA_ "GenSigCmt" SG_ 334 CAN_DET_AMPLITUDE_47 "Detected object amplitude 47";
BA_ "GenSigSendType" SG_ 334 CAN_DET_AMPLITUDE_47 1;
BA_ "GenSigCmt" SG_ 334 CAN_SCAN_INDEX_2LSB_47 "The two LSB of scan index 47";
BA_ "GenSigSendType" SG_ 334 CAN_SCAN_INDEX_2LSB_47 1;
BA_ "GenSigCmt" SG_ 333 CAN_SNR_LEVEL_46 "Signal to noise level 46";
BA_ "GenSigSendType" SG_ 333 CAN_SNR_LEVEL_46 1;
BA_ "GenSigVtName" SG_ 333 CAN_SNR_LEVEL_46 "VtSig_CAN_SNR_LEVEL_46";
BA_ "GenSigVtEn" SG_ 333 CAN_SNR_LEVEL_46 "TRUE";
BA_ "GenSigCmt" SG_ 333 CAN_DET_SUPER_RES_TARGET_46 "Super resolution target 46";
BA_ "GenSigSendType" SG_ 333 CAN_DET_SUPER_RES_TARGET_46 1;
BA_ "GenSigCmt" SG_ 333 CAN_DET_ND_TARGET_46 "Near discrimination target 46";
BA_ "GenSigSendType" SG_ 333 CAN_DET_ND_TARGET_46 1;
BA_ "GenSigCmt" SG_ 333 CAN_DET_HOST_VEH_CLUTTER_46 "Host vehicle clutter 46";
BA_ "GenSigSendType" SG_ 333 CAN_DET_HOST_VEH_CLUTTER_46 1;
BA_ "GenSigCmt" SG_ 333 CAN_DET_VALID_LEVEL_46 "Detected object valid level 46";
BA_ "GenSigSendType" SG_ 333 CAN_DET_VALID_LEVEL_46 1;
BA_ "GenSigCmt" SG_ 333 CAN_DET_AZIMUTH_46 "Detected object azimuth position 46";
BA_ "GenSigSendType" SG_ 333 CAN_DET_AZIMUTH_46 1;
BA_ "GenSigStartValue" SG_ 333 CAN_DET_AZIMUTH_46 8194;
BA_ "GenSigCmt" SG_ 333 CAN_DET_RANGE_46 "Detected object range 46";
BA_ "GenSigSendType" SG_ 333 CAN_DET_RANGE_46 1;
BA_ "GenSigCmt" SG_ 333 CAN_DET_RANGE_RATE_46 "Detected object range rate 46";
BA_ "GenSigSendType" SG_ 333 CAN_DET_RANGE_RATE_46 1;
BA_ "GenSigStartValue" SG_ 333 CAN_DET_RANGE_RATE_46 8192;
BA_ "GenSigCmt" SG_ 333 CAN_DET_AMPLITUDE_46 "Detected object amplitude 46";
BA_ "GenSigSendType" SG_ 333 CAN_DET_AMPLITUDE_46 1;
BA_ "GenSigCmt" SG_ 333 CAN_SCAN_INDEX_2LSB_46 "The two LSB of scan index 46";
BA_ "GenSigSendType" SG_ 333 CAN_SCAN_INDEX_2LSB_46 1;
BA_ "GenSigCmt" SG_ 332 CAN_SNR_LEVEL_45 "Signal to noise level 45";
BA_ "GenSigSendType" SG_ 332 CAN_SNR_LEVEL_45 1;
BA_ "GenSigVtName" SG_ 332 CAN_SNR_LEVEL_45 "VtSig_CAN_SNR_LEVEL_45";
BA_ "GenSigVtEn" SG_ 332 CAN_SNR_LEVEL_45 "TRUE";
BA_ "GenSigCmt" SG_ 332 CAN_DET_SUPER_RES_TARGET_45 "Super resolution target 45";
BA_ "GenSigSendType" SG_ 332 CAN_DET_SUPER_RES_TARGET_45 1;
BA_ "GenSigCmt" SG_ 332 CAN_DET_ND_TARGET_45 "Near discrimination target 45";
BA_ "GenSigSendType" SG_ 332 CAN_DET_ND_TARGET_45 1;
BA_ "GenSigCmt" SG_ 332 CAN_DET_HOST_VEH_CLUTTER_45 "Host vehicle clutter 45";
BA_ "GenSigSendType" SG_ 332 CAN_DET_HOST_VEH_CLUTTER_45 1;
BA_ "GenSigCmt" SG_ 332 CAN_DET_VALID_LEVEL_45 "Detected object valid level 45";
BA_ "GenSigSendType" SG_ 332 CAN_DET_VALID_LEVEL_45 1;
BA_ "GenSigCmt" SG_ 332 CAN_DET_AZIMUTH_45 "Detected object azimuth position 45";
BA_ "GenSigSendType" SG_ 332 CAN_DET_AZIMUTH_45 1;
BA_ "GenSigStartValue" SG_ 332 CAN_DET_AZIMUTH_45 8194;
BA_ "GenSigCmt" SG_ 332 CAN_DET_RANGE_45 "Detected object range 45";
BA_ "GenSigSendType" SG_ 332 CAN_DET_RANGE_45 1;
BA_ "GenSigCmt" SG_ 332 CAN_DET_RANGE_RATE_45 "Detected object range rate 45";
BA_ "GenSigSendType" SG_ 332 CAN_DET_RANGE_RATE_45 1;
BA_ "GenSigStartValue" SG_ 332 CAN_DET_RANGE_RATE_45 8192;
BA_ "GenSigCmt" SG_ 332 CAN_DET_AMPLITUDE_45 "Detected object amplitude 45";
BA_ "GenSigSendType" SG_ 332 CAN_DET_AMPLITUDE_45 1;
BA_ "GenSigCmt" SG_ 332 CAN_SCAN_INDEX_2LSB_45 "The two LSB of scan index 45";
BA_ "GenSigSendType" SG_ 332 CAN_SCAN_INDEX_2LSB_45 1;
BA_ "GenSigCmt" SG_ 331 CAN_SNR_LEVEL_44 "Signal to noise level 44";
BA_ "GenSigSendType" SG_ 331 CAN_SNR_LEVEL_44 1;
BA_ "GenSigVtName" SG_ 331 CAN_SNR_LEVEL_44 "VtSig_CAN_SNR_LEVEL_44";
BA_ "GenSigVtEn" SG_ 331 CAN_SNR_LEVEL_44 "TRUE";
BA_ "GenSigCmt" SG_ 331 CAN_DET_SUPER_RES_TARGET_44 "Super resolution target 44";
BA_ "GenSigSendType" SG_ 331 CAN_DET_SUPER_RES_TARGET_44 1;
BA_ "GenSigCmt" SG_ 331 CAN_DET_ND_TARGET_44 "Near discrimination target 44";
BA_ "GenSigSendType" SG_ 331 CAN_DET_ND_TARGET_44 1;
BA_ "GenSigCmt" SG_ 331 CAN_DET_HOST_VEH_CLUTTER_44 "Host vehicle clutter 44";
BA_ "GenSigSendType" SG_ 331 CAN_DET_HOST_VEH_CLUTTER_44 1;
BA_ "GenSigCmt" SG_ 331 CAN_DET_VALID_LEVEL_44 "Detected object valid level 44";
BA_ "GenSigSendType" SG_ 331 CAN_DET_VALID_LEVEL_44 1;
BA_ "GenSigCmt" SG_ 331 CAN_DET_AZIMUTH_44 "Detected object azimuth position 44";
BA_ "GenSigSendType" SG_ 331 CAN_DET_AZIMUTH_44 1;
BA_ "GenSigStartValue" SG_ 331 CAN_DET_AZIMUTH_44 8194;
BA_ "GenSigCmt" SG_ 331 CAN_DET_RANGE_44 "Detected object range 44";
BA_ "GenSigSendType" SG_ 331 CAN_DET_RANGE_44 1;
BA_ "GenSigCmt" SG_ 331 CAN_DET_RANGE_RATE_44 "Detected object range rate 44";
BA_ "GenSigSendType" SG_ 331 CAN_DET_RANGE_RATE_44 1;
BA_ "GenSigStartValue" SG_ 331 CAN_DET_RANGE_RATE_44 8192;
BA_ "GenSigCmt" SG_ 331 CAN_DET_AMPLITUDE_44 "Detected object amplitude 44";
BA_ "GenSigSendType" SG_ 331 CAN_DET_AMPLITUDE_44 1;
BA_ "GenSigCmt" SG_ 331 CAN_SCAN_INDEX_2LSB_44 "The two LSB of scan index 44";
BA_ "GenSigSendType" SG_ 331 CAN_SCAN_INDEX_2LSB_44 1;
VAL_ 3221225472 CAN_AUTO_ALIGN_VANGLE_QF 1 "Alignment angle valid" 0 "Alignment angle invalid" ;
VAL_ 3221225472 CAN_VEHICLE_MODE 14 "VehicleMode_NotAvailable" 13 "VehicleMode_Error" 12 "VehicleMode_Spare_7" 11 "VehicleMode_Spare_6" 10 "VehicleMode_Spare_5" 9 "VehicleMode_Spare_4" 8 "VehicleMode_Spare_3" 7 "VehicleMode_Spare_2" 6 "VehicleMode_Spare_1" 5 "VehicleMode_Running" 4 "VehicleMode_Cranking" 3 "VehicleMode_PreRunning" 2 "VehicleMode_Accessory" 1 "VehicleMode_Parked" 0 "VehicleMode_Hibernate" ;
VAL_ 3221225472 CAN_SERV_ALIGN_ENABLE 1 "Enabled" 0 "Disabled" ;
VAL_ 3221225472 CAN_VEHICLE_SPEED_CALC_QF 3 "Accurate" 2 "Innaccurate" 1 "Temporarily Undefined" 0 "Undefined" ;
VAL_ 3221225472 AppFlashChksumFault_A_b0_0 1 "Fault_Present" 0 "No_Fault" ;
VAL_ 3221225472 CAN_SPEED_FRONT_LEFT_WHEEL 32767 "Fault" 32766 "Unknown" ;
VAL_ 3221225472 CAN_SPEED_FRONT_RIGHT_WHEEL 32767 "Fault" 32766 "Unknown" ;
VAL_ 3221225472 CAN_SPEED_REAR_LEFT_WHEEL 32767 "Fault" 32766 "Unknown" ;
VAL_ 3221225472 CAN_SPEED_REAR_RIGHT_WHEEL 32767 "Fault" 32766 "Unknown" ;
VAL_ 3221225472 Yaw_Rate_Reference_Valid 1 "Valid" 0 "Invalid" ;
VAL_ 3221225472 CAN_VEH_LONG_ACCEL_QF 3 "Accurate" 2 "Innacurate" 1 "Temporarily Undefined" 0 "Undefined (faulty)" ;
VAL_ 3221225472 FSM_Yaw_Rate_Valid 1 "Valid" 0 "Invalid" ;
VAL_ 3221225472 CAN_STEERING_WHL_ANGLE_QF 1 "Valid" 0 "Invalid" ;
VAL_ 3221225472 FSM_Vehicle_Velocity_Valid 1 "Valid" 0 "Invalid" ;
VAL_ 3221225472 CAN_FCW_SENSITIVITY_LEVEL 3 "High Sensitivity" 2 "Medium Sensitivity (Normal)" 1 "Low Sensitivity" 0 "Not Used" ;
VAL_ 3221225472 CAN_VEHICLE_STATIONARY 1 "Yes" 0 "No" ;
VAL_ 3221225472 CAN_BRAKE_PEDAL 2 "Pressed" 1 "Not Pressed" 0 "Unknown" ;
VAL_ 3221225472 CAN_TURN_SIGNAL_STATUS 3 "Left and Rigth, both on" 2 "Right" 1 "Left" 0 "None" ;
VAL_ 3221225472 CAN_WASHER_FRONT_CMD 1 "Washer is on" 0 "Washer is off" ;
VAL_ 3221225472 CAN_WIPER_FRONT_CMD 1 "Wiper On" 0 "Wiper Off" ;
VAL_ 3221225472 CAN_WIPER_SPEED_INFO 7 "Wiper system error" 6 "56-60 sweeps per min" 5 "51-55 sweeps per min" 4 "46-50 sweeps per min" 3 "40-45 sweeps per min" 2 "Intermittend High" 1 "Intermittent Low" 0 "No wiping" ;
VAL_ 3221225472 CAN_BEAM_SHAPE_ACTUAL_RIGHT 3 "low beam shape" 2 "flat shape" 1 "L shape" 0 "full shape" ;
VAL_ 3221225472 CAN_BEAM_SHAPE_ACTUAL_LEFT 3 "low beam shape" 2 "flat shape" 1 "L shape" 0 "full shape" ;
VAL_ 3221225472 CAN_MAIN_BEAM_INDICATION 1 "High beam is activated" 0 "High beam is not activated" ;
VAL_ 3221225472 CAN_INST_MODE 43605 "Instrumentation mode is set" ;
VAL_ 3221225472 CAN_YAW_RATE_CALC_QF 3 "Accurate" 2 "Innaccurate" 1 "Temporarily Undefined" 0 "Undefined" ;
VAL_ 3221225472 CAN_LROS_CARCFGVEHTYPE_FORD 12 "V363MCA" 11 "V362MCA" 10 "V408" 9 "U554" 8 "U553" 7 "C519" 6 "S552MCA" 5 "P552MCA" 4 "B562" 3 "B515" 2 "B479ST" 1 "B479" 0 "Undefined" ;
VAL_ 3221225472 CAN_LROS_CARCFGENGINE_FORD 13 "BEV" 12 "PHEV" 11 "HEV" 10 "V8_TC_or_SC" 9 "V8_NA" 8 "V6_TC_or_SC" 7 "V6_NA" 6 "I5_TC_or_SC" 5 "I5_NA" 4 "I4_TC_or_SC" 3 "I4_NA" 2 "I3_TC_or_SC" 1 "I3_NA" 0 "Undefined" ;
VAL_ 3221225472 CAN_FOUND_TARGET 1 "Target found" 0 "Target not found" ;
VAL_ 3221225472 CAN_BLOCKAGE_TD 1 "TD blockage" 0 "No blockage" ;
VAL_ 3221225472 CAN_ODOMETER_FORD 16777215 "Invalid" ;
VAL_ 3221225472 CAN_POWER_SUPP_FORD 7 "NotUsed_3" 6 "NotUsed_2" 5 "NotUsed_1" 4 "Fault_Limited" 3 "LV_Event_In_Progress" 2 "Not_Supported_Imminent" 1 "Supported" 0 "Not_Supported" ;
VAL_ 3221225472 CAN_POWER_MOTIVE_FORD 3 "PwPckOn_TqAvailable" 2 "StartInPrgrss_TqNotAvail" 1 "PwPckOn_TqNotAvailable" 0 "PwPckOff_TqNotAvailable" ;
VAL_ 3221225472 CAN_CRUISE_STATUS_FORD 7 "Undefined_2" 6 "Undefined_1" 5 "Active" 4 "Active_Que_Assist" 3 "Standby" 2 "Standby_Denied" 1 "Denied" 0 "Off" ;
VAL_ 3221225472 CAN_VEH_BATT_VOLT 255 "Fault" ;
VAL_ 3221225472 CAN_GEAR_POSITION 15 "Fault" 14 "Unknown_Position" 13 "Undefined_Treat_as_Fault" 12 "Undefined_Treat_as_Fault" 11 "sixth" 10 "fifth" 9 "fourth" 8 "third" 7 "second" 6 "first" 5 "Low" 4 "Sport_DriveSport" 3 "Drive" 2 "Neutral" 1 "Reverse" 0 "Park" ;
VAL_ 3221225472 CAN_IGN_STATUS 15 "Invalid" 8 "Start" 4 "Run" 2 "Accesory" 1 "Off" 0 "Unknown" ;
VAL_ 3221225472 CAN_VEH_SPEED_FORD 65535 "Invalid" 65534 "Unknown" ;
VAL_ 3221225472 CAN_VEH_YAW_FORD 4095 "Faulty" 4094 "NoDataExists" ;
VAL_ 3221225472 CAN_AUTO_ALIGN_HANGLE_QF 3 "Accurate" 2 "Inaccurate" 1 "Temporarily undefined" 0 "Undefined" ;
VAL_ 3221225472 CAN_ALIGNMENT_STATUS 15 "Undefined" 14 "Undefined" 13 "Low Amplitude (Flat-plate only)" 12 "No Peak (Flat-plate only)" 11 "Fail Ver and Hor OutOfRange" 10 "Fail Vertical Align OutOfRange" 9 "Fail Horizontal Align OutOfRange" 8 "Fail Time Out" 7 "Fail Only Right Target Found" 6 "Fail Only Left Target Found" 5 "Fail Variance Too Large" 4 "Fail Deviation Too Large" 3 "Fail No Target" 2 "Success" 1 "Busy" 0 "Off" ;
VAL_ 3221225472 CAN_ALIGNMENT_STATE 6 "Static alignment flat-plate" 5 "Static alignment 2-target" 4 "Static alignment 1-target" 3 "Service alignment" 2 "Short track alignment" 1 "Auto alignment" 0 "Off" ;
VAL_ 3221225472 CAN_FAC_ALIGN_CMD_3 1 "On" 0 "Off" ;
VAL_ 3221225472 CAN_FAC_ALIGN_CMD_2 1 "On" 0 "Off" ;
VAL_ 3221225472 CAN_FAC_ALIGN_CMD_1 1 "On" 0 "Off" ;
VAL_ 3221225472 CAN_VEHICLE_STAT 1 "Yes" 0 "No" ;
VAL_ 3221225472 CAN_DAY_NIGHT_STATUS 1 "Night" 0 "Day" ;
VAL_ 3221225472 CAN_WIPER_STATUS 1 "On" 0 "Off" ;
VAL_ 3221225472 CAN_YAW_RATE_VALIDITY 1 "Veh Yaw Rate Available or Valid" 0 "No Vehicle Yaw Rate or Invalid" ;
VAL_ 3221225472 CAN_VEHICLE_SPEED_VALIDITY 1 "Valid" 0 "Invalid" ;
VAL_ 3221225472 CAN_VEHICLE_SPEED_DIRECTION 1 "Reverse" 0 "Forward" ;
VAL_ 3221225472 CAN_SENSITIVITY_PROFILE_SELECT 3 "profile4" 2 "profile3" 1 "profile2" 0 "profile1" ;
VAL_ 3221225472 CAN_SERV_ALIGN_TYPE 1 "Short Track" 0 "Auto or Dealer" ;
VAL_ 3221225472 CAN_ALIGN_ENABLE 3 "Unused" 2 "Factory alignment" 1 "Service alignment" 0 "Auto alignment" ;
VAL_ 3221225472 CAN_MRR_UPSIDE_DOWN 1 "Upside_Down" 0 "Right_Side_Up" ;
VAL_ 3221225472 CAN_USE_ANGLE_MISALIGNMENT 1 "On" 0 "Off" ;
VAL_ 3221225472 CAN_BLOCKAGE_DISABLE 1 "Disabled" 0 "Enabled" ;
VAL_ 3221225472 CAN_RADIATION_CTRL 1 "On" 0 "Off" ;
VAL_ 3221225472 CAN_RADAR_ALIGN_INCOMPLETE 1 "Alignment Incomplete" 0 "Alignment Completed" ;
VAL_ 3221225472 CAN_BLOCKAGE_SIDELOBE 1 "Radar Blockage" 0 "No Radar Blockage" ;
VAL_ 3221225472 CAN_BLOCKAGE_MNR 1 "Radar Blockage" 0 "No Radar Blockage" ;
VAL_ 3221225472 CAN_RADAR_EXT_COND_NOK 1 "Too high temp or insufficient pw" 0 "External conditions OK" ;
VAL_ 3221225472 CAN_RADAR_ALIGN_OUT_RANGE 1 "Radar out of range" 0 "Radar within range" ;
VAL_ 3221225472 CAN_RADAR_ALIGN_NOT_START 1 "Radar align not started" 0 "Radar align started" ;
VAL_ 3221225472 CAN_RADAR_OVERHEAT_ERROR 1 "Radar overheat condition" 0 "No Overheat" ;
VAL_ 3221225472 CAN_RADAR_NOT_OP 1 "Radar not operational" 0 "Radar operational" ;
VAL_ 3221225472 CAN_XCVR_OPERATIONAL 1 "On" 0 "Off " ;
VAL_ 291 CAN_SNR_LEVEL_04 3 "High" 2 "Moderate" 1 "Low" 0 "Very Low" ;
VAL_ 351 CAN_SNR_LEVEL_64 3 "High" 2 "Moderate" 1 "Low" 0 "Very Low" ;
VAL_ 350 CAN_SNR_LEVEL_63 3 "High" 2 "Moderate" 1 "Low" 0 "Very Low" ;
VAL_ 349 CAN_SNR_LEVEL_62 3 "High" 2 "Moderate" 1 "Low" 0 "Very Low" ;
VAL_ 348 CAN_SNR_LEVEL_61 3 "High" 2 "Moderate" 1 "Low" 0 "Very Low" ;
VAL_ 347 CAN_SNR_LEVEL_60 3 "High" 2 "Moderate" 1 "Low" 0 "Very Low" ;
VAL_ 346 CAN_SNR_LEVEL_59 3 "High" 2 "Moderate" 1 "Low" 0 "Very Low" ;
VAL_ 345 CAN_SNR_LEVEL_58 3 "High" 2 "Moderate" 1 "Low" 0 "Very Low" ;
VAL_ 344 CAN_SNR_LEVEL_57 3 "High" 2 "Moderate" 1 "Low" 0 "Very Low" ;
VAL_ 343 CAN_SNR_LEVEL_56 3 "High" 2 "Moderate" 1 "Low" 0 "Very Low" ;
VAL_ 342 CAN_SNR_LEVEL_55 3 "High" 2 "Moderate" 1 "Low" 0 "Very Low" ;
VAL_ 335 CAN_SNR_LEVEL_48 3 "High" 2 "Moderate" 1 "Low" 0 "Very Low" ;
VAL_ 334 CAN_SNR_LEVEL_47 3 "High" 2 "Moderate" 1 "Low" 0 "Very Low" ;
VAL_ 333 CAN_SNR_LEVEL_46 3 "High" 2 "Moderate" 1 "Low" 0 "Very Low" ;
VAL_ 332 CAN_SNR_LEVEL_45 3 "High" 2 "Moderate" 1 "Low" 0 "Very Low" ;
VAL_ 331 CAN_SNR_LEVEL_44 3 "High" 2 "Moderate" 1 "Low" 0 "Very Low" ;
